[part 1 of 2: package /STLACompositions/Platform_Lin]
AUTOSAR XML (schema 00044)
package /STLACompositions/Platform_Lin
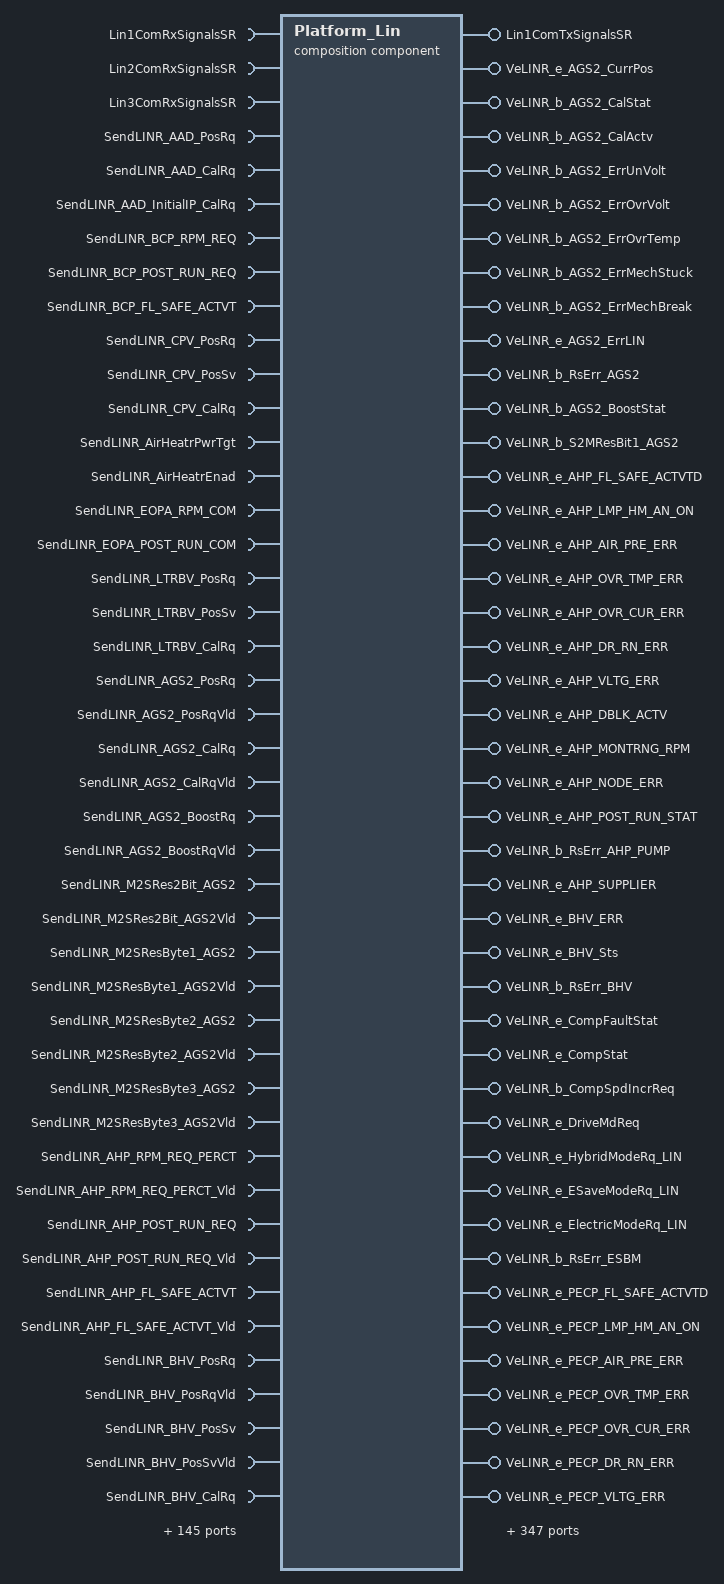
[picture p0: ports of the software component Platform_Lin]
  composition sw component type Platform_Lin: data-type-mapping=ADTtoIDTMapping  # Composition of CAN Communication Components - is a collection of Lin Communication components responsible with the management of the Lin bus and providing an abstraction layer for the Lin data to the application.
    provide port Lin1ComTxSignalsSR: provided-interface=Lin1ComTxSignalsSR
      provided-com-specs:
        data-element=COMTXL_AAD_PosRq_ECM_AAD_DEMAND_Lin1, init-value=constant-reference=COMTXL_AAD_PosRq_ECM_AAD_DEMAND_Lin1_Init
        data-element=COMTXL_AAD_CalRq_ECM_AAD_DEMAND_Lin1, init-value=constant-reference=COMTXL_AAD_CalRq_ECM_AAD_DEMAND_Lin1_Init
        data-element=COMTXL_AAD_InitialIP_CalRq_ECM_AAD_DEMAND_Lin1, init-value=constant-reference=COMTXL_AAD_InitialIP_CalRq_ECM_AAD_DEMAND_Lin1_Init
        data-element=COMTXL_BCP_RPM_REQ_BCP_REQ_Lin1, init-value=constant-reference=COMTXL_BCP_RPM_REQ_BCP_REQ_Lin1_Init
        data-element=COMTXL_BCP_POST_RUN_REQ_BCP_REQ_Lin1, init-value=constant-reference=COMTXL_BCP_POST_RUN_REQ_BCP_REQ_Lin1_Init
        data-element=COMTXL_BCP_FL_SAFE_ACTVT_BCP_REQ_Lin1, init-value=constant-reference=COMTXL_BCP_FL_SAFE_ACTVT_BCP_REQ_Lin1_Init
        data-element=COMTXL_CPV_PosRq_CPV_REQ_Lin1, init-value=constant-reference=COMTXL_CPV_PosRq_CPV_REQ_Lin1_Init
        data-element=COMTXL_CPV_PosSv_CPV_REQ_Lin1, init-value=constant-reference=COMTXL_CPV_PosSv_CPV_REQ_Lin1_Init
        data-element=COMTXL_CPV_CalRq_CPV_REQ_Lin1, init-value=constant-reference=COMTXL_CPV_CalRq_CPV_REQ_Lin1_Init
        data-element=COMTXL_AirHeatrPwrTgt_HVEAHLIN18Fr03_Lin1, init-value=constant-reference=COMTXL_AirHeatrPwrTgt_HVEAHLIN18Fr03_Lin1_Init
        data-element=COMTXL_AirHeatrEnad_HVEAHLIN18Fr03_Lin1, init-value=constant-reference=COMTXL_AirHeatrEnad_HVEAHLIN18Fr03_Lin1_Init
        data-element=COMTXL_EOPA_RPM_COM_EOPA_REQ_Lin1, init-value=constant-reference=COMTXL_EOPA_RPM_COM_EOPA_REQ_Lin1_Init
        data-element=COMTXL_EOPA_POST_RUN_COM_EOPA_REQ_Lin1, init-value=constant-reference=COMTXL_EOPA_POST_RUN_COM_EOPA_REQ_Lin1_Init
        data-element=COMTXL_LTRBV_PosRq_LTRBV_REQ_Lin1, init-value=constant-reference=COMTXL_LTRBV_PosRq_LTRBV_REQ_Lin1_Init
        data-element=COMTXL_LTRBV_PosSv_LTRBV_REQ_Lin1, init-value=constant-reference=COMTXL_LTRBV_PosSv_LTRBV_REQ_Lin1_Init
        data-element=COMTXL_LTRBV_CalRq_LTRBV_REQ_Lin1, init-value=constant-reference=COMTXL_LTRBV_CalRq_LTRBV_REQ_Lin1_Init
        data-element=COMTXL_EEXV_PosRq_EEXV_REQ_Lin1, init-value=constant-reference=COMTXL_EEXV_PosRq_EEXV_REQ_Lin1_Init
        data-element=COMTXL_EEXV_CalCmd_EEXV_REQ_Lin1, init-value=constant-reference=COMTXL_EEXV_CalCmd_EEXV_REQ_Lin1_Init
        data-element=COMTXL_EXVM_PosRq_EXVM_REQ_Lin1, init-value=constant-reference=COMTXL_EXVM_PosRq_EXVM_REQ_Lin1_Init
        data-element=COMTXL_EXVM_CalCmd_EXVM_REQ_Lin1, init-value=constant-reference=COMTXL_EXVM_CalCmd_EXVM_REQ_Lin1_Init
        data-element=COMTXL_Control_TargetPos_FCPS_CoolantValve_Control_Lin1, init-value=constant-reference=COMTXL_Control_TargetPos_FCPS_CoolantValve_Control_Lin1_Init
        data-element=COMTXL_Control_Reserved1_FCPS_CoolantValve_Control_Lin1, init-value=constant-reference=COMTXL_Control_Reserved1_FCPS_CoolantValve_Control_Lin1_Init
        data-element=COMTXL_Control_BlockDetEnbl_FCPS_CoolantValve_Control_Lin1, init-value=constant-reference=COMTXL_Control_BlockDetEnbl_FCPS_CoolantValve_Control_Lin1_Init
        data-element=COMTXL_Control_DiagFunctnValue_FCPS_CoolantValve_Control_Lin1, init-value=constant-reference=COMTXL_Control_DiagFunctnValue_FCPS_CoolantValve_Control_Lin1_Init
        data-element=COMTXL_Control_Reserved{2..6}_FCPS_CoolantValve_Control_Lin1, init-value=constant-reference=COMTXL_Control_Reserved{2..6}_FCPS_CoolantValve_Control_Lin1_Init
    require port Lin1ComRxSignalsSR: required-interface=Lin1ComRxSignalsSR
      required-com-specs:
        data-element=COMRXL_AAD_CurrPos_AAD_ECM_STATUS_Lin1, handle-never-received=true, init-value=constant-reference=COMRXL_AAD_CurrPos_AAD_ECM_STATUS_Lin1_Init
        data-element=COMRXL_AAD_CalStat_AAD_ECM_STATUS_Lin1, handle-never-received=true, init-value=constant-reference=COMRXL_AAD_CalStat_AAD_ECM_STATUS_Lin1_Init
        data-element=COMRXL_AAD_CalActv_AAD_ECM_STATUS_Lin1, handle-never-received=true, init-value=constant-reference=COMRXL_AAD_CalActv_AAD_ECM_STATUS_Lin1_Init
        data-element=COMRXL_AAD_ErrUnVolt_AAD_ECM_STATUS_Lin1, handle-never-received=true, init-value=constant-reference=COMRXL_AAD_ErrUnVolt_AAD_ECM_STATUS_Lin1_Init
        data-element=COMRXL_AAD_ErrOvrVolt_AAD_ECM_STATUS_Lin1, handle-never-received=true, init-value=constant-reference=COMRXL_AAD_ErrOvrVolt_AAD_ECM_STATUS_Lin1_Init
        data-element=COMRXL_AAD_ErrOvrTemp_AAD_ECM_STATUS_Lin1, handle-never-received=true, init-value=constant-reference=COMRXL_AAD_ErrOvrTemp_AAD_ECM_STATUS_Lin1_Init
        data-element=COMRXL_AAD_ErrMechStuck_AAD_ECM_STATUS_Lin1, handle-never-received=true, init-value=constant-reference=COMRXL_AAD_ErrMechStuck_AAD_ECM_STATUS_Lin1_Init
        data-element=COMRXL_AAD_ErrMechBreak_AAD_ECM_STATUS_Lin1, handle-never-received=true, init-value=constant-reference=COMRXL_AAD_ErrMechBreak_AAD_ECM_STATUS_Lin1_Init
        data-element=COMRXL_RsErr_AAD_AAD_ECM_STATUS_Lin1, handle-never-received=true, init-value=constant-reference=COMRXL_RsErr_AAD_AAD_ECM_STATUS_Lin1_Init
        data-element=COMRXL_BCP_RPM_TARGET_BCP_STAT_Lin1, handle-never-received=true, init-value=constant-reference=COMRXL_BCP_RPM_TARGET_BCP_STAT_Lin1_Init
        data-element=COMRXL_BCP_RPM_ACTUAL_BCP_STAT_Lin1, handle-never-received=true, init-value=constant-reference=COMRXL_BCP_RPM_ACTUAL_BCP_STAT_Lin1_Init
        data-element=COMRXL_BCP_VLTG_BCP_STAT_Lin1, handle-never-received=true, init-value=constant-reference=COMRXL_BCP_VLTG_BCP_STAT_Lin1_Init
        data-element=COMRXL_BCP_TEMP_BCP_STAT_Lin1, handle-never-received=true, init-value=constant-reference=COMRXL_BCP_TEMP_BCP_STAT_Lin1_Init
        data-element=COMRXL_BCP_CURR_BCP_STAT_Lin1, handle-never-received=true, init-value=constant-reference=COMRXL_BCP_CURR_BCP_STAT_Lin1_Init
        data-element=COMRXL_BCP_FL_SAFE_ACTVTD_BCP_STAT_Lin1, handle-never-received=true, init-value=constant-reference=COMRXL_BCP_FL_SAFE_ACTVTD_BCP_STAT_Lin1_Init
        data-element=COMRXL_BCP_LMP_HM_AN_ON_BCP_STAT_Lin1, handle-never-received=true, init-value=constant-reference=COMRXL_BCP_LMP_HM_AN_ON_BCP_STAT_Lin1_Init
        data-element=COMRXL_BCP_AIR_PRE_ERR_BCP_STAT_Lin1, handle-never-received=true, init-value=constant-reference=COMRXL_BCP_AIR_PRE_ERR_BCP_STAT_Lin1_Init
        data-element=COMRXL_BCP_OVR_TMP_ERR_BCP_STAT_Lin1, handle-never-received=true, init-value=constant-reference=COMRXL_BCP_OVR_TMP_ERR_BCP_STAT_Lin1_Init
        data-element=COMRXL_BCP_OVR_CUR_ERR_BCP_STAT_Lin1, handle-never-received=true, init-value=constant-reference=COMRXL_BCP_OVR_CUR_ERR_BCP_STAT_Lin1_Init
        data-element=COMRXL_BCP_DR_RN_ERR_BCP_STAT_Lin1, handle-never-received=true, init-value=constant-reference=COMRXL_BCP_DR_RN_ERR_BCP_STAT_Lin1_Init
        data-element=COMRXL_BCP_VLTG_ERR_BCP_STAT_Lin1, handle-never-received=true, init-value=constant-reference=COMRXL_BCP_VLTG_ERR_BCP_STAT_Lin1_Init
        data-element=COMRXL_BCP_DBLK_ACTV_BCP_STAT_Lin1, handle-never-received=true, init-value=constant-reference=COMRXL_BCP_DBLK_ACTV_BCP_STAT_Lin1_Init
        data-element=COMRXL_BCP_MONTRNG_RPM_BCP_STAT_Lin1, handle-never-received=true, init-value=constant-reference=COMRXL_BCP_MONTRNG_RPM_BCP_STAT_Lin1_Init
        data-element=COMRXL_BCP_NODE_ERR_BCP_STAT_Lin1, handle-never-received=true, init-value=constant-reference=COMRXL_BCP_NODE_ERR_BCP_STAT_Lin1_Init
        data-element=COMRXL_BCP_POST_RUN_STAT_BCP_STAT_Lin1, handle-never-received=true, init-value=constant-reference=COMRXL_BCP_POST_RUN_STAT_BCP_STAT_Lin1_Init
        data-element=COMRXL_RsErr_BCP_PUMP_BCP_STAT_Lin1, handle-never-received=true, init-value=constant-reference=COMRXL_RsErr_BCP_PUMP_BCP_STAT_Lin1_Init
        data-element=COMRXL_BCP_VERSION_BCP_VER_Lin1, handle-never-received=true, init-value=constant-reference=COMRXL_BCP_VERSION_BCP_VER_Lin1_Init
        data-element=COMRXL_BCP_SUPPLIER_BCP_VER_Lin1, handle-never-received=true, init-value=constant-reference=COMRXL_BCP_SUPPLIER_BCP_VER_Lin1_Init
        data-element=COMRXL_CPV_PosAct_CPV_STAT_V2_Lin1, handle-never-received=true, init-value=constant-reference=COMRXL_CPV_PosAct_CPV_STAT_V2_Lin1_Init
        data-element=COMRXL_CPV_ERR_CPV_STAT_V2_Lin1, handle-never-received=true, init-value=constant-reference=COMRXL_CPV_ERR_CPV_STAT_V2_Lin1_Init
        data-element=COMRXL_CPV_Sts_CPV_STAT_V2_Lin1, handle-never-received=true, init-value=constant-reference=COMRXL_CPV_Sts_CPV_STAT_V2_Lin1_Init
        data-element=COMRXL_RsErr_CPV_CPV_STAT_V2_Lin1, handle-never-received=true, init-value=constant-reference=COMRXL_RsErr_CPV_CPV_STAT_V2_Lin1_Init
        data-element=COMRXL_AirHeatrICns_HVEAHLIN18Fr01_Lin1, handle-never-received=true, init-value=constant-reference=COMRXL_AirHeatrICns_HVEAHLIN18Fr01_Lin1_Init
        data-element=COMRXL_AirHeatrHVmeas_HVEAHLIN18Fr01_Lin1, handle-never-received=true, init-value=constant-reference=COMRXL_AirHeatrHVmeas_HVEAHLIN18Fr01_Lin1_Init
        data-element=COMRXL_AirHeatrPCBTemp_HVEAHLIN18Fr01_Lin1, handle-never-received=true, init-value=constant-reference=COMRXL_AirHeatrPCBTemp_HVEAHLIN18Fr01_Lin1_Init
        data-element=COMRXL_AirHeatrCoreTemp_HVEAHLIN18Fr01_Lin1, handle-never-received=true, init-value=constant-reference=COMRXL_AirHeatrCoreTemp_HVEAHLIN18Fr01_Lin1_Init
        data-element=COMRXL_RsErr_EAH_HVEAHLIN18Fr02_Lin1, handle-never-received=true, init-value=constant-reference=COMRXL_RsErr_EAH_HVEAHLIN18Fr02_Lin1_Init
        data-element=COMRXL_AirHeatrWarnFltInCom_HVEAHLIN18Fr02_Lin1, handle-never-received=true, init-value=constant-reference=COMRXL_AirHeatrWarnFltInCom_HVEAHLIN18Fr02_Lin1_Init
        data-element=COMRXL_AirHeatrWarnHvOutOfRng_HVEAHLIN18Fr02_Lin1, handle-never-received=true, init-value=constant-reference=COMRXL_AirHeatrWarnHvOutOfRng_HVEAHLIN18Fr02_Lin1_Init
        data-element=COMRXL_AirHeatrWarnULoOutOfRng_HVEAHLIN18Fr02_Lin1, handle-never-received=true, init-value=constant-reference=COMRXL_AirHeatrWarnULoOutOfRng_HVEAHLIN18Fr02_Lin1_Init
        data-element=COMRXL_AirHeatrWarnTmpOvrheatg_HVEAHLIN18Fr02_Lin1, handle-never-received=true, init-value=constant-reference=COMRXL_AirHeatrWarnTmpOvrheatg_HVEAHLIN18Fr02_Lin1_Init
        data-element=COMRXL_AirHeatrWarnICnsOutOfRng_HVEAHLIN18Fr02_Lin1, handle-never-received=true, init-value=constant-reference=COMRXL_AirHeatrWarnICnsOutOfRng_HVEAHLIN18Fr02_Lin1_Init
        data-element=COMRXL_AirHeatrDmgIntHwProtn_HVEAHLIN18Fr02_Lin1, handle-never-received=true, init-value=constant-reference=COMRXL_AirHeatrDmgIntHwProtn_HVEAHLIN18Fr02_Lin1_Init
        data-element=COMRXL_AirHeatrDmgPCBTmpSnsrFlt_HVEAHLIN18Fr02_Lin1, handle-never-received=true, init-value=constant-reference=COMRXL_AirHeatrDmgPCBTmpSnsrFlt_HVEAHLIN18Fr02_Lin1_Init
        data-element=COMRXL_AirHeatrDmgCircForDrvrShoOrOpen_HVEAHLIN18Fr02_Lin1, handle-never-received=true, init-value=constant-reference=COMRXL_AirHeatrDmgCircForDrvrShoOrOpen_HVEAHLIN18Fr02_Lin1_Init
        data-element=COMRXL_AirHeatrDmgHVISnsrFlt_HVEAHLIN18Fr02_Lin1, handle-never-received=true, init-value=constant-reference=COMRXL_AirHeatrDmgHVISnsrFlt_HVEAHLIN18Fr02_Lin1_Init
        data-element=COMRXL_AirHeatrDmgMemErr_HVEAHLIN18Fr02_Lin1, handle-never-received=true, init-value=constant-reference=COMRXL_AirHeatrDmgMemErr_HVEAHLIN18Fr02_Lin1_Init
        data-element=COMRXL_AirHeatrDmgHtrCoreTmpSnsrFlt_HVEAHLIN18Fr02_Lin1, handle-never-received=true, init-value=constant-reference=COMRXL_AirHeatrDmgHtrCoreTmpSnsrFlt_HVEAHLIN18Fr02_Lin1_Init
        data-element=COMRXL_AirHeatrWarnPCBOvrTmp_HVEAHLIN18Fr02_Lin1, handle-never-received=true, init-value=constant-reference=COMRXL_AirHeatrWarnPCBOvrTmp_HVEAHLIN18Fr02_Lin1_Init
        data-element=COMRXL_AirHeatrWarnHtrCoreOvrTmp_HVEAHLIN18Fr02_Lin1, handle-never-received=true, init-value=constant-reference=COMRXL_AirHeatrWarnHtrCoreOvrTmp_HVEAHLIN18Fr02_Lin1_Init
        data-element=COMRXL_EOPA_RPM_TGT_EOPA_STAT_Lin1, handle-never-received=true, init-value=constant-reference=COMRXL_EOPA_RPM_TGT_EOPA_STAT_Lin1_Init
        data-element=COMRXL_EOPA_RPM_ACTL_EOPA_STAT_Lin1, handle-never-received=true, init-value=constant-reference=COMRXL_EOPA_RPM_ACTL_EOPA_STAT_Lin1_Init
        data-element=COMRXL_EOPA_VLTG_EOPA_STAT_Lin1, handle-never-received=true, init-value=constant-reference=COMRXL_EOPA_VLTG_EOPA_STAT_Lin1_Init
        data-element=COMRXL_EOPA_TEMP_EOPA_STAT_Lin1, handle-never-received=true, init-value=constant-reference=COMRXL_EOPA_TEMP_EOPA_STAT_Lin1_Init
        data-element=COMRXL_EOPA_CURR_EOPA_STAT_Lin1, handle-never-received=true, init-value=constant-reference=COMRXL_EOPA_CURR_EOPA_STAT_Lin1_Init
        data-element=COMRXL_EOPA_LOW_TMP_STAT_EOPA_STAT_Lin1, handle-never-received=true, init-value=constant-reference=COMRXL_EOPA_LOW_TMP_STAT_EOPA_STAT_Lin1_Init
        data-element=COMRXL_EOPA_MONTRNG_RPM_EOPA_STAT_Lin1, handle-never-received=true, init-value=constant-reference=COMRXL_EOPA_MONTRNG_RPM_EOPA_STAT_Lin1_Init
        data-element=COMRXL_EOPA_LMP_HM_AN_ON_EOPA_STAT_Lin1, handle-never-received=true, init-value=constant-reference=COMRXL_EOPA_LMP_HM_AN_ON_EOPA_STAT_Lin1_Init
        data-element=COMRXL_EOPA_OV_TMP_ER_EOPA_STAT_Lin1, handle-never-received=true, init-value=constant-reference=COMRXL_EOPA_OV_TMP_ER_EOPA_STAT_Lin1_Init
        data-element=COMRXL_EOPA_OV_CUR_ER_EOPA_STAT_Lin1, handle-never-received=true, init-value=constant-reference=COMRXL_EOPA_OV_CUR_ER_EOPA_STAT_Lin1_Init
        data-element=COMRXL_EOPA_DR_RN_ER_EOPA_STAT_Lin1, handle-never-received=true, init-value=constant-reference=COMRXL_EOPA_DR_RN_ER_EOPA_STAT_Lin1_Init
        data-element=COMRXL_EOPA_VLTG_ER_EOPA_STAT_Lin1, handle-never-received=true, init-value=constant-reference=COMRXL_EOPA_VLTG_ER_EOPA_STAT_Lin1_Init
        data-element=COMRXL_EOPA_Stall_Event_EOPA_STAT_Lin1, handle-never-received=true, init-value=constant-reference=COMRXL_EOPA_Stall_Event_EOPA_STAT_Lin1_Init
        data-element=COMRXL_EOPA_POST_RUN_STAT_EOPA_STAT_Lin1, handle-never-received=true, init-value=constant-reference=COMRXL_EOPA_POST_RUN_STAT_EOPA_STAT_Lin1_Init
        data-element=COMRXL_RsErr_EOPA_EOPA_STAT_Lin1, handle-never-received=true, init-value=constant-reference=COMRXL_RsErr_EOPA_EOPA_STAT_Lin1_Init
        data-element=COMRXL_EOPA_OIL_TEMP_EOPA_STAT2_Lin1, handle-never-received=true, init-value=constant-reference=COMRXL_EOPA_OIL_TEMP_EOPA_STAT2_Lin1_Init
        data-element=COMRXL_EOPA_HW_VER_EOPA_VER_Lin1, handle-never-received=true, init-value=constant-reference=COMRXL_EOPA_HW_VER_EOPA_VER_Lin1_Init
        data-element=COMRXL_EOPA_SW_VER_EOPA_VER_Lin1, handle-never-received=true, init-value=constant-reference=COMRXL_EOPA_SW_VER_EOPA_VER_Lin1_Init
        data-element=COMRXL_LTRBV_PosAct_LTRBV_STAT_Lin1, handle-never-received=true, init-value=constant-reference=COMRXL_LTRBV_PosAct_LTRBV_STAT_Lin1_Init
        data-element=COMRXL_LTRBV_ERR_LTRBV_STAT_Lin1, handle-never-received=true, init-value=constant-reference=COMRXL_LTRBV_ERR_LTRBV_STAT_Lin1_Init
        data-element=COMRXL_LTRBV_MotorVolt_LTRBV_STAT_Lin1, handle-never-received=true, init-value=constant-reference=COMRXL_LTRBV_MotorVolt_LTRBV_STAT_Lin1_Init
        data-element=COMRXL_LTRBV_Sts_LTRBV_STAT_Lin1, handle-never-received=true, init-value=constant-reference=COMRXL_LTRBV_Sts_LTRBV_STAT_Lin1_Init
        data-element=COMRXL_RsErr_LTRBV_LTRBV_STAT_Lin1, handle-never-received=true, init-value=constant-reference=COMRXL_RsErr_LTRBV_LTRBV_STAT_Lin1_Init
        data-element=COMRXL_CPV_MotorVolt_CPV_STAT_V2_Lin1, handle-never-received=true, init-value=constant-reference=COMRXL_CPV_MotorVolt_CPV_STAT_V2_Lin1_Init
        data-element=COMRXL_CPV_CalStat_CPV_STAT_V2_Lin1, handle-never-received=true, init-value=constant-reference=COMRXL_CPV_CalStat_CPV_STAT_V2_Lin1_Init
        data-element=COMRXL_AirHeatrSts_HVEAHLIN18Fr01_Lin1, handle-never-received=true, init-value=constant-reference=COMRXL_AirHeatrSts_HVEAHLIN18Fr01_Lin1_Init
        data-element=COMRXL_AirHeatrPwrCns_HVEAHLIN18Fr01_Lin1, handle-never-received=true, init-value=constant-reference=COMRXL_AirHeatrPwrCns_HVEAHLIN18Fr01_Lin1_Init
        data-element=COMRXL_EEXV_PosAct_EEXV_STAT_Lin1, handle-never-received=true, init-value=constant-reference=COMRXL_EEXV_PosAct_EEXV_STAT_Lin1_Init
        data-element=COMRXL_EEXV_CalStat_EEXV_STAT_Lin1, handle-never-received=true, init-value=constant-reference=COMRXL_EEXV_CalStat_EEXV_STAT_Lin1_Init
        data-element=COMRXL_EEXV_CalRq_EEXV_STAT_Lin1, handle-never-received=true, init-value=constant-reference=COMRXL_EEXV_CalRq_EEXV_STAT_Lin1_Init
        data-element=COMRXL_RsErr_EEXV_EEXV_STAT_Lin1, handle-never-received=true, init-value=constant-reference=COMRXL_RsErr_EEXV_EEXV_STAT_Lin1_Init
        data-element=COMRXL_EEXV_Sts_EEXV_STAT_Lin1, handle-never-received=true, init-value=constant-reference=COMRXL_EEXV_Sts_EEXV_STAT_Lin1_Init
        data-element=COMRXL_EEXV_ERR_EEXV_STAT_Lin1, handle-never-received=true, init-value=constant-reference=COMRXL_EEXV_ERR_EEXV_STAT_Lin1_Init
        data-element=COMRXL_EEXV_SupplyVolt_EEXV_STAT_Lin1, handle-never-received=true, init-value=constant-reference=COMRXL_EEXV_SupplyVolt_EEXV_STAT_Lin1_Init
        data-element=COMRXL_EEXV_Refrigerant_Pressure_EEXV_STAT_Lin1, handle-never-received=true, init-value=constant-reference=COMRXL_EEXV_Refrigerant_Pressure_EEXV_STAT_Lin1_Init
        data-element=COMRXL_EEXV_Board_Temp_EEXV_STAT_Lin1, handle-never-received=true, init-value=constant-reference=COMRXL_EEXV_Board_Temp_EEXV_STAT_Lin1_Init
        data-element=COMRXL_EEXV_Refrigerant_Temp_EEXV_STAT_Lin1, handle-never-received=true, init-value=constant-reference=COMRXL_EEXV_Refrigerant_Temp_EEXV_STAT_Lin1_Init
        data-element=COMRXL_EXVM_PosAct_EXVM_STAT_Lin1, handle-never-received=true, init-value=constant-reference=COMRXL_EXVM_PosAct_EXVM_STAT_Lin1_Init
        data-element=COMRXL_EXVM_CalStat_EXVM_STAT_Lin1, handle-never-received=true, init-value=constant-reference=COMRXL_EXVM_CalStat_EXVM_STAT_Lin1_Init
        data-element=COMRXL_EXVM_CalRq_EXVM_STAT_Lin1, handle-never-received=true, init-value=constant-reference=COMRXL_EXVM_CalRq_EXVM_STAT_Lin1_Init
        data-element=COMRXL_RsErr_EXVM_EXVM_STAT_Lin1, handle-never-received=true, init-value=constant-reference=COMRXL_RsErr_EXVM_EXVM_STAT_Lin1_Init
        data-element=COMRXL_EXVM_Sts_EXVM_STAT_Lin1, handle-never-received=true, init-value=constant-reference=COMRXL_EXVM_Sts_EXVM_STAT_Lin1_Init
        data-element=COMRXL_EXVM_ERR_EXVM_STAT_Lin1, handle-never-received=true, init-value=constant-reference=COMRXL_EXVM_ERR_EXVM_STAT_Lin1_Init
        data-element=COMRXL_EXVM_SupplyVolt_EXVM_STAT_Lin1, handle-never-received=true, init-value=constant-reference=COMRXL_EXVM_SupplyVolt_EXVM_STAT_Lin1_Init
        data-element=COMRXL_EXVM_Refrigerant_Pressure_EXVM_STAT_Lin1, handle-never-received=true, init-value=constant-reference=COMRXL_EXVM_Refrigerant_Pressure_EXVM_STAT_Lin1_Init
        data-element=COMRXL_EXVM_Board_Temp_EXVM_STAT_Lin1, handle-never-received=true, init-value=constant-reference=COMRXL_EXVM_Board_Temp_EXVM_STAT_Lin1_Init
        data-element=COMRXL_EXVM_Refrigerant_Temp_EXVM_STAT_Lin1, handle-never-received=true, init-value=constant-reference=COMRXL_EXVM_Refrigerant_Temp_EXVM_STAT_Lin1_Init
        data-element=COMRXL_LTRBV_CalStat_LTRBV_STAT_Lin1, handle-never-received=true, init-value=constant-reference=COMRXL_LTRBV_CalStat_LTRBV_STAT_Lin1_Init
        data-element=COMRXL_CoolantValve_ErrLinCom_CoolantValve_Com_Lin1, handle-never-received=true, init-value=constant-reference=COMRXL_CoolantValve_ErrLinCom_CoolantValve_Com_Lin1_Init
        data-element=COMRXL_CoolantValve_ErrPosition_CoolantValve_Com_Lin1, handle-never-received=true, init-value=constant-reference=COMRXL_CoolantValve_ErrPosition_CoolantValve_Com_Lin1_Init
        data-element=COMRXL_CoolantValve_SelfCalReq_CoolantValve_Com_Lin1, handle-never-received=true, init-value=constant-reference=COMRXL_CoolantValve_SelfCalReq_CoolantValve_Com_Lin1_Init
        data-element=COMRXL_CoolantValve_SystemState_CoolantValve_Com_Lin1, handle-never-received=true, init-value=constant-reference=COMRXL_CoolantValve_SystemState_CoolantValve_Com_Lin1_Init
        data-element=COMRXL_CoolantValve_EcuVoltage_CoolantValve_Com_Lin1, handle-never-received=true, init-value=constant-reference=COMRXL_CoolantValve_EcuVoltage_CoolantValve_Com_Lin1_Init
        data-element=COMRXL_CoolantValve_ActuatorPositionTrgt_CoolantValve_Com_Lin1, handle-never-received=true, init-value=constant-reference=COMRXL_CoolantValve_ActuatorPositionTrgt_CoolantValve_Com_Lin1_Init
        data-element=COMRXL_CoolantValve_ActuatorPositionAct_CoolantValve_Com_Lin1, handle-never-received=true, init-value=constant-reference=COMRXL_CoolantValve_ActuatorPositionAct_CoolantValve_Com_Lin1_Init
        data-element=COMRXL_CoolantValve_EcuTemperatur_CoolantValve_Com_Lin1, handle-never-received=true, init-value=constant-reference=COMRXL_CoolantValve_EcuTemperatur_CoolantValve_Com_Lin1_Init
        data-element=COMRXL_CoolantValve_Err_Motor_CoolantValve_Com_Lin1, handle-never-received=true, init-value=constant-reference=COMRXL_CoolantValve_Err_Motor_CoolantValve_Com_Lin1_Init
        data-element=COMRXL_CoolantValve_Err_Voltage_CoolantValve_Com_Lin1, handle-never-received=true, init-value=constant-reference=COMRXL_CoolantValve_Err_Voltage_CoolantValve_Com_Lin1_Init
        data-element=COMRXL_CoolantValve_Err_Ecu_CoolantValve_Com_Lin1, handle-never-received=true, init-value=constant-reference=COMRXL_CoolantValve_Err_Ecu_CoolantValve_Com_Lin1_Init
        data-element=COMRXL_CoolantValve_ResponseError_CoolantValve_Com_Lin1, handle-never-received=true, init-value=constant-reference=COMRXL_CoolantValve_ResponseError_CoolantValve_Com_Lin1_Init
    50 x provide port:
      VeLINR_e_AGS2_CurrPos: nonqueued-sender-com-spec{data-element=VeLINR_e_AGS2_CurrPos, init-value=VeLINR_e_AGS2_CurrPosValue:0}, provided-interface=VeLINR_e_AGS2_CurrPos
      VeLINR_b_AGS2_CalStat: nonqueued-sender-com-spec{data-element=VeLINR_b_AGS2_CalStat, init-value=VeLINR_b_AGS2_CalStatValue:0}, provided-interface=VeLINR_b_AGS2_CalStat
      VeLINR_b_AGS2_CalActv: nonqueued-sender-com-spec{data-element=VeLINR_b_AGS2_CalActv, init-value=VeLINR_b_AGS2_CalActvValue:0}, provided-interface=VeLINR_b_AGS2_CalActv
      VeLINR_b_AGS2_ErrUnVolt: nonqueued-sender-com-spec{data-element=VeLINR_b_AGS2_ErrUnVolt, init-value=VeLINR_b_AGS2_ErrUnVoltValue:0}, provided-interface=VeLINR_b_AGS2_ErrUnVolt
      VeLINR_b_AGS2_ErrOvrVolt: nonqueued-sender-com-spec{data-element=VeLINR_b_AGS2_ErrOvrVolt, init-value=VeLINR_b_AGS2_ErrOvrVoltValue:0}, provided-interface=VeLINR_b_AGS2_ErrOvrVolt
      VeLINR_b_AGS2_ErrOvrTemp: nonqueued-sender-com-spec{data-element=VeLINR_b_AGS2_ErrOvrTemp, init-value=VeLINR_b_AGS2_ErrOvrTempValue:0}, provided-interface=VeLINR_b_AGS2_ErrOvrTemp
      VeLINR_b_AGS2_ErrMechStuck: nonqueued-sender-com-spec{data-element=VeLINR_b_AGS2_ErrMechStuck, init-value=VeLINR_b_AGS2_ErrMechStuckValue:0}, provided-interface=VeLINR_b_AGS2_ErrMechStuck
      VeLINR_b_AGS2_ErrMechBreak: nonqueued-sender-com-spec{data-element=VeLINR_b_AGS2_ErrMechBreak, init-value=VeLINR_b_AGS2_ErrMechBreakValue:0}, provided-interface=VeLINR_b_AGS2_ErrMechBreak
      VeLINR_e_AGS2_ErrLIN: nonqueued-sender-com-spec{data-element=VeLINR_e_AGS2_ErrLIN, init-value=VeLINR_e_AGS2_ErrLINValue:0}, provided-interface=VeLINR_e_AGS2_ErrLIN
      VeLINR_b_RsErr_AGS2: nonqueued-sender-com-spec{data-element=VeLINR_b_RsErr_AGS2, init-value=VeLINR_b_RsErr_AGS2Value:0}, provided-interface=VeLINR_b_RsErr_AGS2
      VeLINR_b_AGS2_BoostStat: nonqueued-sender-com-spec{data-element=VeLINR_b_AGS2_BoostStat, init-value=VeLINR_b_AGS2_BoostStatValue:0}, provided-interface=VeLINR_b_AGS2_BoostStat
      VeLINR_b_S2MResBit1_AGS2: nonqueued-sender-com-spec{data-element=VeLINR_b_S2MResBit1_AGS2, init-value=VeLINR_b_S2MResBit1_AGS2Value:0}, provided-interface=VeLINR_b_S2MResBit1_AGS2
      VeLINR_e_AHP_FL_SAFE_ACTVTD: nonqueued-sender-com-spec{data-element=VeLINR_e_AHP_FL_SAFE_ACTVTD, init-value=VeLINR_e_AHP_FL_SAFE_ACTVTDValue:3}, provided-interface=VeLINR_e_AHP_FL_SAFE_ACTVTD
      VeLINR_e_AHP_LMP_HM_AN_ON: nonqueued-sender-com-spec{data-element=VeLINR_e_AHP_LMP_HM_AN_ON, init-value=VeLINR_e_AHP_LMP_HM_AN_ONValue:3}, provided-interface=VeLINR_e_AHP_LMP_HM_AN_ON
      VeLINR_e_AHP_AIR_PRE_ERR: nonqueued-sender-com-spec{data-element=VeLINR_e_AHP_AIR_PRE_ERR, init-value=VeLINR_e_AHP_AIR_PRE_ERRValue:3}, provided-interface=VeLINR_e_AHP_AIR_PRE_ERR
      VeLINR_e_AHP_OVR_TMP_ERR: nonqueued-sender-com-spec{data-element=VeLINR_e_AHP_OVR_TMP_ERR, init-value=VeLINR_e_AHP_OVR_TMP_ERRValue:3}, provided-interface=VeLINR_e_AHP_OVR_TMP_ERR
      VeLINR_e_AHP_OVR_CUR_ERR: nonqueued-sender-com-spec{data-element=VeLINR_e_AHP_OVR_CUR_ERR, init-value=VeLINR_e_AHP_OVR_CUR_ERRValue:3}, provided-interface=VeLINR_e_AHP_OVR_CUR_ERR
      VeLINR_e_AHP_DR_RN_ERR: nonqueued-sender-com-spec{data-element=VeLINR_e_AHP_DR_RN_ERR, init-value=VeLINR_e_AHP_DR_RN_ERRValue:3}, provided-interface=VeLINR_e_AHP_DR_RN_ERR
      VeLINR_e_AHP_VLTG_ERR: nonqueued-sender-com-spec{data-element=VeLINR_e_AHP_VLTG_ERR, init-value=VeLINR_e_AHP_VLTG_ERRValue:3}, provided-interface=VeLINR_e_AHP_VLTG_ERR
      VeLINR_e_AHP_DBLK_ACTV: nonqueued-sender-com-spec{data-element=VeLINR_e_AHP_DBLK_ACTV, init-value=VeLINR_e_AHP_DBLK_ACTVValue:3}, provided-interface=VeLINR_e_AHP_DBLK_ACTV
      VeLINR_e_AHP_MONTRNG_RPM: nonqueued-sender-com-spec{data-element=VeLINR_e_AHP_MONTRNG_RPM, init-value=VeLINR_e_AHP_MONTRNG_RPMValue:3}, provided-interface=VeLINR_e_AHP_MONTRNG_RPM
      VeLINR_e_AHP_NODE_ERR: nonqueued-sender-com-spec{data-element=VeLINR_e_AHP_NODE_ERR, init-value=VeLINR_e_AHP_NODE_ERRValue:3}, provided-interface=VeLINR_e_AHP_NODE_ERR
      VeLINR_e_AHP_POST_RUN_STAT: nonqueued-sender-com-spec{data-element=VeLINR_e_AHP_POST_RUN_STAT, init-value=VeLINR_e_AHP_POST_RUN_STATValue:7}, provided-interface=VeLINR_e_AHP_POST_RUN_STAT
      VeLINR_b_RsErr_AHP_PUMP: nonqueued-sender-com-spec{data-element=VeLINR_b_RsErr_AHP_PUMP, init-value=VeLINR_b_RsErr_AHP_PUMPValue:0}, provided-interface=VeLINR_b_RsErr_AHP_PUMP
      VeLINR_e_AHP_SUPPLIER: nonqueued-sender-com-spec{data-element=VeLINR_e_AHP_SUPPLIER, init-value=VeLINR_e_AHP_SUPPLIERValue:0}, provided-interface=VeLINR_e_AHP_SUPPLIER
      VeLINR_e_BHV_ERR: nonqueued-sender-com-spec{data-element=VeLINR_e_BHV_ERR, init-value=VeLINR_e_BHV_ERRValue:0}, provided-interface=VeLINR_e_BHV_ERR
      VeLINR_e_BHV_Sts: nonqueued-sender-com-spec{data-element=VeLINR_e_BHV_Sts, init-value=VeLINR_e_BHV_StsValue:0}, provided-interface=VeLINR_e_BHV_Sts
      VeLINR_b_RsErr_BHV: nonqueued-sender-com-spec{data-element=VeLINR_b_RsErr_BHV, init-value=VeLINR_b_RsErr_BHVValue:0}, provided-interface=VeLINR_b_RsErr_BHV
      VeLINR_e_CompFaultStat: nonqueued-sender-com-spec{data-element=VeLINR_e_CompFaultStat, init-value=VeLINR_e_CompFaultStatValue:0}, provided-interface=VeLINR_e_CompFaultStat
      VeLINR_e_CompStat: nonqueued-sender-com-spec{data-element=VeLINR_e_CompStat, init-value=VeLINR_e_CompStatValue:0}, provided-interface=VeLINR_e_CompStat
      VeLINR_b_CompSpdIncrReq: nonqueued-sender-com-spec{data-element=VeLINR_b_CompSpdIncrReq, init-value=VeLINR_b_CompSpdIncrReqValue:0}, provided-interface=VeLINR_b_CompSpdIncrReq
      VeLINR_e_DriveMdReq: nonqueued-sender-com-spec{data-element=VeLINR_e_DriveMdReq, init-value=VeLINR_e_DriveMdReqValue:0}, provided-interface=VeLINR_e_DriveMdReq
      VeLINR_e_HybridModeRq_LIN: nonqueued-sender-com-spec{data-element=VeLINR_e_HybridModeRq_LIN, init-value=VeLINR_e_HybridModeRq_LINValue:0}, provided-interface=VeLINR_e_HybridModeRq_LIN
      VeLINR_e_ESaveModeRq_LIN: nonqueued-sender-com-spec{data-element=VeLINR_e_ESaveModeRq_LIN, init-value=VeLINR_e_ESaveModeRq_LINValue:0}, provided-interface=VeLINR_e_ESaveModeRq_LIN
      VeLINR_e_ElectricModeRq_LIN: nonqueued-sender-com-spec{data-element=VeLINR_e_ElectricModeRq_LIN, init-value=VeLINR_e_ElectricModeRq_LINValue:0}, provided-interface=VeLINR_e_ElectricModeRq_LIN
      VeLINR_b_RsErr_ESBM: nonqueued-sender-com-spec{data-element=VeLINR_b_RsErr_ESBM, init-value=VeLINR_b_RsErr_ESBMValue:0}, provided-interface=VeLINR_b_RsErr_ESBM
      VeLINR_e_PECP_FL_SAFE_ACTVTD: nonqueued-sender-com-spec{data-element=VeLINR_e_PECP_FL_SAFE_ACTVTD, init-value=VeLINR_e_PECP_FL_SAFE_ACTVTDValue:3}, provided-interface=VeLINR_e_PECP_FL_SAFE_ACTVTD
      VeLINR_e_PECP_LMP_HM_AN_ON: nonqueued-sender-com-spec{data-element=VeLINR_e_PECP_LMP_HM_AN_ON, init-value=VeLINR_e_PECP_LMP_HM_AN_ONValue:3}, provided-interface=VeLINR_e_PECP_LMP_HM_AN_ON
      VeLINR_e_PECP_AIR_PRE_ERR: nonqueued-sender-com-spec{data-element=VeLINR_e_PECP_AIR_PRE_ERR, init-value=VeLINR_e_PECP_AIR_PRE_ERRValue:3}, provided-interface=VeLINR_e_PECP_AIR_PRE_ERR
      VeLINR_e_PECP_OVR_TMP_ERR: nonqueued-sender-com-spec{data-element=VeLINR_e_PECP_OVR_TMP_ERR, init-value=VeLINR_e_PECP_OVR_TMP_ERRValue:3}, provided-interface=VeLINR_e_PECP_OVR_TMP_ERR
      VeLINR_e_PECP_OVR_CUR_ERR: nonqueued-sender-com-spec{data-element=VeLINR_e_PECP_OVR_CUR_ERR, init-value=VeLINR_e_PECP_OVR_CUR_ERRValue:3}, provided-interface=VeLINR_e_PECP_OVR_CUR_ERR
      VeLINR_e_PECP_DR_RN_ERR: nonqueued-sender-com-spec{data-element=VeLINR_e_PECP_DR_RN_ERR, init-value=VeLINR_e_PECP_DR_RN_ERRValue:3}, provided-interface=VeLINR_e_PECP_DR_RN_ERR
      VeLINR_e_PECP_VLTG_ERR: nonqueued-sender-com-spec{data-element=VeLINR_e_PECP_VLTG_ERR, init-value=VeLINR_e_PECP_VLTG_ERRValue:3}, provided-interface=VeLINR_e_PECP_VLTG_ERR
      VeLINR_e_PECP_DBLK_ACTV: nonqueued-sender-com-spec{data-element=VeLINR_e_PECP_DBLK_ACTV, init-value=VeLINR_e_PECP_DBLK_ACTVValue:3}, provided-interface=VeLINR_e_PECP_DBLK_ACTV
      VeLINR_e_PECP_MONTRNG_RPM: nonqueued-sender-com-spec{data-element=VeLINR_e_PECP_MONTRNG_RPM, init-value=VeLINR_e_PECP_MONTRNG_RPMValue:3}, provided-interface=VeLINR_e_PECP_MONTRNG_RPM
      VeLINR_e_PECP_NODE_ERR: nonqueued-sender-com-spec{data-element=VeLINR_e_PECP_NODE_ERR, init-value=VeLINR_e_PECP_NODE_ERRValue:3}, provided-interface=VeLINR_e_PECP_NODE_ERR
      VeLINR_e_PECP_POST_RUN_STAT: nonqueued-sender-com-spec{data-element=VeLINR_e_PECP_POST_RUN_STAT, init-value=VeLINR_e_PECP_POST_RUN_STATValue:7}, provided-interface=VeLINR_e_PECP_POST_RUN_STAT
      VeLINR_b_RsErr_PECP_PUMP: nonqueued-sender-com-spec{data-element=VeLINR_b_RsErr_PECP_PUMP, init-value=VeLINR_b_RsErr_PECP_PUMPValue:0}, provided-interface=VeLINR_b_RsErr_PECP_PUMP
      VeLINR_e_PECP_SUPPLIER: nonqueued-sender-com-spec{data-element=VeLINR_e_PECP_SUPPLIER, init-value=VeLINR_e_PECP_SUPPLIERValue:0}, provided-interface=VeLINR_e_PECP_SUPPLIER
      Lin2ComTxSignalsSR: provided-interface=Lin2ComTxSignalsSR
        provided-com-specs:
          data-element=COMTXL_AGS2_PosRq_ECM_AGS2_DEMAND_Lin2, init-value=constant-reference=COMTXL_AGS2_PosRq_ECM_AGS2_DEMAND_Lin2_Init
          data-element=COMTXL_AGS2_CalRq_ECM_AGS2_DEMAND_Lin2, init-value=constant-reference=COMTXL_AGS2_CalRq_ECM_AGS2_DEMAND_Lin2_Init
          data-element=COMTXL_AGS2_BoostRq_ECM_AGS2_DEMAND_Lin2, init-value=constant-reference=COMTXL_AGS2_BoostRq_ECM_AGS2_DEMAND_Lin2_Init
          data-element=COMTXL_M2SRes2Bit_AGS2_ECM_AGS2_DEMAND_Lin2, init-value=constant-reference=COMTXL_M2SRes2Bit_AGS2_ECM_AGS2_DEMAND_Lin2_Init
          data-element=COMTXL_M2SResByte{1..3}_AGS2_ECM_AGS2_DEMAND_Lin2, init-value=constant-reference=COMTXL_M2SResByte{1..3}_AGS2_ECM_AGS2_DEMAND_Lin2_Init
          data-element=COMTXL_AHP_RPM_REQ_PERCT_AHP_REQ_GLOBAL_Lin2, init-value=constant-reference=COMTXL_AHP_RPM_REQ_PERCT_AHP_REQ_GLOBAL_Lin2_Init
          data-element=COMTXL_AHP_POST_RUN_REQ_AHP_REQ_GLOBAL_Lin2, init-value=constant-reference=COMTXL_AHP_POST_RUN_REQ_AHP_REQ_GLOBAL_Lin2_Init
          data-element=COMTXL_AHP_FL_SAFE_ACTVT_AHP_REQ_GLOBAL_Lin2, init-value=constant-reference=COMTXL_AHP_FL_SAFE_ACTVT_AHP_REQ_GLOBAL_Lin2_Init
          data-element=COMTXL_BHV_PosRq_BHV_REQ_Lin2, init-value=constant-reference=COMTXL_BHV_PosRq_BHV_REQ_Lin2_Init
          data-element=COMTXL_BHV_PosSv_BHV_REQ_Lin2, init-value=constant-reference=COMTXL_BHV_PosSv_BHV_REQ_Lin2_Init
          data-element=COMTXL_BHV_CalRq_BHV_REQ_Lin2, init-value=constant-reference=COMTXL_BHV_CalRq_BHV_REQ_Lin2_Init
          data-element=COMTXL_CompressorSpdReq_COMP_REQ_Lin2, init-value=constant-reference=COMTXL_CompressorSpdReq_COMP_REQ_Lin2_Init
          data-element=COMTXL_CompEnable_COMP_REQ_Lin2, init-value=constant-reference=COMTXL_CompEnable_COMP_REQ_Lin2_Init
          data-element=COMTXL_DriveEcohybridLmp_MASTER_ESBM_1_Lin2, init-value=constant-reference=COMTXL_DriveEcohybridLmp_MASTER_ESBM_1_Lin2_Init
          data-element=COMTXL_DriveElectricLmp_MASTER_ESBM_1_Lin2, init-value=constant-reference=COMTXL_DriveElectricLmp_MASTER_ESBM_1_Lin2_Init
          data-element=COMTXL_DriveESaveLmp_MASTER_ESBM_1_Lin2, init-value=constant-reference=COMTXL_DriveESaveLmp_MASTER_ESBM_1_Lin2_Init
          data-element=COMTXL_DriveSportHybridLmp_MASTER_ESBM_1_Lin2, init-value=constant-reference=COMTXL_DriveSportHybridLmp_MASTER_ESBM_1_Lin2_Init
          data-element=COMTXL_PanelIntensitySts_MASTER_ESBM_1_Lin2, init-value=constant-reference=COMTXL_PanelIntensitySts_MASTER_ESBM_1_Lin2_Init
          data-element=COMTXL_DAY_LGT_MD_MASTER_ESBM_1_Lin2, init-value=constant-reference=COMTXL_DAY_LGT_MD_MASTER_ESBM_1_Lin2_Init
          data-element=COMTXL_PECP_RPM_REQ_PERCT_PECP_REQ_GLOBAL_Lin2, init-value=constant-reference=COMTXL_PECP_RPM_REQ_PERCT_PECP_REQ_GLOBAL_Lin2_Init
          data-element=COMTXL_PECP_POST_RUN_REQ_PECP_REQ_GLOBAL_Lin2, init-value=constant-reference=COMTXL_PECP_POST_RUN_REQ_PECP_REQ_GLOBAL_Lin2_Init
          data-element=COMTXL_PECP_FL_SAFE_ACTVT_PECP_REQ_GLOBAL_Lin2, init-value=constant-reference=COMTXL_PECP_FL_SAFE_ACTVT_PECP_REQ_GLOBAL_Lin2_Init
          data-element=COMTXL_PowerPanel_LED_A_Command_PowerPanel_REQ_Lin2, init-value=constant-reference=COMTXL_PowerPanel_LED_A_Command_PowerPanel_REQ_Lin2_Init
          data-element=COMTXL_PowerPanel_LED_B_Command_PowerPanel_REQ_Lin2, init-value=constant-reference=COMTXL_PowerPanel_LED_B_Command_PowerPanel_REQ_Lin2_Init
          data-element=COMTXL_DAY_LGT_MD_PowerPanel_PowerPanel_REQ_Lin2, init-value=constant-reference=COMTXL_DAY_LGT_MD_PowerPanel_PowerPanel_REQ_Lin2_Init
          data-element=COMTXL_OEXV_PosRq_OEXV_REQ_Lin2, init-value=constant-reference=COMTXL_OEXV_PosRq_OEXV_REQ_Lin2_Init
          data-element=COMTXL_OEXV_CalCmd_OEXV_REQ_Lin2, init-value=constant-reference=COMTXL_OEXV_CalCmd_OEXV_REQ_Lin2_Init
          data-element=COMTXL_PowerPanel_LED_C_Command_PowerPanel_REQ_Lin2, init-value=constant-reference=COMTXL_PowerPanel_LED_C_Command_PowerPanel_REQ_Lin2_Init
          data-element=COMTXL_PowerPanel_LED_A_Color_Command_PowerPanel_REQ_Lin2, init-value=constant-reference=COMTXL_PowerPanel_LED_A_Color_Command_PowerPanel_REQ_Lin2_Init
          data-element=COMTXL_PowerPanel_LED_B_Color_Command_PowerPanel_REQ_Lin2, init-value=constant-reference=COMTXL_PowerPanel_LED_B_Color_Command_PowerPanel_REQ_Lin2_Init
          data-element=COMTXL_PowerPanel_LED_C_Color_Command_PowerPanel_REQ_Lin2, init-value=constant-reference=COMTXL_PowerPanel_LED_C_Color_Command_PowerPanel_REQ_Lin2_Init
    require port Lin2ComRxSignalsSR: required-interface=Lin2ComRxSignalsSR
      required-com-specs:
        data-element=COMRXL_AGS2_CurrPos_AGS2_ECM_STATUS_Lin2, handle-never-received=true, init-value=constant-reference=COMRXL_AGS2_CurrPos_AGS2_ECM_STATUS_Lin2_Init
        data-element=COMRXL_AGS2_CalStat_AGS2_ECM_STATUS_Lin2, handle-never-received=true, init-value=constant-reference=COMRXL_AGS2_CalStat_AGS2_ECM_STATUS_Lin2_Init
        data-element=COMRXL_AGS2_CalActv_AGS2_ECM_STATUS_Lin2, handle-never-received=true, init-value=constant-reference=COMRXL_AGS2_CalActv_AGS2_ECM_STATUS_Lin2_Init
        data-element=COMRXL_AGS2_ErrUnVolt_AGS2_ECM_STATUS_Lin2, handle-never-received=true, init-value=constant-reference=COMRXL_AGS2_ErrUnVolt_AGS2_ECM_STATUS_Lin2_Init
        data-element=COMRXL_AGS2_ErrOvrVolt_AGS2_ECM_STATUS_Lin2, handle-never-received=true, init-value=constant-reference=COMRXL_AGS2_ErrOvrVolt_AGS2_ECM_STATUS_Lin2_Init
        data-element=COMRXL_AGS2_ErrOvrTemp_AGS2_ECM_STATUS_Lin2, handle-never-received=true, init-value=constant-reference=COMRXL_AGS2_ErrOvrTemp_AGS2_ECM_STATUS_Lin2_Init
        data-element=COMRXL_AGS2_ErrMechStuck_AGS2_ECM_STATUS_Lin2, handle-never-received=true, init-value=constant-reference=COMRXL_AGS2_ErrMechStuck_AGS2_ECM_STATUS_Lin2_Init
        data-element=COMRXL_AGS2_ErrMechBreak_AGS2_ECM_STATUS_Lin2, handle-never-received=true, init-value=constant-reference=COMRXL_AGS2_ErrMechBreak_AGS2_ECM_STATUS_Lin2_Init
        data-element=COMRXL_AGS2_ErrLIN_AGS2_ECM_STATUS_Lin2, handle-never-received=true, init-value=constant-reference=COMRXL_AGS2_ErrLIN_AGS2_ECM_STATUS_Lin2_Init
        data-element=COMRXL_RsErr_AGS2_AGS2_ECM_STATUS_Lin2, handle-never-received=true, init-value=constant-reference=COMRXL_RsErr_AGS2_AGS2_ECM_STATUS_Lin2_Init
        data-element=COMRXL_AGS2_BoostStat_AGS2_ECM_STATUS_Lin2, handle-never-received=true, init-value=constant-reference=COMRXL_AGS2_BoostStat_AGS2_ECM_STATUS_Lin2_Init
        data-element=COMRXL_S2MResBit1_AGS2_AGS2_ECM_STATUS_Lin2, handle-never-received=true, init-value=constant-reference=COMRXL_S2MResBit1_AGS2_AGS2_ECM_STATUS_Lin2_Init
        data-element=COMRXL_AHP_RPM_TGT_PERCT_AHP_STAT_GLOBAL_Lin2, handle-never-received=true, init-value=constant-reference=COMRXL_AHP_RPM_TGT_PERCT_AHP_STAT_GLOBAL_Lin2_Init
        data-element=COMRXL_AHP_RPM_ACTL_PERCT_AHP_STAT_GLOBAL_Lin2, handle-never-received=true, init-value=constant-reference=COMRXL_AHP_RPM_ACTL_PERCT_AHP_STAT_GLOBAL_Lin2_Init
        data-element=COMRXL_AHP_VLTG_AHP_STAT_GLOBAL_Lin2, handle-never-received=true, init-value=constant-reference=COMRXL_AHP_VLTG_AHP_STAT_GLOBAL_Lin2_Init
        data-element=COMRXL_AHP_TEMP_AHP_STAT_GLOBAL_Lin2, handle-never-received=true, init-value=constant-reference=COMRXL_AHP_TEMP_AHP_STAT_GLOBAL_Lin2_Init
        data-element=COMRXL_AHP_CURR_AHP_STAT_GLOBAL_Lin2, handle-never-received=true, init-value=constant-reference=COMRXL_AHP_CURR_AHP_STAT_GLOBAL_Lin2_Init
        data-element=COMRXL_AHP_FL_SAFE_ACTVTD_AHP_STAT_GLOBAL_Lin2, handle-never-received=true, init-value=constant-reference=COMRXL_AHP_FL_SAFE_ACTVTD_AHP_STAT_GLOBAL_Lin2_Init
        data-element=COMRXL_AHP_LMP_HM_AN_ON_AHP_STAT_GLOBAL_Lin2, handle-never-received=true, init-value=constant-reference=COMRXL_AHP_LMP_HM_AN_ON_AHP_STAT_GLOBAL_Lin2_Init
        data-element=COMRXL_AHP_AIR_PRE_ERR_AHP_STAT_GLOBAL_Lin2, handle-never-received=true, init-value=constant-reference=COMRXL_AHP_AIR_PRE_ERR_AHP_STAT_GLOBAL_Lin2_Init
        data-element=COMRXL_AHP_OVR_TMP_ERR_AHP_STAT_GLOBAL_Lin2, handle-never-received=true, init-value=constant-reference=COMRXL_AHP_OVR_TMP_ERR_AHP_STAT_GLOBAL_Lin2_Init
        data-element=COMRXL_AHP_OVR_CUR_ERR_AHP_STAT_GLOBAL_Lin2, handle-never-received=true, init-value=constant-reference=COMRXL_AHP_OVR_CUR_ERR_AHP_STAT_GLOBAL_Lin2_Init
        data-element=COMRXL_AHP_DR_RN_ERR_AHP_STAT_GLOBAL_Lin2, handle-never-received=true, init-value=constant-reference=COMRXL_AHP_DR_RN_ERR_AHP_STAT_GLOBAL_Lin2_Init
        data-element=COMRXL_AHP_VLTG_ERR_AHP_STAT_GLOBAL_Lin2, handle-never-received=true, init-value=constant-reference=COMRXL_AHP_VLTG_ERR_AHP_STAT_GLOBAL_Lin2_Init
        data-element=COMRXL_AHP_DBLK_ACTV_AHP_STAT_GLOBAL_Lin2, handle-never-received=true, init-value=constant-reference=COMRXL_AHP_DBLK_ACTV_AHP_STAT_GLOBAL_Lin2_Init
        data-element=COMRXL_AHP_MONTRNG_RPM_AHP_STAT_GLOBAL_Lin2, handle-never-received=true, init-value=constant-reference=COMRXL_AHP_MONTRNG_RPM_AHP_STAT_GLOBAL_Lin2_Init
        data-element=COMRXL_AHP_NODE_ERR_AHP_STAT_GLOBAL_Lin2, handle-never-received=true, init-value=constant-reference=COMRXL_AHP_NODE_ERR_AHP_STAT_GLOBAL_Lin2_Init
        data-element=COMRXL_AHP_POST_RUN_STAT_AHP_STAT_GLOBAL_Lin2, handle-never-received=true, init-value=constant-reference=COMRXL_AHP_POST_RUN_STAT_AHP_STAT_GLOBAL_Lin2_Init
        data-element=COMRXL_RsErr_AHP_PUMP_AHP_STAT_GLOBAL_Lin2, handle-never-received=true, init-value=constant-reference=COMRXL_RsErr_AHP_PUMP_AHP_STAT_GLOBAL_Lin2_Init
        data-element=COMRXL_AHP_SUPPLIER_AHP_VER_Lin2, handle-never-received=true, init-value=constant-reference=COMRXL_AHP_SUPPLIER_AHP_VER_Lin2_Init
        data-element=COMRXL_BHV_PosAct_BHV_STAT_V2_Lin2, handle-never-received=true, init-value=constant-reference=COMRXL_BHV_PosAct_BHV_STAT_V2_Lin2_Init
        data-element=COMRXL_BHV_ERR_BHV_STAT_V2_Lin2, handle-never-received=true, init-value=constant-reference=COMRXL_BHV_ERR_BHV_STAT_V2_Lin2_Init
        data-element=COMRXL_BHV_Sts_BHV_STAT_V2_Lin2, handle-never-received=true, init-value=constant-reference=COMRXL_BHV_Sts_BHV_STAT_V2_Lin2_Init
        data-element=COMRXL_RsErr_BHV_BHV_STAT_V2_Lin2, handle-never-received=true, init-value=constant-reference=COMRXL_RsErr_BHV_BHV_STAT_V2_Lin2_Init
        data-element=COMRXL_CompFaultStat_EAC_STAT_Lin2, handle-never-received=true, init-value=constant-reference=COMRXL_CompFaultStat_EAC_STAT_Lin2_Init
        data-element=COMRXL_CompStat_EAC_STAT_Lin2, handle-never-received=true, init-value=constant-reference=COMRXL_CompStat_EAC_STAT_Lin2_Init
        data-element=COMRXL_CompressorSpd_EAC_STAT_Lin2, handle-never-received=true, init-value=constant-reference=COMRXL_CompressorSpd_EAC_STAT_Lin2_Init
        data-element=COMRXL_CompSpdIncrReq_EAC_STAT_Lin2, handle-never-received=true, init-value=constant-reference=COMRXL_CompSpdIncrReq_EAC_STAT_Lin2_Init
        data-element=COMRXL_CompElecPwr_EAC_STAT_Lin2, handle-never-received=true, init-value=constant-reference=COMRXL_CompElecPwr_EAC_STAT_Lin2_Init
        data-element=COMRXL_CompBoardTemp_EAC_STAT_Lin2, handle-never-received=true, init-value=constant-reference=COMRXL_CompBoardTemp_EAC_STAT_Lin2_Init
        data-element=COMRXL_CompIGBTTemp_EAC_STAT_Lin2, handle-never-received=true, init-value=constant-reference=COMRXL_CompIGBTTemp_EAC_STAT_Lin2_Init
        data-element=COMRXL_CompElecCurr_EAC_STAT_Lin2, handle-never-received=true, init-value=constant-reference=COMRXL_CompElecCurr_EAC_STAT_Lin2_Init
        data-element=COMRXL_CompHVInput_EAC_STAT_Lin2, handle-never-received=true, init-value=constant-reference=COMRXL_CompHVInput_EAC_STAT_Lin2_Init
        data-element=COMRXL_DriveMdReq_ESBM_1_Lin2, handle-never-received=true, init-value=constant-reference=COMRXL_DriveMdReq_ESBM_1_Lin2_Init
        data-element=COMRXL_HybridModeRq_LIN_ESBM_1_Lin2, handle-never-received=true, init-value=constant-reference=COMRXL_HybridModeRq_LIN_ESBM_1_Lin2_Init
        data-element=COMRXL_ESaveModeRq_LIN_ESBM_1_Lin2, handle-never-received=true, init-value=constant-reference=COMRXL_ESaveModeRq_LIN_ESBM_1_Lin2_Init
        data-element=COMRXL_ElectricModeRq_LIN_ESBM_1_Lin2, handle-never-received=true, init-value=constant-reference=COMRXL_ElectricModeRq_LIN_ESBM_1_Lin2_Init
        data-element=COMRXL_RsErr_ESBM_ESBM_1_Lin2, handle-never-received=true, init-value=constant-reference=COMRXL_RsErr_ESBM_ESBM_1_Lin2_Init
        data-element=COMRXL_PECP_RPM_TGT_PERCT_PECP_STAT_GLOBAL_Lin2, handle-never-received=true, init-value=constant-reference=COMRXL_PECP_RPM_TGT_PERCT_PECP_STAT_GLOBAL_Lin2_Init
        data-element=COMRXL_PECP_RPM_ACTL_PERCT_PECP_STAT_GLOBAL_Lin2, handle-never-received=true, init-value=constant-reference=COMRXL_PECP_RPM_ACTL_PERCT_PECP_STAT_GLOBAL_Lin2_Init
        data-element=COMRXL_PECP_VLTG_PECP_STAT_GLOBAL_Lin2, handle-never-received=true, init-value=constant-reference=COMRXL_PECP_VLTG_PECP_STAT_GLOBAL_Lin2_Init
        data-element=COMRXL_PECP_TEMP_PECP_STAT_GLOBAL_Lin2, handle-never-received=true, init-value=constant-reference=COMRXL_PECP_TEMP_PECP_STAT_GLOBAL_Lin2_Init
        data-element=COMRXL_PECP_CURR_PECP_STAT_GLOBAL_Lin2, handle-never-received=true, init-value=constant-reference=COMRXL_PECP_CURR_PECP_STAT_GLOBAL_Lin2_Init
        data-element=COMRXL_PECP_FL_SAFE_ACTVTD_PECP_STAT_GLOBAL_Lin2, handle-never-received=true, init-value=constant-reference=COMRXL_PECP_FL_SAFE_ACTVTD_PECP_STAT_GLOBAL_Lin2_Init
        data-element=COMRXL_PECP_LMP_HM_AN_ON_PECP_STAT_GLOBAL_Lin2, handle-never-received=true, init-value=constant-reference=COMRXL_PECP_LMP_HM_AN_ON_PECP_STAT_GLOBAL_Lin2_Init
        data-element=COMRXL_PECP_AIR_PRE_ERR_PECP_STAT_GLOBAL_Lin2, handle-never-received=true, init-value=constant-reference=COMRXL_PECP_AIR_PRE_ERR_PECP_STAT_GLOBAL_Lin2_Init
        data-element=COMRXL_PECP_OVR_TMP_ERR_PECP_STAT_GLOBAL_Lin2, handle-never-received=true, init-value=constant-reference=COMRXL_PECP_OVR_TMP_ERR_PECP_STAT_GLOBAL_Lin2_Init
        data-element=COMRXL_PECP_OVR_CUR_ERR_PECP_STAT_GLOBAL_Lin2, handle-never-received=true, init-value=constant-reference=COMRXL_PECP_OVR_CUR_ERR_PECP_STAT_GLOBAL_Lin2_Init
        data-element=COMRXL_PECP_DR_RN_ERR_PECP_STAT_GLOBAL_Lin2, handle-never-received=true, init-value=constant-reference=COMRXL_PECP_DR_RN_ERR_PECP_STAT_GLOBAL_Lin2_Init
        data-element=COMRXL_PECP_VLTG_ERR_PECP_STAT_GLOBAL_Lin2, handle-never-received=true, init-value=constant-reference=COMRXL_PECP_VLTG_ERR_PECP_STAT_GLOBAL_Lin2_Init
        data-element=COMRXL_PECP_DBLK_ACTV_PECP_STAT_GLOBAL_Lin2, handle-never-received=true, init-value=constant-reference=COMRXL_PECP_DBLK_ACTV_PECP_STAT_GLOBAL_Lin2_Init
        data-element=COMRXL_PECP_MONTRNG_RPM_PECP_STAT_GLOBAL_Lin2, handle-never-received=true, init-value=constant-reference=COMRXL_PECP_MONTRNG_RPM_PECP_STAT_GLOBAL_Lin2_Init
        data-element=COMRXL_PECP_NODE_ERR_PECP_STAT_GLOBAL_Lin2, handle-never-received=true, init-value=constant-reference=COMRXL_PECP_NODE_ERR_PECP_STAT_GLOBAL_Lin2_Init
        data-element=COMRXL_PECP_POST_RUN_STAT_PECP_STAT_GLOBAL_Lin2, handle-never-received=true, init-value=constant-reference=COMRXL_PECP_POST_RUN_STAT_PECP_STAT_GLOBAL_Lin2_Init
        data-element=COMRXL_RsErr_PECP_PUMP_PECP_STAT_GLOBAL_Lin2, handle-never-received=true, init-value=constant-reference=COMRXL_RsErr_PECP_PUMP_PECP_STAT_GLOBAL_Lin2_Init
        data-element=COMRXL_PECP_SUPPLIER_PECP_VER_Lin2, handle-never-received=true, init-value=constant-reference=COMRXL_PECP_SUPPLIER_PECP_VER_Lin2_Init
        data-element=COMRXL_PowerPanel_Button_State_PowerPanel_STAT_Lin2, handle-never-received=true, init-value=constant-reference=COMRXL_PowerPanel_Button_State_PowerPanel_STAT_Lin2_Init
        data-element=COMRXL_PowerPanel_Lid_Switch_Sts_120A_PowerPanel_STAT_Lin2, handle-never-received=true, init-value=constant-reference=COMRXL_PowerPanel_Lid_Switch_Sts_120A_PowerPanel_STAT_Lin2_Init
        data-element=COMRXL_PowerPanel_Lid_Switch_Sts_120B_PowerPanel_STAT_Lin2, handle-never-received=true, init-value=constant-reference=COMRXL_PowerPanel_Lid_Switch_Sts_120B_PowerPanel_STAT_Lin2_Init
        data-element=COMRXL_PowerPanel_Lid_Switch_Sts_240_PowerPanel_STAT_Lin2, handle-never-received=true, init-value=constant-reference=COMRXL_PowerPanel_Lid_Switch_Sts_240_PowerPanel_STAT_Lin2_Init
        data-element=COMRXL_PowerPanel_Fault_Reason_PowerPanel_STAT_Lin2, handle-never-received=true, init-value=constant-reference=COMRXL_PowerPanel_Fault_Reason_PowerPanel_STAT_Lin2_Init
        data-element=COMRXL_RsErr_SPP_PowerPanel_STAT_Lin2, handle-never-received=true, init-value=constant-reference=COMRXL_RsErr_SPP_PowerPanel_STAT_Lin2_Init
        data-element=COMRXL_AHP_VERSION_AHP_VER_Lin2, handle-never-received=true, init-value=constant-reference=COMRXL_AHP_VERSION_AHP_VER_Lin2_Init
        data-element=COMRXL_PECP_VERSION_PECP_VER_Lin2, handle-never-received=true, init-value=constant-reference=COMRXL_PECP_VERSION_PECP_VER_Lin2_Init
        data-element=COMRXL_S2MResByte1_AGS2_AGS2_ECM_STATUS_Lin2, handle-never-received=true, init-value=constant-reference=COMRXL_S2MResByte1_AGS2_AGS2_ECM_STATUS_Lin2_Init
        data-element=COMRXL_S2MResByte2_AGS2_AGS2_ECM_STATUS_Lin2, handle-never-received=true, init-value=constant-reference=COMRXL_S2MResByte2_AGS2_AGS2_ECM_STATUS_Lin2_Init
        data-element=COMRXL_BHV_MotorVolt_BHV_STAT_V2_Lin2, handle-never-received=true, init-value=constant-reference=COMRXL_BHV_MotorVolt_BHV_STAT_V2_Lin2_Init
        data-element=COMRXL_BHV_CalStat_BHV_STAT_V2_Lin2, handle-never-received=true, init-value=constant-reference=COMRXL_BHV_CalStat_BHV_STAT_V2_Lin2_Init
        data-element=COMRXL_OEXV_PosAct_OEXV_STAT_Lin2, handle-never-received=true, init-value=constant-reference=COMRXL_OEXV_PosAct_OEXV_STAT_Lin2_Init
        data-element=COMRXL_OEXV_CalStat_OEXV_STAT_Lin2, handle-never-received=true, init-value=constant-reference=COMRXL_OEXV_CalStat_OEXV_STAT_Lin2_Init
        data-element=COMRXL_OEXV_CalRq_OEXV_STAT_Lin2, handle-never-received=true, init-value=constant-reference=COMRXL_OEXV_CalRq_OEXV_STAT_Lin2_Init
        data-element=COMRXL_RsErr_OEXV_OEXV_STAT_Lin2, handle-never-received=true, init-value=constant-reference=COMRXL_RsErr_OEXV_OEXV_STAT_Lin2_Init
        data-element=COMRXL_OEXV_Sts_OEXV_STAT_Lin2, handle-never-received=true, init-value=constant-reference=COMRXL_OEXV_Sts_OEXV_STAT_Lin2_Init
        data-element=COMRXL_OEXV_ERR_OEXV_STAT_Lin2, handle-never-received=true, init-value=constant-reference=COMRXL_OEXV_ERR_OEXV_STAT_Lin2_Init
        data-element=COMRXL_OEXV_SupplyVolt_OEXV_STAT_Lin2, handle-never-received=true, init-value=constant-reference=COMRXL_OEXV_SupplyVolt_OEXV_STAT_Lin2_Init
        data-element=COMRXL_OEXV_Refrigerant_Pressure_OEXV_STAT_Lin2, handle-never-received=true, init-value=constant-reference=COMRXL_OEXV_Refrigerant_Pressure_OEXV_STAT_Lin2_Init
        data-element=COMRXL_OEXV_Board_Temp_OEXV_STAT_Lin2, handle-never-received=true, init-value=constant-reference=COMRXL_OEXV_Board_Temp_OEXV_STAT_Lin2_Init
        data-element=COMRXL_OEXV_Refrigerant_Temp_OEXV_STAT_Lin2, handle-never-received=true, init-value=constant-reference=COMRXL_OEXV_Refrigerant_Temp_OEXV_STAT_Lin2_Init
        data-element=COMRXL_CompFaultStat_800_EAC_STAT_800_Lin2, handle-never-received=true, init-value=constant-reference=COMRXL_CompFaultStat_800_EAC_STAT_800_Lin2_Init
        data-element=COMRXL_CompStat_800_EAC_STAT_800_Lin2, handle-never-received=true, init-value=constant-reference=COMRXL_CompStat_800_EAC_STAT_800_Lin2_Init
        data-element=COMRXL_CompressorSpd_800_EAC_STAT_800_Lin2, handle-never-received=true, init-value=constant-reference=COMRXL_CompressorSpd_800_EAC_STAT_800_Lin2_Init
        data-element=COMRXL_CompSpdIncrReq_800_EAC_STAT_800_Lin2, handle-never-received=true, init-value=constant-reference=COMRXL_CompSpdIncrReq_800_EAC_STAT_800_Lin2_Init
        data-element=COMRXL_RsErr_EAC2_800_EAC_STAT_800_Lin2, handle-never-received=true, init-value=constant-reference=COMRXL_RsErr_EAC2_800_EAC_STAT_800_Lin2_Init
        data-element=COMRXL_CompElecPwr_800_EAC_STAT_800_Lin2, handle-never-received=true, init-value=constant-reference=COMRXL_CompElecPwr_800_EAC_STAT_800_Lin2_Init
        data-element=COMRXL_CompBoardTemp_800_EAC_STAT_800_Lin2, handle-never-received=true, init-value=constant-reference=COMRXL_CompBoardTemp_800_EAC_STAT_800_Lin2_Init
        data-element=COMRXL_CompIGBTTemp_800_EAC_STAT_800_Lin2, handle-never-received=true, init-value=constant-reference=COMRXL_CompIGBTTemp_800_EAC_STAT_800_Lin2_Init
        data-element=COMRXL_CompElecCurr_800_EAC_STAT_800_Lin2, handle-never-received=true, init-value=constant-reference=COMRXL_CompElecCurr_800_EAC_STAT_800_Lin2_Init
        data-element=COMRXL_CompHVInput_800_EAC_STAT_800_Lin2, handle-never-received=true, init-value=constant-reference=COMRXL_CompHVInput_800_EAC_STAT_800_Lin2_Init
        data-element=COMRXL_PowerPanel_LED_A_Feedback_PowerPanel_STAT_Lin2, handle-never-received=true, init-value=constant-reference=COMRXL_PowerPanel_LED_A_Feedback_PowerPanel_STAT_Lin2_Init
        data-element=COMRXL_PowerPanel_LED_B_Feedback_PowerPanel_STAT_Lin2, handle-never-received=true, init-value=constant-reference=COMRXL_PowerPanel_LED_B_Feedback_PowerPanel_STAT_Lin2_Init
        data-element=COMRXL_PowerPanel_LED_C_Feedback_PowerPanel_STAT_Lin2, handle-never-received=true, init-value=constant-reference=COMRXL_PowerPanel_LED_C_Feedback_PowerPanel_STAT_Lin2_Init
        data-element=COMRXL_PowerPanel_LED_A_FailStatus_PowerPanel_STAT_Lin2, handle-never-received=true, init-value=constant-reference=COMRXL_PowerPanel_LED_A_FailStatus_PowerPanel_STAT_Lin2_Init
        data-element=COMRXL_PowerPanel_LED_B_FailStatus_PowerPanel_STAT_Lin2, handle-never-received=true, init-value=constant-reference=COMRXL_PowerPanel_LED_B_FailStatus_PowerPanel_STAT_Lin2_Init
        data-element=COMRXL_PowerPanel_LED_C_FailStatus_PowerPanel_STAT_Lin2, handle-never-received=true, init-value=constant-reference=COMRXL_PowerPanel_LED_C_FailStatus_PowerPanel_STAT_Lin2_Init
        data-element=COMRXL_PowerPanel_LED_A_Color_Feedback_PowerPanel_STAT_Lin2, handle-never-received=true, init-value=constant-reference=COMRXL_PowerPanel_LED_A_Color_Feedback_PowerPanel_STAT_Lin2_Init
        data-element=COMRXL_PowerPanel_LED_B_Color_Feedback_PowerPanel_STAT_Lin2, handle-never-received=true, init-value=constant-reference=COMRXL_PowerPanel_LED_B_Color_Feedback_PowerPanel_STAT_Lin2_Init
        data-element=COMRXL_PowerPanel_LED_C_Color_Feedback_PowerPanel_STAT_Lin2, handle-never-received=true, init-value=constant-reference=COMRXL_PowerPanel_LED_C_Color_Feedback_PowerPanel_STAT_Lin2_Init
        data-element=COMRXL_PowerPanel_LIN_Checksum_Error_PowerPanel_STAT_Lin2, handle-never-received=true, init-value=constant-reference=COMRXL_PowerPanel_LIN_Checksum_Error_PowerPanel_STAT_Lin2_Init
        data-element=COMRXL_PowerPanel_LIN_Data_Error_PowerPanel_STAT_Lin2, handle-never-received=true, init-value=constant-reference=COMRXL_PowerPanel_LIN_Data_Error_PowerPanel_STAT_Lin2_Init
        data-element=COMRXL_PowerPanel_LIN_Parity_Error_PowerPanel_STAT_Lin2, handle-never-received=true, init-value=constant-reference=COMRXL_PowerPanel_LIN_Parity_Error_PowerPanel_STAT_Lin2_Init
        data-element=COMRXL_PowerPanel_Gnd_Fault_Detected_PowerPanel_STAT_Lin2, handle-never-received=true, init-value=constant-reference=COMRXL_PowerPanel_Gnd_Fault_Detected_PowerPanel_STAT_Lin2_Init
        data-element=COMRXL_RsErr_EAC2_EAC_STAT_Lin2, handle-never-received=true, init-value=constant-reference=COMRXL_RsErr_EAC2_EAC_STAT_Lin2_Init
        data-element=COMRXL_PowerPanel_Fault_PowerPanel_STAT_Lin2, handle-never-received=true, init-value=constant-reference=COMRXL_PowerPanel_Fault_PowerPanel_STAT_Lin2_Init
        data-element=COMRXL_PowerPanel_RatedPower_PowerPanel_STAT_Lin2, handle-never-received=true, init-value=constant-reference=COMRXL_PowerPanel_RatedPower_PowerPanel_STAT_Lin2_Init
        data-element=COMRXL_PowerPanel_Current_Draw_Sens2_PowerPanel_STAT_Lin2, handle-never-received=true, init-value=constant-reference=COMRXL_PowerPanel_Current_Draw_Sens2_PowerPanel_STAT_Lin2_Init
        data-element=COMRXL_PowerPanel_AC_Present_Sens1_PowerPanel_STAT_Lin2, handle-never-received=true, init-value=constant-reference=COMRXL_PowerPanel_AC_Present_Sens1_PowerPanel_STAT_Lin2_Init
        data-element=COMRXL_PowerPanel_AC_Present_Sens2_PowerPanel_STAT_Lin2, handle-never-received=true, init-value=constant-reference=COMRXL_PowerPanel_AC_Present_Sens2_PowerPanel_STAT_Lin2_Init
        data-element=COMRXL_PowerPanel_Current_Draw_Sens1_PowerPanel_STAT_Lin2, handle-never-received=true, init-value=constant-reference=COMRXL_PowerPanel_Current_Draw_Sens1_PowerPanel_STAT_Lin2_Init
    provide port Lin3ComTxSignalsSR: provided-interface=Lin3ComTxSignalsSR
      provided-com-specs:
        data-element=COMTXL_AGS_PosRq_ECM_AGS_DEMAND_Lin3, init-value=constant-reference=COMTXL_AGS_PosRq_ECM_AGS_DEMAND_Lin3_Init
        data-element=COMTXL_AGS_CalRq_ECM_AGS_DEMAND_Lin3, init-value=constant-reference=COMTXL_AGS_CalRq_ECM_AGS_DEMAND_Lin3_Init
        data-element=COMTXL_AGS_BoostRq_ECM_AGS_DEMAND_Lin3, init-value=constant-reference=COMTXL_AGS_BoostRq_ECM_AGS_DEMAND_Lin3_Init
        data-element=COMTXL_M2SRes2Bit_ECM_AGS_DEMAND_Lin3, init-value=constant-reference=COMTXL_M2SRes2Bit_ECM_AGS_DEMAND_Lin3_Init
        data-element=COMTXL_M2SResByte{1..3}_ECM_AGS_DEMAND_Lin3, init-value=constant-reference=COMTXL_M2SResByte{1..3}_ECM_AGS_DEMAND_Lin3_Init
        data-element=COMTXL_CEXV_PosRq_CEXV_REQ_Lin3, init-value=constant-reference=COMTXL_CEXV_PosRq_CEXV_REQ_Lin3_Init
        data-element=COMTXL_CEXV_CalCmd_CEXV_REQ_Lin3, init-value=constant-reference=COMTXL_CEXV_CalCmd_CEXV_REQ_Lin3_Init
        data-element=COMTXL_CPIM_SET_IND{1..5}_HCP_CPIM_COMMAND_Lin3, init-value=constant-reference=COMTXL_CPIM_SET_IND{1..5}_HCP_CPIM_COMMAND_Lin3_Init
        data-element=COMTXL_CPIM_Blink_Rate_HCP_CPIM_COMMAND_Lin3, init-value=constant-reference=COMTXL_CPIM_Blink_Rate_HCP_CPIM_COMMAND_Lin3_Init
        data-element=COMTXL_CPIM_IND_Color_HCP_CPIM_COMMAND_Lin3, init-value=constant-reference=COMTXL_CPIM_IND_Color_HCP_CPIM_COMMAND_Lin3_Init
        data-element=COMTXL_ChrgPortLock_Cmd_HCP_CPIM_COMMAND_Lin3, init-value=constant-reference=COMTXL_ChrgPortLock_Cmd_HCP_CPIM_COMMAND_Lin3_Init
        data-element=COMTXL_Set_Icon1_cmd_HCP_CPIM_COMMAND_Lin3, init-value=constant-reference=COMTXL_Set_Icon1_cmd_HCP_CPIM_COMMAND_Lin3_Init
        data-element=COMTXL_Set_Icon2_cmd_HCP_CPIM_COMMAND_Lin3, init-value=constant-reference=COMTXL_Set_Icon2_cmd_HCP_CPIM_COMMAND_Lin3_Init
        data-element=COMTXL_DAY_LGT_MD_CPIM_HCP_CPIM_COMMAND_Lin3, init-value=constant-reference=COMTXL_DAY_LGT_MD_CPIM_HCP_CPIM_COMMAND_Lin3_Init
        data-element=COMTXL_Backlight_Cmd_HCP_CPIM_COMMAND_Lin3, init-value=constant-reference=COMTXL_Backlight_Cmd_HCP_CPIM_COMMAND_Lin3_Init
        data-element=COMTXL_HvWtrHeatrPwrCnsAllwd_CCMLIN18Fr02_Lin3, init-value=constant-reference=COMTXL_HvWtrHeatrPwrCnsAllwd_CCMLIN18Fr02_Lin3_Init
        data-element=COMTXL_HvWtrHeatrWtrTDes_CCMLIN18Fr02_Lin3, init-value=constant-reference=COMTXL_HvWtrHeatrWtrTDes_CCMLIN18Fr02_Lin3_Init
        data-element=COMTXL_HvCooltHeatrEnad_CCMLIN18Fr02_Lin3, init-value=constant-reference=COMTXL_HvCooltHeatrEnad_CCMLIN18Fr02_Lin3_Init
        data-element=COMTXL_HVH_OverheatUnlock_CCMLIN18Fr02_Lin3, init-value=constant-reference=COMTXL_HVH_OverheatUnlock_CCMLIN18Fr02_Lin3_Init
        data-element=COMTXL_EOPB_RPM_COM_EOPB_REQ_Lin3, init-value=constant-reference=COMTXL_EOPB_RPM_COM_EOPB_REQ_Lin3_Init
        data-element=COMTXL_EOPB_POST_RUN_COM_EOPB_REQ_Lin3, init-value=constant-reference=COMTXL_EOPB_POST_RUN_COM_EOPB_REQ_Lin3_Init
        data-element=COMTXL_HTLBV_PosRq_HTLBV_REQ_Lin3, init-value=constant-reference=COMTXL_HTLBV_PosRq_HTLBV_REQ_Lin3_Init
        data-element=COMTXL_HTLBV_PosSv_HTLBV_REQ_Lin3, init-value=constant-reference=COMTXL_HTLBV_PosSv_HTLBV_REQ_Lin3_Init
        data-element=COMTXL_HTLBV_CalRq_HTLBV_REQ_Lin3, init-value=constant-reference=COMTXL_HTLBV_CalRq_HTLBV_REQ_Lin3_Init
        data-element=COMTXL_PECP2_RPM_REQ_PERCT_PECP2_REQ_GLOBAL_Lin3, init-value=constant-reference=COMTXL_PECP2_RPM_REQ_PERCT_PECP2_REQ_GLOBAL_Lin3_Init
        data-element=COMTXL_PECP2_POST_RUN_REQ_PECP2_REQ_GLOBAL_Lin3, init-value=constant-reference=COMTXL_PECP2_POST_RUN_REQ_PECP2_REQ_GLOBAL_Lin3_Init
        data-element=COMTXL_PECP2_FL_SAFE_ACTVT_PECP2_REQ_GLOBAL_Lin3, init-value=constant-reference=COMTXL_PECP2_FL_SAFE_ACTVT_PECP2_REQ_GLOBAL_Lin3_Init
        data-element=COMTXL_PowerPanel2_LED_A_Command_PowerPanel2_REQ_Lin3, init-value=constant-reference=COMTXL_PowerPanel2_LED_A_Command_PowerPanel2_REQ_Lin3_Init
        data-element=COMTXL_PowerPanel2_LED_B_Command_PowerPanel2_REQ_Lin3, init-value=constant-reference=COMTXL_PowerPanel2_LED_B_Command_PowerPanel2_REQ_Lin3_Init
        data-element=COMTXL_DAY_LGT_MD_PowerPanel2_PowerPanel2_REQ_Lin3, init-value=constant-reference=COMTXL_DAY_LGT_MD_PowerPanel2_PowerPanel2_REQ_Lin3_Init
        data-element=COMTXL_PowerPanel2_LED_A_Color_Command_PowerPanel2_REQ_Lin3, init-value=constant-reference=COMTXL_PowerPanel2_LED_A_Color_Command_PowerPanel2_REQ_Lin3_Init
        data-element=COMTXL_PowerPanel2_LED_B_Color_Command_PowerPanel2_REQ_Lin3, init-value=constant-reference=COMTXL_PowerPanel2_LED_B_Color_Command_PowerPanel2_REQ_Lin3_Init
    require port Lin3ComRxSignalsSR: required-interface=Lin3ComRxSignalsSR
      required-com-specs:
        data-element=COMRXL_AGS_CurrPos_AGS_ECM_STATUS_Lin3, handle-never-received=true, init-value=constant-reference=COMRXL_AGS_CurrPos_AGS_ECM_STATUS_Lin3_Init
        data-element=COMRXL_AGS_CalStat_AGS_ECM_STATUS_Lin3, handle-never-received=true, init-value=constant-reference=COMRXL_AGS_CalStat_AGS_ECM_STATUS_Lin3_Init
        data-element=COMRXL_AGS_CalActv_AGS_ECM_STATUS_Lin3, handle-never-received=true, init-value=constant-reference=COMRXL_AGS_CalActv_AGS_ECM_STATUS_Lin3_Init
        data-element=COMRXL_AGS_ErrUnVolt_AGS_ECM_STATUS_Lin3, handle-never-received=true, init-value=constant-reference=COMRXL_AGS_ErrUnVolt_AGS_ECM_STATUS_Lin3_Init
        data-element=COMRXL_AGS_ErrOvrVolt_AGS_ECM_STATUS_Lin3, handle-never-received=true, init-value=constant-reference=COMRXL_AGS_ErrOvrVolt_AGS_ECM_STATUS_Lin3_Init
        data-element=COMRXL_AGS_ErrOvrTemp_AGS_ECM_STATUS_Lin3, handle-never-received=true, init-value=constant-reference=COMRXL_AGS_ErrOvrTemp_AGS_ECM_STATUS_Lin3_Init
        data-element=COMRXL_AGS_ErrMechStuck_AGS_ECM_STATUS_Lin3, handle-never-received=true, init-value=constant-reference=COMRXL_AGS_ErrMechStuck_AGS_ECM_STATUS_Lin3_Init
        data-element=COMRXL_AGS_ErrMechBreak_AGS_ECM_STATUS_Lin3, handle-never-received=true, init-value=constant-reference=COMRXL_AGS_ErrMechBreak_AGS_ECM_STATUS_Lin3_Init
        data-element=COMRXL_AGS_ErrLIN_AGS_ECM_STATUS_Lin3, handle-never-received=true, init-value=constant-reference=COMRXL_AGS_ErrLIN_AGS_ECM_STATUS_Lin3_Init
        data-element=COMRXL_RsErr_AGS_AGS_ECM_STATUS_Lin3, handle-never-received=true, init-value=constant-reference=COMRXL_RsErr_AGS_AGS_ECM_STATUS_Lin3_Init
        data-element=COMRXL_AGS_BoostStat_AGS_ECM_STATUS_Lin3, handle-never-received=true, init-value=constant-reference=COMRXL_AGS_BoostStat_AGS_ECM_STATUS_Lin3_Init
        data-element=COMRXL_S2MRes1Bit_AGS_ECM_STATUS_Lin3, handle-never-received=true, init-value=constant-reference=COMRXL_S2MRes1Bit_AGS_ECM_STATUS_Lin3_Init
        data-element=COMRXL_S2MResByte1_AGS_ECM_STATUS_Lin3, handle-never-received=true, init-value=constant-reference=COMRXL_S2MResByte1_AGS_ECM_STATUS_Lin3_Init
        data-element=COMRXL_S2MResByte2_AGS_ECM_STATUS_Lin3, handle-never-received=true, init-value=constant-reference=COMRXL_S2MResByte2_AGS_ECM_STATUS_Lin3_Init
        data-element=COMRXL_CEXV_PosAct_CEXV_STAT_Lin3, handle-never-received=true, init-value=constant-reference=COMRXL_CEXV_PosAct_CEXV_STAT_Lin3_Init
        data-element=COMRXL_CEXV_CalStat_CEXV_STAT_Lin3, handle-never-received=true, init-value=constant-reference=COMRXL_CEXV_CalStat_CEXV_STAT_Lin3_Init
        data-element=COMRXL_CEXV_CalRq_CEXV_STAT_Lin3, handle-never-received=true, init-value=constant-reference=COMRXL_CEXV_CalRq_CEXV_STAT_Lin3_Init
        data-element=COMRXL_RsErr_CEXV_CEXV_STAT_Lin3, handle-never-received=true, init-value=constant-reference=COMRXL_RsErr_CEXV_CEXV_STAT_Lin3_Init
        data-element=COMRXL_CEXV_Sts_CEXV_STAT_Lin3, handle-never-received=true, init-value=constant-reference=COMRXL_CEXV_Sts_CEXV_STAT_Lin3_Init
        data-element=COMRXL_CEXV_ERR_CEXV_STAT_Lin3, handle-never-received=true, init-value=constant-reference=COMRXL_CEXV_ERR_CEXV_STAT_Lin3_Init
        data-element=COMRXL_CEXV_SupplyVolt_CEXV_STAT_Lin3, handle-never-received=true, init-value=constant-reference=COMRXL_CEXV_SupplyVolt_CEXV_STAT_Lin3_Init
        data-element=COMRXL_CEXV_Refrigerant_Pressure_CEXV_STAT_Lin3, handle-never-received=true, init-value=constant-reference=COMRXL_CEXV_Refrigerant_Pressure_CEXV_STAT_Lin3_Init
        data-element=COMRXL_CEXV_Board_Temp_CEXV_STAT_Lin3, handle-never-received=true, init-value=constant-reference=COMRXL_CEXV_Board_Temp_CEXV_STAT_Lin3_Init
        data-element=COMRXL_CEXV_Refrigerant_Temp_CEXV_STAT_Lin3, handle-never-received=true, init-value=constant-reference=COMRXL_CEXV_Refrigerant_Temp_CEXV_STAT_Lin3_Init
        data-element=COMRXL_Inlet_Temp1_DC_CPIM_HCP_FEEDBACK2_Lin3, handle-never-received=true, init-value=constant-reference=COMRXL_Inlet_Temp1_DC_CPIM_HCP_FEEDBACK2_Lin3_Init
        data-element=COMRXL_Inlet_Temp2_DC_CPIM_HCP_FEEDBACK2_Lin3, handle-never-received=true, init-value=constant-reference=COMRXL_Inlet_Temp2_DC_CPIM_HCP_FEEDBACK2_Lin3_Init
        data-element=COMRXL_CPIM_IND{1..5}_Fdbk_CPIM_HCP_FEEDBACK_Lin3, handle-never-received=true, init-value=constant-reference=COMRXL_CPIM_IND{1..5}_Fdbk_CPIM_HCP_FEEDBACK_Lin3_Init
        data-element=COMRXL_CPIM_IND_Color_Fdbk_CPIM_HCP_FEEDBACK_Lin3, handle-never-received=true, init-value=constant-reference=COMRXL_CPIM_IND_Color_Fdbk_CPIM_HCP_FEEDBACK_Lin3_Init
        data-element=COMRXL_CPIM_IND{1..5}_FailSts_CPIM_HCP_FEEDBACK_Lin3, handle-never-received=true, init-value=constant-reference=COMRXL_CPIM_IND{1..5}_FailSts_CPIM_HCP_FEEDBACK_Lin3_Init
        data-element=COMRXL_CPIM_Undervoltage_CPIM_HCP_FEEDBACK_Lin3, handle-never-received=true, init-value=constant-reference=COMRXL_CPIM_Undervoltage_CPIM_HCP_FEEDBACK_Lin3_Init
        data-element=COMRXL_CPIM_Over_Temperature_CPIM_HCP_FEEDBACK_Lin3, handle-never-received=true, init-value=constant-reference=COMRXL_CPIM_Over_Temperature_CPIM_HCP_FEEDBACK_Lin3_Init
        data-element=COMRXL_CPIM_LIN_Parity_Error_CPIM_HCP_FEEDBACK_Lin3, handle-never-received=true, init-value=constant-reference=COMRXL_CPIM_LIN_Parity_Error_CPIM_HCP_FEEDBACK_Lin3_Init
        data-element=COMRXL_CPIM_LIN_Checksum_Error_CPIM_HCP_FEEDBACK_Lin3, handle-never-received=true, init-value=constant-reference=COMRXL_CPIM_LIN_Checksum_Error_CPIM_HCP_FEEDBACK_Lin3_Init
        data-element=COMRXL_CPIM_LIN_Data_Error_CPIM_HCP_FEEDBACK_Lin3, handle-never-received=true, init-value=constant-reference=COMRXL_CPIM_LIN_Data_Error_CPIM_HCP_FEEDBACK_Lin3_Init
        data-element=COMRXL_ChrgPortLock_Sts_CPIM_HCP_FEEDBACK_Lin3, handle-never-received=true, init-value=constant-reference=COMRXL_ChrgPortLock_Sts_CPIM_HCP_FEEDBACK_Lin3_Init
        data-element=COMRXL_ChrgPortButton_Sts_CPIM_HCP_FEEDBACK_Lin3, handle-never-received=true, init-value=constant-reference=COMRXL_ChrgPortButton_Sts_CPIM_HCP_FEEDBACK_Lin3_Init
        data-element=COMRXL_Ambient_Temp_CPIM_HCP_FEEDBACK_Lin3, handle-never-received=true, init-value=constant-reference=COMRXL_Ambient_Temp_CPIM_HCP_FEEDBACK_Lin3_Init
        data-element=COMRXL_Chrg_Inlet_Temp_CPIM_HCP_FEEDBACK_Lin3, handle-never-received=true, init-value=constant-reference=COMRXL_Chrg_Inlet_Temp_CPIM_HCP_FEEDBACK_Lin3_Init
        data-element=COMRXL_ResponseErrorStsCPIM_CPIM_HCP_FEEDBACK_Lin3, handle-never-received=true, init-value=constant-reference=COMRXL_ResponseErrorStsCPIM_CPIM_HCP_FEEDBACK_Lin3_Init
        data-element=COMRXL_ChrgPortLock_FailSts_CPIM_HCP_FEEDBACK_Lin3, handle-never-received=true, init-value=constant-reference=COMRXL_ChrgPortLock_FailSts_CPIM_HCP_FEEDBACK_Lin3_Init
        data-element=COMRXL_Icon1_Sts_CPIM_HCP_FEEDBACK_Lin3, handle-never-received=true, init-value=constant-reference=COMRXL_Icon1_Sts_CPIM_HCP_FEEDBACK_Lin3_Init
        data-element=COMRXL_Icon1_FailSts_CPIM_HCP_FEEDBACK_Lin3, handle-never-received=true, init-value=constant-reference=COMRXL_Icon1_FailSts_CPIM_HCP_FEEDBACK_Lin3_Init
        data-element=COMRXL_Icon2_Sts_CPIM_HCP_FEEDBACK_Lin3, handle-never-received=true, init-value=constant-reference=COMRXL_Icon2_Sts_CPIM_HCP_FEEDBACK_Lin3_Init
        data-element=COMRXL_Icon2_FailSts_CPIM_HCP_FEEDBACK_Lin3, handle-never-received=true, init-value=constant-reference=COMRXL_Icon2_FailSts_CPIM_HCP_FEEDBACK_Lin3_Init
        data-element=COMRXL_ChrgPortDoor_Sts_CPIM_HCP_FEEDBACK_Lin3, handle-never-received=true, init-value=constant-reference=COMRXL_ChrgPortDoor_Sts_CPIM_HCP_FEEDBACK_Lin3_Init
        data-element=COMRXL_HvCooltHeatrSts_HVCHLIN18Fr01_Lin3, handle-never-received=true, init-value=constant-reference=COMRXL_HvCooltHeatrSts_HVCHLIN18Fr01_Lin3_Init
        data-element=COMRXL_ECH_InterlockStat_HVCHLIN18Fr01_Lin3, handle-never-received=true, init-value=constant-reference=COMRXL_ECH_InterlockStat_HVCHLIN18Fr01_Lin3_Init
        data-element=COMRXL_Below_60V_HVCHLIN18Fr01_Lin3, handle-never-received=true, init-value=constant-reference=COMRXL_Below_60V_HVCHLIN18Fr01_Lin3_Init
        data-element=COMRXL_HvCooltWtrHeatrWtrTInIntk_HVCHLIN18Fr01_Lin3, handle-never-received=true, init-value=constant-reference=COMRXL_HvCooltWtrHeatrWtrTInIntk_HVCHLIN18Fr01_Lin3_Init
        data-element=COMRXL_HvWtrHeatrWtrT_HVCHLIN18Fr01_Lin3, handle-never-received=true, init-value=constant-reference=COMRXL_HvWtrHeatrWtrT_HVCHLIN18Fr01_Lin3_Init
        data-element=COMRXL_HvCooltHeatrICns_HVCHLIN18Fr01_Lin3, handle-never-received=true, init-value=constant-reference=COMRXL_HvCooltHeatrICns_HVCHLIN18Fr01_Lin3_Init
        data-element=COMRXL_HvCooltHVmeas_HVCHLIN18Fr01_Lin3, handle-never-received=true, init-value=constant-reference=COMRXL_HvCooltHVmeas_HVCHLIN18Fr01_Lin3_Init
        data-element=COMRXL_HvHeatrPwrCns_HVCHLIN18Fr01_Lin3, handle-never-received=true, init-value=constant-reference=COMRXL_HvHeatrPwrCns_HVCHLIN18Fr01_Lin3_Init
        data-element=COMRXL_HvHeatrPwrCnsDes_HVCHLIN18Fr01_Lin3, handle-never-received=true, init-value=constant-reference=COMRXL_HvHeatrPwrCnsDes_HVCHLIN18Fr01_Lin3_Init
        data-element=COMRXL_HVH_UnlockCounter_HVCHLIN18Fr01_Lin3, handle-never-received=true, init-value=constant-reference=COMRXL_HVH_UnlockCounter_HVCHLIN18Fr01_Lin3_Init
        data-element=COMRXL_RsErr_ECH_HVCHLIN18Fr02_Lin3, handle-never-received=true, init-value=constant-reference=COMRXL_RsErr_ECH_HVCHLIN18Fr02_Lin3_Init
        data-element=COMRXL_HvCooltHeatrWarnFltInCom_HVCHLIN18Fr02_Lin3, handle-never-received=true, init-value=constant-reference=COMRXL_HvCooltHeatrWarnFltInCom_HVCHLIN18Fr02_Lin3_Init
        data-element=COMRXL_HvCooltHeatrWarnHvOutOfRng_HVCHLIN18Fr02_Lin3, handle-never-received=true, init-value=constant-reference=COMRXL_HvCooltHeatrWarnHvOutOfRng_HVCHLIN18Fr02_Lin3_Init
        data-element=COMRXL_HvCooltHeatrWarnULoOutOfRng_HVCHLIN18Fr02_Lin3, handle-never-received=true, init-value=constant-reference=COMRXL_HvCooltHeatrWarnULoOutOfRng_HVCHLIN18Fr02_Lin3_Init
        data-element=COMRXL_HvCooltHeatrWarnCooltTOutOfRng_HVCHLIN18Fr02_Lin3, handle-never-received=true, init-value=constant-reference=COMRXL_HvCooltHeatrWarnCooltTOutOfRng_HVCHLIN18Fr02_Lin3_Init
        data-element=COMRXL_HvCooltHeatrProtnOfSelfTmpHwProtn_HVCHLIN18Fr02_Lin3, handle-never-received=true, init-value=constant-reference=COMRXL_HvCooltHeatrProtnOfSelfTmpHwProtn_HVCHLIN18Fr02_Lin3_Init
        data-element=COMRXL_HvCooltHeatrProtnOfSelfTmpOvrheatg_HVCHLIN18Fr02_Lin3, handle-never-received=true, init-value=constant-reference=COMRXL_HvCooltHeatrProtnOfSelfTmpOvrheatg_HVCHLIN18Fr02_Lin3_Init
        data-element=COMRXL_HvCooltHeatrSnsrFltCooltTInSnsrFlt_HVCHLIN18Fr02_Lin3, handle-never-received=true, init-value=constant-reference=COMRXL_HvCooltHeatrSnsrFltCooltTInSnsrFlt_HVCHLIN18Fr02_Lin3_Init
        data-element=COMRXL_HvCooltHeatrSnsrFltCooltTOutSnsrFlt_HVCHLIN18Fr02_Lin3, handle-never-received=true, init-value=constant-reference=COMRXL_HvCooltHeatrSnsrFltCooltTOutSnsrFlt_HVCHLIN18Fr02_Lin3_Init
        data-element=COMRXL_HvCooltHeatrSnsrFltTInMtrlSnsrFlt_HVCHLIN18Fr02_Lin3, handle-never-received=true, init-value=constant-reference=COMRXL_HvCooltHeatrSnsrFltTInMtrlSnsrFlt_HVCHLIN18Fr02_Lin3_Init
        data-element=COMRXL_HvCooltHeatrSrvRqrdCircForDrvrShoOrOpen_HVCHLIN18Fr02_Lin3, handle-never-received=true, init-value=constant-reference=COMRXL_HvCooltHeatrSrvRqrdCircForDrvrShoOrOpen_HVCHLIN18Fr02_Lin3_Init
        data-element=COMRXL_HvCooltHeatrSrvRqrdICnsOutOfRng_HVCHLIN18Fr02_Lin3, handle-never-received=true, init-value=constant-reference=COMRXL_HvCooltHeatrSrvRqrdICnsOutOfRng_HVCHLIN18Fr02_Lin3_Init
        data-element=COMRXL_HvCooltHeatrSrvRqrdMemErr_HVCHLIN18Fr02_Lin3, handle-never-received=true, init-value=constant-reference=COMRXL_HvCooltHeatrSrvRqrdMemErr_HVCHLIN18Fr02_Lin3_Init
        data-element=COMRXL_HvCooltHeatrSrvRqrdSrvRqrd_HVCHLIN18Fr02_Lin3, handle-never-received=true, init-value=constant-reference=COMRXL_HvCooltHeatrSrvRqrdSrvRqrd_HVCHLIN18Fr02_Lin3_Init
        data-element=COMRXL_EOPB_RPM_TGT_EOPB_STAT_Lin3, handle-never-received=true, init-value=constant-reference=COMRXL_EOPB_RPM_TGT_EOPB_STAT_Lin3_Init
        data-element=COMRXL_EOPB_RPM_ACTL_EOPB_STAT_Lin3, handle-never-received=true, init-value=constant-reference=COMRXL_EOPB_RPM_ACTL_EOPB_STAT_Lin3_Init
        data-element=COMRXL_EOPB_VLTG_EOPB_STAT_Lin3, handle-never-received=true, init-value=constant-reference=COMRXL_EOPB_VLTG_EOPB_STAT_Lin3_Init
        data-element=COMRXL_EOPB_TEMP_EOPB_STAT_Lin3, handle-never-received=true, init-value=constant-reference=COMRXL_EOPB_TEMP_EOPB_STAT_Lin3_Init
        data-element=COMRXL_EOPB_CURR_EOPB_STAT_Lin3, handle-never-received=true, init-value=constant-reference=COMRXL_EOPB_CURR_EOPB_STAT_Lin3_Init
        data-element=COMRXL_EOPB_LOW_TMP_STAT_EOPB_STAT_Lin3, handle-never-received=true, init-value=constant-reference=COMRXL_EOPB_LOW_TMP_STAT_EOPB_STAT_Lin3_Init
        data-element=COMRXL_EOPB_MONTRNG_RPM_EOPB_STAT_Lin3, handle-never-received=true, init-value=constant-reference=COMRXL_EOPB_MONTRNG_RPM_EOPB_STAT_Lin3_Init
        data-element=COMRXL_EOPB_LMP_HM_AN_ON_EOPB_STAT_Lin3, handle-never-received=true, init-value=constant-reference=COMRXL_EOPB_LMP_HM_AN_ON_EOPB_STAT_Lin3_Init
        data-element=COMRXL_EOPB_OV_TMP_ER_EOPB_STAT_Lin3, handle-never-received=true, init-value=constant-reference=COMRXL_EOPB_OV_TMP_ER_EOPB_STAT_Lin3_Init
        data-element=COMRXL_EOPB_OV_CUR_ER_EOPB_STAT_Lin3, handle-never-received=true, init-value=constant-reference=COMRXL_EOPB_OV_CUR_ER_EOPB_STAT_Lin3_Init
        data-element=COMRXL_EOPB_DR_RN_ER_EOPB_STAT_Lin3, handle-never-received=true, init-value=constant-reference=COMRXL_EOPB_DR_RN_ER_EOPB_STAT_Lin3_Init
        data-element=COMRXL_EOPB_VLTG_ER_EOPB_STAT_Lin3, handle-never-received=true, init-value=constant-reference=COMRXL_EOPB_VLTG_ER_EOPB_STAT_Lin3_Init
        data-element=COMRXL_EOPB_Stall_Event_EOPB_STAT_Lin3, handle-never-received=true, init-value=constant-reference=COMRXL_EOPB_Stall_Event_EOPB_STAT_Lin3_Init
        data-element=COMRXL_EOPB_POST_RUN_STAT_EOPB_STAT_Lin3, handle-never-received=true, init-value=constant-reference=COMRXL_EOPB_POST_RUN_STAT_EOPB_STAT_Lin3_Init
        data-element=COMRXL_RsErr_EOPB_EOPB_STAT_Lin3, handle-never-received=true, init-value=constant-reference=COMRXL_RsErr_EOPB_EOPB_STAT_Lin3_Init
        data-element=COMRXL_EOPB_OIL_TEMP_EOPB_STAT2_Lin3, handle-never-received=true, init-value=constant-reference=COMRXL_EOPB_OIL_TEMP_EOPB_STAT2_Lin3_Init
        data-element=COMRXL_EOPB_HW_VER_EOPB_VER_Lin3, handle-never-received=true, init-value=constant-reference=COMRXL_EOPB_HW_VER_EOPB_VER_Lin3_Init
        data-element=COMRXL_EOPB_SW_VER_EOPB_VER_Lin3, handle-never-received=true, init-value=constant-reference=COMRXL_EOPB_SW_VER_EOPB_VER_Lin3_Init
        data-element=COMRXL_HTLBV_PosAct_HTLBV_STAT_Lin3, handle-never-received=true, init-value=constant-reference=COMRXL_HTLBV_PosAct_HTLBV_STAT_Lin3_Init
        data-element=COMRXL_HTLBV_ERR_HTLBV_STAT_Lin3, handle-never-received=true, init-value=constant-reference=COMRXL_HTLBV_ERR_HTLBV_STAT_Lin3_Init
        data-element=COMRXL_HTLBV_MotorVolt_HTLBV_STAT_Lin3, handle-never-received=true, init-value=constant-reference=COMRXL_HTLBV_MotorVolt_HTLBV_STAT_Lin3_Init
        data-element=COMRXL_HTLBV_Sts_HTLBV_STAT_Lin3, handle-never-received=true, init-value=constant-reference=COMRXL_HTLBV_Sts_HTLBV_STAT_Lin3_Init
        data-element=COMRXL_RsErr_HTLBV_HTLBV_STAT_Lin3, handle-never-received=true, init-value=constant-reference=COMRXL_RsErr_HTLBV_HTLBV_STAT_Lin3_Init
        data-element=COMRXL_HTLBV_CalStat_HTLBV_STAT_Lin3, handle-never-received=true, init-value=constant-reference=COMRXL_HTLBV_CalStat_HTLBV_STAT_Lin3_Init
        data-element=COMRXL_PECP2_RPM_TGT_PERCT_PECP2_STAT_GLOBAL_Lin3, handle-never-received=true, init-value=constant-reference=COMRXL_PECP2_RPM_TGT_PERCT_PECP2_STAT_GLOBAL_Lin3_Init
        data-element=COMRXL_PECP2_RPM_ACTL_PERCT_PECP2_STAT_GLOBAL_Lin3, handle-never-received=true, init-value=constant-reference=COMRXL_PECP2_RPM_ACTL_PERCT_PECP2_STAT_GLOBAL_Lin3_Init
        data-element=COMRXL_PECP2_VLTG_PECP2_STAT_GLOBAL_Lin3, handle-never-received=true, init-value=constant-reference=COMRXL_PECP2_VLTG_PECP2_STAT_GLOBAL_Lin3_Init
        data-element=COMRXL_PECP2_TEMP_PECP2_STAT_GLOBAL_Lin3, handle-never-received=true, init-value=constant-reference=COMRXL_PECP2_TEMP_PECP2_STAT_GLOBAL_Lin3_Init
        data-element=COMRXL_PECP2_CURR_PECP2_STAT_GLOBAL_Lin3, handle-never-received=true, init-value=constant-reference=COMRXL_PECP2_CURR_PECP2_STAT_GLOBAL_Lin3_Init
        data-element=COMRXL_PECP2_FL_SAFE_ACTVTD_PECP2_STAT_GLOBAL_Lin3, handle-never-received=true, init-value=constant-reference=COMRXL_PECP2_FL_SAFE_ACTVTD_PECP2_STAT_GLOBAL_Lin3_Init
        data-element=COMRXL_PECP2_LMP_HM_AN_ON_PECP2_STAT_GLOBAL_Lin3, handle-never-received=true, init-value=constant-reference=COMRXL_PECP2_LMP_HM_AN_ON_PECP2_STAT_GLOBAL_Lin3_Init
        data-element=COMRXL_PECP2_AIR_PRE_ERR_PECP2_STAT_GLOBAL_Lin3, handle-never-received=true, init-value=constant-reference=COMRXL_PECP2_AIR_PRE_ERR_PECP2_STAT_GLOBAL_Lin3_Init
        data-element=COMRXL_PECP2_OVR_TMP_ERR_PECP2_STAT_GLOBAL_Lin3, handle-never-received=true, init-value=constant-reference=COMRXL_PECP2_OVR_TMP_ERR_PECP2_STAT_GLOBAL_Lin3_Init
        data-element=COMRXL_PECP2_OVR_CUR_ERR_PECP2_STAT_GLOBAL_Lin3, handle-never-received=true, init-value=constant-reference=COMRXL_PECP2_OVR_CUR_ERR_PECP2_STAT_GLOBAL_Lin3_Init
        data-element=COMRXL_PECP2_DR_RN_ERR_PECP2_STAT_GLOBAL_Lin3, handle-never-received=true, init-value=constant-reference=COMRXL_PECP2_DR_RN_ERR_PECP2_STAT_GLOBAL_Lin3_Init
        data-element=COMRXL_PECP2_VLTG_ERR_PECP2_STAT_GLOBAL_Lin3, handle-never-received=true, init-value=constant-reference=COMRXL_PECP2_VLTG_ERR_PECP2_STAT_GLOBAL_Lin3_Init
        data-element=COMRXL_PECP2_DBLK_ACTV_PECP2_STAT_GLOBAL_Lin3, handle-never-received=true, init-value=constant-reference=COMRXL_PECP2_DBLK_ACTV_PECP2_STAT_GLOBAL_Lin3_Init
        data-element=COMRXL_PECP2_MONTRNG_RPM_PECP2_STAT_GLOBAL_Lin3, handle-never-received=true, init-value=constant-reference=COMRXL_PECP2_MONTRNG_RPM_PECP2_STAT_GLOBAL_Lin3_Init
        data-element=COMRXL_PECP2_NODE_ERR_PECP2_STAT_GLOBAL_Lin3, handle-never-received=true, init-value=constant-reference=COMRXL_PECP2_NODE_ERR_PECP2_STAT_GLOBAL_Lin3_Init
        data-element=COMRXL_PECP2_POST_RUN_STAT_PECP2_STAT_GLOBAL_Lin3, handle-never-received=true, init-value=constant-reference=COMRXL_PECP2_POST_RUN_STAT_PECP2_STAT_GLOBAL_Lin3_Init
        data-element=COMRXL_RsErr_PECP2_PUMP_PECP2_STAT_GLOBAL_Lin3, handle-never-received=true, init-value=constant-reference=COMRXL_RsErr_PECP2_PUMP_PECP2_STAT_GLOBAL_Lin3_Init
        data-element=COMRXL_PECP2_VERSION_PECP2_VER_Lin3, handle-never-received=true, init-value=constant-reference=COMRXL_PECP2_VERSION_PECP2_VER_Lin3_Init
        data-element=COMRXL_PECP2_SUPPLIER_PECP2_VER_Lin3, handle-never-received=true, init-value=constant-reference=COMRXL_PECP2_SUPPLIER_PECP2_VER_Lin3_Init
        data-element=COMRXL_PowerPanel2_Button_State_PowerPanel2_STAT_Lin3, handle-never-received=true, init-value=constant-reference=COMRXL_PowerPanel2_Button_State_PowerPanel2_STAT_Lin3_Init
        data-element=COMRXL_PowerPanel2_Lid_Switch_Sts_120A_PowerPanel2_STAT_Lin3, handle-never-received=true, init-value=constant-reference=COMRXL_PowerPanel2_Lid_Switch_Sts_120A_PowerPanel2_STAT_Lin3_Init
        data-element=COMRXL_PowerPanel2_Lid_Switch_Sts_120B_PowerPanel2_STAT_Lin3, handle-never-received=true, init-value=constant-reference=COMRXL_PowerPanel2_Lid_Switch_Sts_120B_PowerPanel2_STAT_Lin3_Init
        data-element=COMRXL_PowerPanel2_Lid_Switch_Sts_240_PowerPanel2_STAT_Lin3, handle-never-received=true, init-value=constant-reference=COMRXL_PowerPanel2_Lid_Switch_Sts_240_PowerPanel2_STAT_Lin3_Init
        data-element=COMRXL_PowerPanel2_AC_Present_Sens1_PowerPanel2_STAT_Lin3, handle-never-received=true, init-value=constant-reference=COMRXL_PowerPanel2_AC_Present_Sens1_PowerPanel2_STAT_Lin3_Init
        data-element=COMRXL_PowerPanel2_AC_Present_Sens2_PowerPanel2_STAT_Lin3, handle-never-received=true, init-value=constant-reference=COMRXL_PowerPanel2_AC_Present_Sens2_PowerPanel2_STAT_Lin3_Init
        data-element=COMRXL_PowerPanel2_Fault_Reason_PowerPanel2_STAT_Lin3, handle-never-received=true, init-value=constant-reference=COMRXL_PowerPanel2_Fault_Reason_PowerPanel2_STAT_Lin3_Init
        data-element=COMRXL_RsErr_SPP2_PowerPanel2_STAT_Lin3, handle-never-received=true, init-value=constant-reference=COMRXL_RsErr_SPP2_PowerPanel2_STAT_Lin3_Init
        data-element=COMRXL_PowerPanel2_LED_A_Feedback_PowerPanel2_STAT_Lin3, handle-never-received=true, init-value=constant-reference=COMRXL_PowerPanel2_LED_A_Feedback_PowerPanel2_STAT_Lin3_Init
        data-element=COMRXL_PowerPanel2_LED_B_Feedback_PowerPanel2_STAT_Lin3, handle-never-received=true, init-value=constant-reference=COMRXL_PowerPanel2_LED_B_Feedback_PowerPanel2_STAT_Lin3_Init
        data-element=COMRXL_PowerPanel2_LED_A_FailStatus_PowerPanel2_STAT_Lin3, handle-never-received=true, init-value=constant-reference=COMRXL_PowerPanel2_LED_A_FailStatus_PowerPanel2_STAT_Lin3_Init
        data-element=COMRXL_PowerPanel2_LED_B_FailStatus_PowerPanel2_STAT_Lin3, handle-never-received=true, init-value=constant-reference=COMRXL_PowerPanel2_LED_B_FailStatus_PowerPanel2_STAT_Lin3_Init
        data-element=COMRXL_PowerPanel2_LED_A_Color_Feedback_PowerPanel2_STAT_Lin3, handle-never-received=true, init-value=constant-reference=COMRXL_PowerPanel2_LED_A_Color_Feedback_PowerPanel2_STAT_Lin3_Init
        data-element=COMRXL_PowerPanel2_LED_B_Color_Feedback_PowerPanel2_STAT_Lin3, handle-never-received=true, init-value=constant-reference=COMRXL_PowerPanel2_LED_B_Color_Feedback_PowerPanel2_STAT_Lin3_Init
        data-element=COMRXL_PowerPanel2_LIN_Checksum_Error_PowerPanel2_STAT_Lin3, handle-never-received=true, init-value=constant-reference=COMRXL_PowerPanel2_LIN_Checksum_Error_PowerPanel2_STAT_Lin3_Init
        data-element=COMRXL_PowerPanel2_LIN_Data_Error_PowerPanel2_STAT_Lin3, handle-never-received=true, init-value=constant-reference=COMRXL_PowerPanel2_LIN_Data_Error_PowerPanel2_STAT_Lin3_Init
        data-element=COMRXL_PowerPanel2_LIN_Parity_Error_PowerPanel2_STAT_Lin3, handle-never-received=true, init-value=constant-reference=COMRXL_PowerPanel2_LIN_Parity_Error_PowerPanel2_STAT_Lin3_Init
        data-element=COMRXL_PowerPanel2_Gnd_Fault_Detected_PowerPanel2_STAT_Lin3, handle-never-received=true, init-value=constant-reference=COMRXL_PowerPanel2_Gnd_Fault_Detected_PowerPanel2_STAT_Lin3_Init
        data-element=COMRXL_PowerPanel2_Current_Draw_Sens1_PowerPanel2_STAT_Lin3, handle-never-received=true, init-value=constant-reference=COMRXL_PowerPanel2_Current_Draw_Sens1_PowerPanel2_STAT_Lin3_Init
        data-element=COMRXL_PowerPanel2_Current_Draw_Sens2_PowerPanel2_STAT_Lin3, handle-never-received=true, init-value=constant-reference=COMRXL_PowerPanel2_Current_Draw_Sens2_PowerPanel2_STAT_Lin3_Init
        data-element=COMRXL_PowerPanel2_Fault_PowerPanel2_STAT_Lin3, handle-never-received=true, init-value=constant-reference=COMRXL_PowerPanel2_Fault_PowerPanel2_STAT_Lin3_Init
        data-element=COMRXL_PowerPanel2_RatedPower_PowerPanel2_STAT_Lin3, handle-never-received=true, init-value=constant-reference=COMRXL_PowerPanel2_RatedPower_PowerPanel2_STAT_Lin3_Init
    27 x provide port:
      VeLINR_Pct_AHP_RPM_TGT_PERCT: nonqueued-sender-com-spec{data-element=VeLINR_Pct_AHP_RPM_TGT_PERCT, init-value=VeLINR_Pct_AHP_RPM_TGT_PERCTValue:100.3935}, provided-interface=VeLINR_Pct_AHP_RPM_TGT_PERCT
      VeLINR_Pct_AHP_RPM_ACTL_PERCT: nonqueued-sender-com-spec{data-element=VeLINR_Pct_AHP_RPM_ACTL_PERCT, init-value=VeLINR_Pct_AHP_RPM_ACTL_PERCTValue:100.3935}, provided-interface=VeLINR_Pct_AHP_RPM_ACTL_PERCT
      VeLINR_U_AHP_VLTG: nonqueued-sender-com-spec{data-element=VeLINR_U_AHP_VLTG, init-value=VeLINR_U_AHP_VLTGValue:25.5}, provided-interface=VeLINR_U_AHP_VLTG
      VeLINR_T_AHP_TEMP: nonqueued-sender-com-spec{data-element=VeLINR_T_AHP_TEMP, init-value=VeLINR_T_AHP_TEMPValue:205}, provided-interface=VeLINR_T_AHP_TEMP
      VeLINR_I_AHP_CURR: nonqueued-sender-com-spec{data-element=VeLINR_I_AHP_CURR, init-value=VeLINR_I_AHP_CURRValue:51}, provided-interface=VeLINR_I_AHP_CURR
      VeLINR_Pct_BHV_PosAct: nonqueued-sender-com-spec{data-element=VeLINR_Pct_BHV_PosAct, init-value=VeLINR_Pct_BHV_PosActValue:0}, provided-interface=VeLINR_Pct_BHV_PosAct
      VeLINR_n_CompressorSpd: nonqueued-sender-com-spec{data-element=VeLINR_n_CompressorSpd, init-value=VeLINR_n_CompressorSpdValue:0}, provided-interface=VeLINR_n_CompressorSpd
      VeLINR_P_CompElecPwr: nonqueued-sender-com-spec{data-element=VeLINR_P_CompElecPwr, init-value=VeLINR_P_CompElecPwrValue:0}, provided-interface=VeLINR_P_CompElecPwr
      VeLINR_T_CompBoardTemp: nonqueued-sender-com-spec{data-element=VeLINR_T_CompBoardTemp, init-value=VeLINR_T_CompBoardTempValue:-40}, provided-interface=VeLINR_T_CompBoardTemp
      VeLINR_T_CompIGBTTemp: nonqueued-sender-com-spec{data-element=VeLINR_T_CompIGBTTemp, init-value=VeLINR_T_CompIGBTTempValue:-40}, provided-interface=VeLINR_T_CompIGBTTemp
      VeLINR_I_CompElecCurr: nonqueued-sender-com-spec{data-element=VeLINR_I_CompElecCurr, init-value=VeLINR_I_CompElecCurrValue:0}, provided-interface=VeLINR_I_CompElecCurr
      VeLINR_U_CompHVInput: nonqueued-sender-com-spec{data-element=VeLINR_U_CompHVInput, init-value=VeLINR_U_CompHVInputValue:0}, provided-interface=VeLINR_U_CompHVInput
      VeLINR_Pct_PECP_RPM_TGT_PERCT: nonqueued-sender-com-spec{data-element=VeLINR_Pct_PECP_RPM_TGT_PERCT, init-value=VeLINR_Pct_PECP_RPM_TGT_PERCTValue:100.3935}, provided-interface=VeLINR_Pct_PECP_RPM_TGT_PERCT
      VeLINR_Pct_PECP_RPM_ACTL_PERCT: nonqueued-sender-com-spec{data-element=VeLINR_Pct_PECP_RPM_ACTL_PERCT, init-value=VeLINR_Pct_PECP_RPM_ACTL_PERCTValue:100.3935}, provided-interface=VeLINR_Pct_PECP_RPM_ACTL_PERCT
      VeLINR_U_PECP_VLTG: nonqueued-sender-com-spec{data-element=VeLINR_U_PECP_VLTG, init-value=VeLINR_U_PECP_VLTGValue:25.5}, provided-interface=VeLINR_U_PECP_VLTG
      VeLINR_T_PECP_TEMP: nonqueued-sender-com-spec{data-element=VeLINR_T_PECP_TEMP, init-value=VeLINR_T_PECP_TEMPValue:205}, provided-interface=VeLINR_T_PECP_TEMP
      VeLINR_I_PECP_CURR: nonqueued-sender-com-spec{data-element=VeLINR_I_PECP_CURR, init-value=VeLINR_I_PECP_CURRValue:51}, provided-interface=VeLINR_I_PECP_CURR
      VeLINR_I_PwrPanelCurrDrawSens1: nonqueued-sender-com-spec{data-element=VeLINR_I_PwrPanelCurrDrawSens1, init-value=VeLINR_I_PwrPanelCurrDrawSens1Value:0}, provided-interface=VeLINR_I_PwrPanelCurrDrawSens1
      VeLINR_b_PowerPanelButton_State: nonqueued-sender-com-spec{data-element=VeLINR_b_PowerPanelButton_State, init-value=VeLINR_b_PowerPanelButton_StateValue:0}, provided-interface=VeLINR_b_PowerPanelButton_State
      VeLINR_b_PwrPanelLidSwtSts120A: nonqueued-sender-com-spec{data-element=VeLINR_b_PwrPanelLidSwtSts120A, init-value=VeLINR_b_PwrPanelLidSwtSts120AValue:0}, provided-interface=VeLINR_b_PwrPanelLidSwtSts120A
      VeLINR_b_PwrPanelLidSwtSts120B: nonqueued-sender-com-spec{data-element=VeLINR_b_PwrPanelLidSwtSts120B, init-value=VeLINR_b_PwrPanelLidSwtSts120BValue:0}, provided-interface=VeLINR_b_PwrPanelLidSwtSts120B
      VeLINR_b_PwrPanelLidSwtSts240: nonqueued-sender-com-spec{data-element=VeLINR_b_PwrPanelLidSwtSts240, init-value=VeLINR_b_PwrPanelLidSwtSts240Value:0}, provided-interface=VeLINR_b_PwrPanelLidSwtSts240
      VeLINR_b_PwrPanelAC_PresntSens1: nonqueued-sender-com-spec{data-element=VeLINR_b_PwrPanelAC_PresntSens1, init-value=VeLINR_b_PwrPanelAC_PresntSens1Value:0}, provided-interface=VeLINR_b_PwrPanelAC_PresntSens1
      VeLINR_b_PwrPanelAC_PresntSens2: nonqueued-sender-com-spec{data-element=VeLINR_b_PwrPanelAC_PresntSens2, init-value=VeLINR_b_PwrPanelAC_PresntSens2Value:0}, provided-interface=VeLINR_b_PwrPanelAC_PresntSens2
      VeLINR_I_PwrPanelCurrDrawSens2: nonqueued-sender-com-spec{data-element=VeLINR_I_PwrPanelCurrDrawSens2, init-value=VeLINR_I_PwrPanelCurrDrawSens2Value:0}, provided-interface=VeLINR_I_PwrPanelCurrDrawSens2
      VeLINR_e_PowerPanel_FaultReason: nonqueued-sender-com-spec{data-element=VeLINR_e_PowerPanel_FaultReason, init-value=VeLINR_e_PowerPanel_FaultReasonValue:0}, provided-interface=VeLINR_e_PowerPanel_FaultReason
      VeLINR_b_RsErr_SPP: nonqueued-sender-com-spec{data-element=VeLINR_b_RsErr_SPP, init-value=VeLINR_b_RsErr_SPPValue:0}, provided-interface=VeLINR_b_RsErr_SPP
    16 x require port:
      SendLINR_AAD_PosRq: nonqueued-receiver-com-spec{data-element=SendLINR_AAD_PosRq, init-value=SendLINR_AAD_PosRqValue:15}, required-interface=SendLINR_AAD_PosRq
      SendLINR_AAD_CalRq: nonqueued-receiver-com-spec{data-element=SendLINR_AAD_CalRq, init-value=SendLINR_AAD_CalRqValue:0}, required-interface=SendLINR_AAD_CalRq
      SendLINR_AAD_InitialIP_CalRq: nonqueued-receiver-com-spec{data-element=SendLINR_AAD_InitialIP_CalRq, init-value=0}, required-interface=SendLINR_AAD_InitialIP_CalRq
      SendLINR_BCP_RPM_REQ: nonqueued-receiver-com-spec{data-element=SendLINR_BCP_RPM_REQ, init-value=SendLINR_BCP_RPM_REQValue:100.3935}, required-interface=SendLINR_BCP_RPM_REQ
      SendLINR_BCP_POST_RUN_REQ: nonqueued-receiver-com-spec{data-element=SendLINR_BCP_POST_RUN_REQ, init-value=SendLINR_BCP_POST_RUN_REQValue:7}, required-interface=SendLINR_BCP_POST_RUN_REQ
      SendLINR_BCP_FL_SAFE_ACTVT: nonqueued-receiver-com-spec{data-element=SendLINR_BCP_FL_SAFE_ACTVT, init-value=SendLINR_BCP_FL_SAFE_ACTVTValue:3}, required-interface=SendLINR_BCP_FL_SAFE_ACTVT
      SendLINR_CPV_PosRq: nonqueued-receiver-com-spec{data-element=SendLINR_CPV_PosRq, init-value=SendLINR_CPV_PosRqValue:0}, required-interface=SendLINR_CPV_PosRq
      SendLINR_CPV_PosSv: nonqueued-receiver-com-spec{data-element=SendLINR_CPV_PosSv, init-value=SendLINR_CPV_PosSvValue:0}, required-interface=SendLINR_CPV_PosSv
      SendLINR_CPV_CalRq: nonqueued-receiver-com-spec{data-element=SendLINR_CPV_CalRq, init-value=SendLINR_CPV_CalRqValue:0}, required-interface=SendLINR_CPV_CalRq
      SendLINR_AirHeatrPwrTgt: nonqueued-receiver-com-spec{data-element=SendLINR_AirHeatrPwrTgt, init-value=SendLINR_AirHeatrPwrTgtValue:255}, required-interface=SendLINR_AirHeatrPwrTgt
      SendLINR_AirHeatrEnad: nonqueued-receiver-com-spec{data-element=SendLINR_AirHeatrEnad, init-value=SendLINR_AirHeatrEnadValue:0}, required-interface=SendLINR_AirHeatrEnad
      SendLINR_EOPA_RPM_COM: nonqueued-receiver-com-spec{data-element=SendLINR_EOPA_RPM_COM, init-value=SendLINR_EOPA_RPM_COMValue:6120}, required-interface=SendLINR_EOPA_RPM_COM
      SendLINR_EOPA_POST_RUN_COM: nonqueued-receiver-com-spec{data-element=SendLINR_EOPA_POST_RUN_COM, init-value=SendLINR_EOPA_POST_RUN_COMValue:7}, required-interface=SendLINR_EOPA_POST_RUN_COM
      SendLINR_LTRBV_PosRq: nonqueued-receiver-com-spec{data-element=SendLINR_LTRBV_PosRq, init-value=SendLINR_LTRBV_PosRqValue:0}, required-interface=SendLINR_LTRBV_PosRq
      SendLINR_LTRBV_PosSv: nonqueued-receiver-com-spec{data-element=SendLINR_LTRBV_PosSv, init-value=SendLINR_LTRBV_PosSvValue:0}, required-interface=SendLINR_LTRBV_PosSv
      SendLINR_LTRBV_CalRq: nonqueued-receiver-com-spec{data-element=SendLINR_LTRBV_CalRq, init-value=SendLINR_LTRBV_CalRqValue:0}, required-interface=SendLINR_LTRBV_CalRq
    75 x provide port:
      VeLINR_b_AGS2_CurrPosTO: nonqueued-sender-com-spec{data-element=VeLINR_b_AGS2_CurrPosTO, init-value=VeLINR_b_AGS2_CurrPosTOValue:0}, provided-interface=VeLINR_b_AGS2_CurrPosTO
      VeLINR_b_AGS2_CalStatTO: nonqueued-sender-com-spec{data-element=VeLINR_b_AGS2_CalStatTO, init-value=VeLINR_b_AGS2_CalStatTOValue:0}, provided-interface=VeLINR_b_AGS2_CalStatTO
      VeLINR_b_AGS2_CalActvTO: nonqueued-sender-com-spec{data-element=VeLINR_b_AGS2_CalActvTO, init-value=VeLINR_b_AGS2_CalActvTOValue:0}, provided-interface=VeLINR_b_AGS2_CalActvTO
      VeLINR_b_AGS2_ErrUnVoltTO: nonqueued-sender-com-spec{data-element=VeLINR_b_AGS2_ErrUnVoltTO, init-value=VeLINR_b_AGS2_ErrUnVoltTOValue:0}, provided-interface=VeLINR_b_AGS2_ErrUnVoltTO
      VeLINR_b_AGS2_ErrOvrVoltTO: nonqueued-sender-com-spec{data-element=VeLINR_b_AGS2_ErrOvrVoltTO, init-value=VeLINR_b_AGS2_ErrOvrVoltTOValue:0}, provided-interface=VeLINR_b_AGS2_ErrOvrVoltTO
      VeLINR_b_AGS2_ErrOvrTempTO: nonqueued-sender-com-spec{data-element=VeLINR_b_AGS2_ErrOvrTempTO, init-value=VeLINR_b_AGS2_ErrOvrTempTOValue:0}, provided-interface=VeLINR_b_AGS2_ErrOvrTempTO
      VeLINR_b_AGS2_ErrMechStuckTO: nonqueued-sender-com-spec{data-element=VeLINR_b_AGS2_ErrMechStuckTO, init-value=VeLINR_b_AGS2_ErrMechStuckTOValue:0}, provided-interface=VeLINR_b_AGS2_ErrMechStuckTO
      VeLINR_b_AGS2_ErrMechBreakTO: nonqueued-sender-com-spec{data-element=VeLINR_b_AGS2_ErrMechBreakTO, init-value=VeLINR_b_AGS2_ErrMechBreakTOValue:0}, provided-interface=VeLINR_b_AGS2_ErrMechBreakTO
      VeLINR_b_AGS2_ErrLIN_TO: nonqueued-sender-com-spec{data-element=VeLINR_b_AGS2_ErrLIN_TO, init-value=VeLINR_b_AGS2_ErrLIN_TOValue:0}, provided-interface=VeLINR_b_AGS2_ErrLIN_TO
      VeLINR_b_RsErr_AGS2TO: nonqueued-sender-com-spec{data-element=VeLINR_b_RsErr_AGS2TO, init-value=VeLINR_b_RsErr_AGS2TOValue:0}, provided-interface=VeLINR_b_RsErr_AGS2TO
      VeLINR_b_AGS2_BoostStatTO: nonqueued-sender-com-spec{data-element=VeLINR_b_AGS2_BoostStatTO, init-value=VeLINR_b_AGS2_BoostStatTOValue:0}, provided-interface=VeLINR_b_AGS2_BoostStatTO
      VeLINR_b_S2MResBit1_AGS2TO: nonqueued-sender-com-spec{data-element=VeLINR_b_S2MResBit1_AGS2TO, init-value=VeLINR_b_S2MResBit1_AGS2TOValue:0}, provided-interface=VeLINR_b_S2MResBit1_AGS2TO
      VeLINR_b_AHP_RPM_TGT_PERCT_TO: nonqueued-sender-com-spec{data-element=VeLINR_b_AHP_RPM_TGT_PERCT_TO, init-value=VeLINR_b_AHP_RPM_TGT_PERCT_TOValue:0}, provided-interface=VeLINR_b_AHP_RPM_TGT_PERCT_TO
      VeLINR_b_AHP_RPM_ACTL_PERCT_TO: nonqueued-sender-com-spec{data-element=VeLINR_b_AHP_RPM_ACTL_PERCT_TO, init-value=VeLINR_b_AHP_RPM_ACTL_PERCT_TOValue:0}, provided-interface=VeLINR_b_AHP_RPM_ACTL_PERCT_TO
      VeLINR_b_AHP_VLTG_TO: nonqueued-sender-com-spec{data-element=VeLINR_b_AHP_VLTG_TO, init-value=VeLINR_b_AHP_VLTG_TOValue:0}, provided-interface=VeLINR_b_AHP_VLTG_TO
      VeLINR_b_AHP_TEMP_TO: nonqueued-sender-com-spec{data-element=VeLINR_b_AHP_TEMP_TO, init-value=VeLINR_b_AHP_TEMP_TOValue:0}, provided-interface=VeLINR_b_AHP_TEMP_TO
      VeLINR_b_AHP_CURR_TO: nonqueued-sender-com-spec{data-element=VeLINR_b_AHP_CURR_TO, init-value=VeLINR_b_AHP_CURR_TOValue:0}, provided-interface=VeLINR_b_AHP_CURR_TO
      VeLINR_b_AHP_FL_SAFE_ACTVTD_TO: nonqueued-sender-com-spec{data-element=VeLINR_b_AHP_FL_SAFE_ACTVTD_TO, init-value=VeLINR_b_AHP_FL_SAFE_ACTVTD_TOValue:0}, provided-interface=VeLINR_b_AHP_FL_SAFE_ACTVTD_TO
      VeLINR_b_AHP_LMP_HM_AN_ON_TO: nonqueued-sender-com-spec{data-element=VeLINR_b_AHP_LMP_HM_AN_ON_TO, init-value=VeLINR_b_AHP_LMP_HM_AN_ON_TOValue:0}, provided-interface=VeLINR_b_AHP_LMP_HM_AN_ON_TO
      VeLINR_b_AHP_AIR_PRE_ERR_TO: nonqueued-sender-com-spec{data-element=VeLINR_b_AHP_AIR_PRE_ERR_TO, init-value=VeLINR_b_AHP_AIR_PRE_ERR_TOValue:0}, provided-interface=VeLINR_b_AHP_AIR_PRE_ERR_TO
      VeLINR_b_AHP_OVR_TMP_ERR_TO: nonqueued-sender-com-spec{data-element=VeLINR_b_AHP_OVR_TMP_ERR_TO, init-value=VeLINR_b_AHP_OVR_TMP_ERR_TOValue:0}, provided-interface=VeLINR_b_AHP_OVR_TMP_ERR_TO
      VeLINR_b_AHP_OVR_CUR_ERR_TO: nonqueued-sender-com-spec{data-element=VeLINR_b_AHP_OVR_CUR_ERR_TO, init-value=VeLINR_b_AHP_OVR_CUR_ERR_TOValue:0}, provided-interface=VeLINR_b_AHP_OVR_CUR_ERR_TO
      VeLINR_b_AHP_DR_RN_ERR_TO: nonqueued-sender-com-spec{data-element=VeLINR_b_AHP_DR_RN_ERR_TO, init-value=VeLINR_b_AHP_DR_RN_ERR_TOValue:0}, provided-interface=VeLINR_b_AHP_DR_RN_ERR_TO
      VeLINR_b_AHP_VLTG_ERR_TO: nonqueued-sender-com-spec{data-element=VeLINR_b_AHP_VLTG_ERR_TO, init-value=VeLINR_b_AHP_VLTG_ERR_TOValue:0}, provided-interface=VeLINR_b_AHP_VLTG_ERR_TO
      VeLINR_b_AHP_DBLK_ACTV_TO: nonqueued-sender-com-spec{data-element=VeLINR_b_AHP_DBLK_ACTV_TO, init-value=VeLINR_b_AHP_DBLK_ACTV_TOValue:0}, provided-interface=VeLINR_b_AHP_DBLK_ACTV_TO
      VeLINR_b_AHP_MONTRNG_RPM_TO: nonqueued-sender-com-spec{data-element=VeLINR_b_AHP_MONTRNG_RPM_TO, init-value=VeLINR_b_AHP_MONTRNG_RPM_TOValue:0}, provided-interface=VeLINR_b_AHP_MONTRNG_RPM_TO
      VeLINR_b_AHP_NODE_ERR_TO: nonqueued-sender-com-spec{data-element=VeLINR_b_AHP_NODE_ERR_TO, init-value=VeLINR_b_AHP_NODE_ERR_TOValue:0}, provided-interface=VeLINR_b_AHP_NODE_ERR_TO
      VeLINR_b_AHP_POST_RUN_STAT_TO: nonqueued-sender-com-spec{data-element=VeLINR_b_AHP_POST_RUN_STAT_TO, init-value=VeLINR_b_AHP_POST_RUN_STAT_TOValue:0}, provided-interface=VeLINR_b_AHP_POST_RUN_STAT_TO
      VeLINR_b_RsErr_AHP_PUMP_TO: nonqueued-sender-com-spec{data-element=VeLINR_b_RsErr_AHP_PUMP_TO, init-value=VeLINR_b_RsErr_AHP_PUMP_TOValue:0}, provided-interface=VeLINR_b_RsErr_AHP_PUMP_TO
      VeLINR_b_AHP_SUPPLIER_TO: nonqueued-sender-com-spec{data-element=VeLINR_b_AHP_SUPPLIER_TO, init-value=VeLINR_b_AHP_SUPPLIER_TOValue:0}, provided-interface=VeLINR_b_AHP_SUPPLIER_TO
      VeLINR_b_BHV_PosActTO: nonqueued-sender-com-spec{data-element=VeLINR_b_BHV_PosActTO, init-value=VeLINR_b_BHV_PosActTOValue:0}, provided-interface=VeLINR_b_BHV_PosActTO
      VeLINR_b_BHV_ERR_TO: nonqueued-sender-com-spec{data-element=VeLINR_b_BHV_ERR_TO, init-value=VeLINR_b_BHV_ERR_TOValue:0}, provided-interface=VeLINR_b_BHV_ERR_TO
      VeLINR_b_BHV_StsTO: nonqueued-sender-com-spec{data-element=VeLINR_b_BHV_StsTO, init-value=VeLINR_b_BHV_StsTOValue:0}, provided-interface=VeLINR_b_BHV_StsTO
      VeLINR_b_RsErr_BHV_TO: nonqueued-sender-com-spec{data-element=VeLINR_b_RsErr_BHV_TO, init-value=VeLINR_b_RsErr_BHV_TOValue:0}, provided-interface=VeLINR_b_RsErr_BHV_TO
      VeLINR_b_CompFaultStatTO: nonqueued-sender-com-spec{data-element=VeLINR_b_CompFaultStatTO, init-value=VeLINR_b_CompFaultStatTOValue:0}, provided-interface=VeLINR_b_CompFaultStatTO
      VeLINR_b_CompStatTO: nonqueued-sender-com-spec{data-element=VeLINR_b_CompStatTO, init-value=VeLINR_b_CompStatTOValue:0}, provided-interface=VeLINR_b_CompStatTO
      VeLINR_b_CompressorSpdTO: nonqueued-sender-com-spec{data-element=VeLINR_b_CompressorSpdTO, init-value=VeLINR_b_CompressorSpdTOValue:0}, provided-interface=VeLINR_b_CompressorSpdTO
      VeLINR_b_CompSpdIncrReqTO: nonqueued-sender-com-spec{data-element=VeLINR_b_CompSpdIncrReqTO, init-value=VeLINR_b_CompSpdIncrReqTOValue:0}, provided-interface=VeLINR_b_CompSpdIncrReqTO
      VeLINR_b_CompElecPwrTO: nonqueued-sender-com-spec{data-element=VeLINR_b_CompElecPwrTO, init-value=VeLINR_b_CompElecPwrTOValue:0}, provided-interface=VeLINR_b_CompElecPwrTO
      VeLINR_b_CompBoardTempTO: nonqueued-sender-com-spec{data-element=VeLINR_b_CompBoardTempTO, init-value=VeLINR_b_CompBoardTempTOValue:0}, provided-interface=VeLINR_b_CompBoardTempTO
      VeLINR_b_CompIGBTTempTO: nonqueued-sender-com-spec{data-element=VeLINR_b_CompIGBTTempTO, init-value=VeLINR_b_CompIGBTTempTOValue:0}, provided-interface=VeLINR_b_CompIGBTTempTO
      VeLINR_b_CompElecCurrTO: nonqueued-sender-com-spec{data-element=VeLINR_b_CompElecCurrTO, init-value=VeLINR_b_CompElecCurrTOValue:0}, provided-interface=VeLINR_b_CompElecCurrTO
      VeLINR_b_CompHVInputTO: nonqueued-sender-com-spec{data-element=VeLINR_b_CompHVInputTO, init-value=VeLINR_b_CompHVInputTOValue:0}, provided-interface=VeLINR_b_CompHVInputTO
      VeLINR_b_DriveMdReqTO: nonqueued-sender-com-spec{data-element=VeLINR_b_DriveMdReqTO, init-value=VeLINR_b_DriveMdReqTOValue:0}, provided-interface=VeLINR_b_DriveMdReqTO
      VeLINR_b_HybridModeRq_LIN_TO: nonqueued-sender-com-spec{data-element=VeLINR_b_HybridModeRq_LIN_TO, init-value=VeLINR_b_HybridModeRq_LIN_TOValue:0}, provided-interface=VeLINR_b_HybridModeRq_LIN_TO
      VeLINR_b_ESaveModeRq_LIN_TO: nonqueued-sender-com-spec{data-element=VeLINR_b_ESaveModeRq_LIN_TO, init-value=VeLINR_b_ESaveModeRq_LIN_TOValue:0}, provided-interface=VeLINR_b_ESaveModeRq_LIN_TO
      VeLINR_b_ElectricModeRq_LIN_TO: nonqueued-sender-com-spec{data-element=VeLINR_b_ElectricModeRq_LIN_TO, init-value=VeLINR_b_ElectricModeRq_LIN_TOValue:0}, provided-interface=VeLINR_b_ElectricModeRq_LIN_TO
      VeLINR_b_RsErr_ESBM_TO: nonqueued-sender-com-spec{data-element=VeLINR_b_RsErr_ESBM_TO, init-value=VeLINR_b_RsErr_ESBM_TOValue:0}, provided-interface=VeLINR_b_RsErr_ESBM_TO
      VeLINR_b_Refrig_Temp_LIN2TO: nonqueued-sender-com-spec{data-element=VeLINR_b_Refrig_Temp_LIN2TO, init-value=VeLINR_b_Refrig_Temp_LIN2TOValue:0}, provided-interface=VeLINR_b_Refrig_Temp_LIN2TO
      VeLINR_b_PECP_RPM_TGT_PERCT_TO: nonqueued-sender-com-spec{data-element=VeLINR_b_PECP_RPM_TGT_PERCT_TO, init-value=VeLINR_b_PECP_RPM_TGT_PERCT_TOValue:0}, provided-interface=VeLINR_b_PECP_RPM_TGT_PERCT_TO
      VeLINR_b_PECP_RPM_ACTL_PERCT_TO: nonqueued-sender-com-spec{data-element=VeLINR_b_PECP_RPM_ACTL_PERCT_TO, init-value=VeLINR_b_PECP_RPM_ACTL_PERCT_TOValue:0}, provided-interface=VeLINR_b_PECP_RPM_ACTL_PERCT_TO
      VeLINR_b_PECP_VLTG_TO: nonqueued-sender-com-spec{data-element=VeLINR_b_PECP_VLTG_TO, init-value=VeLINR_b_PECP_VLTG_TOValue:0}, provided-interface=VeLINR_b_PECP_VLTG_TO
      VeLINR_b_PECP_TEMP_TO: nonqueued-sender-com-spec{data-element=VeLINR_b_PECP_TEMP_TO, init-value=VeLINR_b_PECP_TEMP_TOValue:0}, provided-interface=VeLINR_b_PECP_TEMP_TO
      VeLINR_b_PECP_CURR_TO: nonqueued-sender-com-spec{data-element=VeLINR_b_PECP_CURR_TO, init-value=VeLINR_b_PECP_CURR_TOValue:0}, provided-interface=VeLINR_b_PECP_CURR_TO
      VeLINR_b_PECP_FL_SAFE_ACTVTD_TO: nonqueued-sender-com-spec{data-element=VeLINR_b_PECP_FL_SAFE_ACTVTD_TO, init-value=VeLINR_b_PECP_FL_SAFE_ACTVTD_TOValue:0}, provided-interface=VeLINR_b_PECP_FL_SAFE_ACTVTD_TO
      VeLINR_b_PECP_LMP_HM_AN_ON_TO: nonqueued-sender-com-spec{data-element=VeLINR_b_PECP_LMP_HM_AN_ON_TO, init-value=VeLINR_b_PECP_LMP_HM_AN_ON_TOValue:0}, provided-interface=VeLINR_b_PECP_LMP_HM_AN_ON_TO
      VeLINR_b_PECP_AIR_PRE_ERR_TO: nonqueued-sender-com-spec{data-element=VeLINR_b_PECP_AIR_PRE_ERR_TO, init-value=VeLINR_b_PECP_AIR_PRE_ERR_TOValue:0}, provided-interface=VeLINR_b_PECP_AIR_PRE_ERR_TO
      VeLINR_b_PECP_OVR_TMP_ERR_TO: nonqueued-sender-com-spec{data-element=VeLINR_b_PECP_OVR_TMP_ERR_TO, init-value=VeLINR_b_PECP_OVR_TMP_ERR_TOValue:0}, provided-interface=VeLINR_b_PECP_OVR_TMP_ERR_TO
      VeLINR_b_PECP_OVR_CUR_ERR_TO: nonqueued-sender-com-spec{data-element=VeLINR_b_PECP_OVR_CUR_ERR_TO, init-value=VeLINR_b_PECP_OVR_CUR_ERR_TOValue:0}, provided-interface=VeLINR_b_PECP_OVR_CUR_ERR_TO
      VeLINR_b_PECP_DR_RN_ERR_TO: nonqueued-sender-com-spec{data-element=VeLINR_b_PECP_DR_RN_ERR_TO, init-value=VeLINR_b_PECP_DR_RN_ERR_TOValue:0}, provided-interface=VeLINR_b_PECP_DR_RN_ERR_TO
      VeLINR_b_PECP_VLTG_ERR_TO: nonqueued-sender-com-spec{data-element=VeLINR_b_PECP_VLTG_ERR_TO, init-value=VeLINR_b_PECP_VLTG_ERR_TOValue:0}, provided-interface=VeLINR_b_PECP_VLTG_ERR_TO
      VeLINR_b_PECP_DBLK_ACTV_TO: nonqueued-sender-com-spec{data-element=VeLINR_b_PECP_DBLK_ACTV_TO, init-value=VeLINR_b_PECP_DBLK_ACTV_TOValue:0}, provided-interface=VeLINR_b_PECP_DBLK_ACTV_TO
      VeLINR_b_PECP_MONTRNG_RPM_TO: nonqueued-sender-com-spec{data-element=VeLINR_b_PECP_MONTRNG_RPM_TO, init-value=VeLINR_b_PECP_MONTRNG_RPM_TOValue:0}, provided-interface=VeLINR_b_PECP_MONTRNG_RPM_TO
      VeLINR_b_PECP_NODE_ERR_TO: nonqueued-sender-com-spec{data-element=VeLINR_b_PECP_NODE_ERR_TO, init-value=VeLINR_b_PECP_NODE_ERR_TOValue:0}, provided-interface=VeLINR_b_PECP_NODE_ERR_TO
      VeLINR_b_PECP_POST_RUN_STAT_TO: nonqueued-sender-com-spec{data-element=VeLINR_b_PECP_POST_RUN_STAT_TO, init-value=VeLINR_b_PECP_POST_RUN_STAT_TOValue:0}, provided-interface=VeLINR_b_PECP_POST_RUN_STAT_TO
      VeLINR_b_RsErr_PECP_PUMP_TO: nonqueued-sender-com-spec{data-element=VeLINR_b_RsErr_PECP_PUMP_TO, init-value=VeLINR_b_RsErr_PECP_PUMP_TOValue:0}, provided-interface=VeLINR_b_RsErr_PECP_PUMP_TO
      VeLINR_b_PECP_SUPPLIER_TO: nonqueued-sender-com-spec{data-element=VeLINR_b_PECP_SUPPLIER_TO, init-value=VeLINR_b_PECP_SUPPLIER_TOValue:0}, provided-interface=VeLINR_b_PECP_SUPPLIER_TO
      VeLINR_b_PowerPanelButton_StateTO: nonqueued-sender-com-spec{data-element=VeLINR_b_PowerPanelButton_StateTO, init-value=VeLINR_b_PowerPanelButton_StateTOValue:0}, provided-interface=VeLINR_b_PowerPanelButton_StateTO
      VeLINR_b_PwrPanelLidSwtSts120A_TO: nonqueued-sender-com-spec{data-element=VeLINR_b_PwrPanelLidSwtSts120A_TO, init-value=VeLINR_b_PwrPanelLidSwtSts120A_TOValue:0}, provided-interface=VeLINR_b_PwrPanelLidSwtSts120A_TO
      VeLINR_b_PwrPanelLidSwtSts120B_TO: nonqueued-sender-com-spec{data-element=VeLINR_b_PwrPanelLidSwtSts120B_TO, init-value=VeLINR_b_PwrPanelLidSwtSts120B_TOValue:0}, provided-interface=VeLINR_b_PwrPanelLidSwtSts120B_TO
      VeLINR_b_PwrPanelLidSwtSts240TO: nonqueued-sender-com-spec{data-element=VeLINR_b_PwrPanelLidSwtSts240TO, init-value=VeLINR_b_PwrPanelLidSwtSts240TOValue:0}, provided-interface=VeLINR_b_PwrPanelLidSwtSts240TO
      VeLINR_b_PwrPanelAC_PresntSens1TO: nonqueued-sender-com-spec{data-element=VeLINR_b_PwrPanelAC_PresntSens1TO, init-value=VeLINR_b_PwrPanelAC_PresntSens1TOValue:0}, provided-interface=VeLINR_b_PwrPanelAC_PresntSens1TO
      VeLINR_b_PwrPanelAC_PresntSens2TO: nonqueued-sender-com-spec{data-element=VeLINR_b_PwrPanelAC_PresntSens2TO, init-value=VeLINR_b_PwrPanelAC_PresntSens2TOValue:0}, provided-interface=VeLINR_b_PwrPanelAC_PresntSens2TO
      VeLINR_b_PowerPanel_FaultReasonTO: nonqueued-sender-com-spec{data-element=VeLINR_b_PowerPanel_FaultReasonTO, init-value=VeLINR_b_PowerPanel_FaultReasonTOValue:0}, provided-interface=VeLINR_b_PowerPanel_FaultReasonTO
      VeLINR_b_RsErr_SPP_TO: nonqueued-sender-com-spec{data-element=VeLINR_b_RsErr_SPP_TO, init-value=VeLINR_b_RsErr_SPP_TOValue:0}, provided-interface=VeLINR_b_RsErr_SPP_TO
    143 x require port:
      SendLINR_AGS2_PosRq: nonqueued-receiver-com-spec{data-element=SendLINR_AGS2_PosRq, init-value=SendLINR_AGS2_PosRqValue:0}, required-interface=SendLINR_AGS2_PosRq
      SendLINR_AGS2_PosRqVld: nonqueued-receiver-com-spec{data-element=SendLINR_AGS2_PosRqVld, init-value=SendLINR_AGS2_PosRqVldValue:1}, required-interface=SendLINR_AGS2_PosRqVld
      SendLINR_AGS2_CalRq: nonqueued-receiver-com-spec{data-element=SendLINR_AGS2_CalRq, init-value=SendLINR_AGS2_CalRqValue:0}, required-interface=SendLINR_AGS2_CalRq
      SendLINR_AGS2_CalRqVld: nonqueued-receiver-com-spec{data-element=SendLINR_AGS2_CalRqVld, init-value=SendLINR_AGS2_CalRqVldValue:1}, required-interface=SendLINR_AGS2_CalRqVld
      SendLINR_AGS2_BoostRq: nonqueued-receiver-com-spec{data-element=SendLINR_AGS2_BoostRq, init-value=SendLINR_AGS2_BoostRqValue:0}, required-interface=SendLINR_AGS2_BoostRq
      SendLINR_AGS2_BoostRqVld: nonqueued-receiver-com-spec{data-element=SendLINR_AGS2_BoostRqVld, init-value=SendLINR_AGS2_BoostRqVldValue:1}, required-interface=SendLINR_AGS2_BoostRqVld
      SendLINR_M2SRes2Bit_AGS2: nonqueued-receiver-com-spec{data-element=SendLINR_M2SRes2Bit_AGS2, init-value=SendLINR_M2SRes2Bit_AGS2Value:0}, required-interface=SendLINR_M2SRes2Bit_AGS2
      SendLINR_M2SRes2Bit_AGS2Vld: nonqueued-receiver-com-spec{data-element=SendLINR_M2SRes2Bit_AGS2Vld, init-value=SendLINR_M2SRes2Bit_AGS2VldValue:1}, required-interface=SendLINR_M2SRes2Bit_AGS2Vld
      SendLINR_M2SResByte1_AGS2: nonqueued-receiver-com-spec{data-element=SendLINR_M2SResByte1_AGS2, init-value=SendLINR_M2SResByte1_AGS2Value:0}, required-interface=SendLINR_M2SResByte1_AGS2
      SendLINR_M2SResByte1_AGS2Vld: nonqueued-receiver-com-spec{data-element=SendLINR_M2SResByte1_AGS2Vld, init-value=SendLINR_M2SResByte1_AGS2VldValue:1}, required-interface=SendLINR_M2SResByte1_AGS2Vld
      SendLINR_M2SResByte2_AGS2: nonqueued-receiver-com-spec{data-element=SendLINR_M2SResByte2_AGS2, init-value=SendLINR_M2SResByte2_AGS2Value:0}, required-interface=SendLINR_M2SResByte2_AGS2
      SendLINR_M2SResByte2_AGS2Vld: nonqueued-receiver-com-spec{data-element=SendLINR_M2SResByte2_AGS2Vld, init-value=SendLINR_M2SResByte2_AGS2VldValue:1}, required-interface=SendLINR_M2SResByte2_AGS2Vld
      SendLINR_M2SResByte3_AGS2: nonqueued-receiver-com-spec{data-element=SendLINR_M2SResByte3_AGS2, init-value=SendLINR_M2SResByte3_AGS2Value:0}, required-interface=SendLINR_M2SResByte3_AGS2
      SendLINR_M2SResByte3_AGS2Vld: nonqueued-receiver-com-spec{data-element=SendLINR_M2SResByte3_AGS2Vld, init-value=SendLINR_M2SResByte3_AGS2VldValue:1}, required-interface=SendLINR_M2SResByte3_AGS2Vld
      SendLINR_AHP_RPM_REQ_PERCT: nonqueued-receiver-com-spec{data-element=SendLINR_AHP_RPM_REQ_PERCT, init-value=SendLINR_AHP_RPM_REQ_PERCTValue:100.3935}, required-interface=SendLINR_AHP_RPM_REQ_PERCT
      SendLINR_AHP_RPM_REQ_PERCT_Vld: nonqueued-receiver-com-spec{data-element=SendLINR_AHP_RPM_REQ_PERCT_Vld, init-value=SendLINR_AHP_RPM_REQ_PERCT_VldValue:1}, required-interface=SendLINR_AHP_RPM_REQ_PERCT_Vld
      SendLINR_AHP_POST_RUN_REQ: nonqueued-receiver-com-spec{data-element=SendLINR_AHP_POST_RUN_REQ, init-value=SendLINR_AHP_POST_RUN_REQValue:7}, required-interface=SendLINR_AHP_POST_RUN_REQ
      SendLINR_AHP_POST_RUN_REQ_Vld: nonqueued-receiver-com-spec{data-element=SendLINR_AHP_POST_RUN_REQ_Vld, init-value=SendLINR_AHP_POST_RUN_REQ_VldValue:1}, required-interface=SendLINR_AHP_POST_RUN_REQ_Vld
      SendLINR_AHP_FL_SAFE_ACTVT: nonqueued-receiver-com-spec{data-element=SendLINR_AHP_FL_SAFE_ACTVT, init-value=SendLINR_AHP_FL_SAFE_ACTVTValue:3}, required-interface=SendLINR_AHP_FL_SAFE_ACTVT
      SendLINR_AHP_FL_SAFE_ACTVT_Vld: nonqueued-receiver-com-spec{data-element=SendLINR_AHP_FL_SAFE_ACTVT_Vld, init-value=SendLINR_AHP_FL_SAFE_ACTVT_VldValue:1}, required-interface=SendLINR_AHP_FL_SAFE_ACTVT_Vld
      SendLINR_BHV_PosRq: nonqueued-receiver-com-spec{data-element=SendLINR_BHV_PosRq, init-value=SendLINR_BHV_PosRqValue:0}, required-interface=SendLINR_BHV_PosRq
      SendLINR_BHV_PosRqVld: nonqueued-receiver-com-spec{data-element=SendLINR_BHV_PosRqVld, init-value=SendLINR_BHV_PosRqVldValue:1}, required-interface=SendLINR_BHV_PosRqVld
      SendLINR_BHV_PosSv: nonqueued-receiver-com-spec{data-element=SendLINR_BHV_PosSv, init-value=SendLINR_BHV_PosSvValue:0}, required-interface=SendLINR_BHV_PosSv
      SendLINR_BHV_PosSvVld: nonqueued-receiver-com-spec{data-element=SendLINR_BHV_PosSvVld, init-value=SendLINR_BHV_PosSvVldValue:1}, required-interface=SendLINR_BHV_PosSvVld
      SendLINR_BHV_CalRq: nonqueued-receiver-com-spec{data-element=SendLINR_BHV_CalRq, init-value=SendLINR_BHV_CalRqValue:0}, required-interface=SendLINR_BHV_CalRq
      SendLINR_BHV_CalRqVld: nonqueued-receiver-com-spec{data-element=SendLINR_BHV_CalRqVld, init-value=SendLINR_BHV_CalRqVldValue:1}, required-interface=SendLINR_BHV_CalRqVld
      SendLINR_CompressorSpdReq: nonqueued-receiver-com-spec{data-element=SendLINR_CompressorSpdReq, init-value=SendLINR_CompressorSpdReqValue:0}, required-interface=SendLINR_CompressorSpdReq
      SendLINR_CompressorSpdReqVld: nonqueued-receiver-com-spec{data-element=SendLINR_CompressorSpdReqVld, init-value=SendLINR_CompressorSpdReqVldValue:1}, required-interface=SendLINR_CompressorSpdReqVld
      SendLINR_CompEnable: nonqueued-receiver-com-spec{data-element=SendLINR_CompEnable, init-value=SendLINR_CompEnableValue:3}, required-interface=SendLINR_CompEnable
      SendLINR_CompEnableVld: nonqueued-receiver-com-spec{data-element=SendLINR_CompEnableVld, init-value=SendLINR_CompEnableVldValue:1}, required-interface=SendLINR_CompEnableVld
      SendLINR_DriveEcohybridLmp: nonqueued-receiver-com-spec{data-element=SendLINR_DriveEcohybridLmp, init-value=SendLINR_DriveEcohybridLmpValue:0}, required-interface=SendLINR_DriveEcohybridLmp
      SendLINR_DriveEcohybridLmpVld: nonqueued-receiver-com-spec{data-element=SendLINR_DriveEcohybridLmpVld, init-value=SendLINR_DriveEcohybridLmpVldValue:1}, required-interface=SendLINR_DriveEcohybridLmpVld
      SendLINR_DriveElectricLmp: nonqueued-receiver-com-spec{data-element=SendLINR_DriveElectricLmp, init-value=SendLINR_DriveElectricLmpValue:0}, required-interface=SendLINR_DriveElectricLmp
      SendLINR_DriveElectricLmpVld: nonqueued-receiver-com-spec{data-element=SendLINR_DriveElectricLmpVld, init-value=SendLINR_DriveElectricLmpVldValue:1}, required-interface=SendLINR_DriveElectricLmpVld
      SendLINR_DriveESaveLmp: nonqueued-receiver-com-spec{data-element=SendLINR_DriveESaveLmp, init-value=SendLINR_DriveESaveLmpValue:0}, required-interface=SendLINR_DriveESaveLmp
      SendLINR_DriveESaveLmpVld: nonqueued-receiver-com-spec{data-element=SendLINR_DriveESaveLmpVld, init-value=SendLINR_DriveESaveLmpVldValue:1}, required-interface=SendLINR_DriveESaveLmpVld
      SendLINR_DriveSportHybridLmp: nonqueued-receiver-com-spec{data-element=SendLINR_DriveSportHybridLmp, init-value=SendLINR_DriveSportHybridLmpValue:0}, required-interface=SendLINR_DriveSportHybridLmp
      SendLINR_DriveSportHybridLmpVld: nonqueued-receiver-com-spec{data-element=SendLINR_DriveSportHybridLmpVld, init-value=SendLINR_DriveSportHybridLmpVldValue:1}, required-interface=SendLINR_DriveSportHybridLmpVld
      SendLINR_PanelIntensitySts: nonqueued-receiver-com-spec{data-element=SendLINR_PanelIntensitySts, init-value=SendLINR_PanelIntensityStsValue:0}, required-interface=SendLINR_PanelIntensitySts
      SendLINR_PanelIntensityStsVld: nonqueued-receiver-com-spec{data-element=SendLINR_PanelIntensityStsVld, init-value=SendLINR_PanelIntensityStsVldValue:1}, required-interface=SendLINR_PanelIntensityStsVld
      SendLINR_DAY_LGT_MD: nonqueued-receiver-com-spec{data-element=SendLINR_DAY_LGT_MD, init-value=SendLINR_DAY_LGT_MDValue:0}, required-interface=SendLINR_DAY_LGT_MD
      SendLINR_DAY_LGT_MD_Vld: nonqueued-receiver-com-spec{data-element=SendLINR_DAY_LGT_MD_Vld, init-value=SendLINR_DAY_LGT_MD_VldValue:1}, required-interface=SendLINR_DAY_LGT_MD_Vld
      SendLINR_PECP_RPM_REQ_PERCT: nonqueued-receiver-com-spec{data-element=SendLINR_PECP_RPM_REQ_PERCT, init-value=SendLINR_PECP_RPM_REQ_PERCTValue:100.3935}, required-interface=SendLINR_PECP_RPM_REQ_PERCT
      SendLINR_PECP_RPM_REQ_PERCT_Vld: nonqueued-receiver-com-spec{data-element=SendLINR_PECP_RPM_REQ_PERCT_Vld, init-value=SendLINR_PECP_RPM_REQ_PERCT_VldValue:1}, required-interface=SendLINR_PECP_RPM_REQ_PERCT_Vld
      SendLINR_PECP_POST_RUN_REQ: nonqueued-receiver-com-spec{data-element=SendLINR_PECP_POST_RUN_REQ, init-value=SendLINR_PECP_POST_RUN_REQValue:7}, required-interface=SendLINR_PECP_POST_RUN_REQ
      SendLINR_PECP_POST_RUN_REQ_Vld: nonqueued-receiver-com-spec{data-element=SendLINR_PECP_POST_RUN_REQ_Vld, init-value=SendLINR_PECP_POST_RUN_REQ_VldValue:1}, required-interface=SendLINR_PECP_POST_RUN_REQ_Vld
      SendLINR_PECP_FL_SAFE_ACTVT: nonqueued-receiver-com-spec{data-element=SendLINR_PECP_FL_SAFE_ACTVT, init-value=SendLINR_PECP_FL_SAFE_ACTVTValue:3}, required-interface=SendLINR_PECP_FL_SAFE_ACTVT
      SendLINR_PECP_FL_SAFE_ACTVT_Vld: nonqueued-receiver-com-spec{data-element=SendLINR_PECP_FL_SAFE_ACTVT_Vld, init-value=SendLINR_PECP_FL_SAFE_ACTVT_VldValue:1}, required-interface=SendLINR_PECP_FL_SAFE_ACTVT_Vld
      SendLINR_PwrPanel_LED_A_Command: nonqueued-receiver-com-spec{data-element=SendLINR_PwrPanel_LED_A_Command, init-value=SendLINR_PwrPanel_LED_A_CommandValue:0}, required-interface=SendLINR_PwrPanel_LED_A_Command
      SendLINR_PwrPanel_LED_A_CommandVld: nonqueued-receiver-com-spec{data-element=SendLINR_PwrPanel_LED_A_CommandVld, init-value=SendLINR_PwrPanel_LED_A_CommandVldValue:1}, required-interface=SendLINR_PwrPanel_LED_A_CommandVld
      SendLINR_PwrPanel_LED_B_Command: nonqueued-receiver-com-spec{data-element=SendLINR_PwrPanel_LED_B_Command, init-value=SendLINR_PwrPanel_LED_B_CommandValue:0}, required-interface=SendLINR_PwrPanel_LED_B_Command
      SendLINR_PwrPanel_LED_B_CommandVld: nonqueued-receiver-com-spec{data-element=SendLINR_PwrPanel_LED_B_CommandVld, init-value=SendLINR_PwrPanel_LED_B_CommandVldValue:1}, required-interface=SendLINR_PwrPanel_LED_B_CommandVld
      SendLINR_DAY_LGT_MD_PowerPanel: nonqueued-receiver-com-spec{data-element=SendLINR_DAY_LGT_MD_PowerPanel, init-value=SendLINR_DAY_LGT_MD_PowerPanelValue:0}, required-interface=SendLINR_DAY_LGT_MD_PowerPanel
      SendLINR_DAY_LGT_MD_PowerPanelVld: nonqueued-receiver-com-spec{data-element=SendLINR_DAY_LGT_MD_PowerPanelVld, init-value=SendLINR_DAY_LGT_MD_PowerPanelVldValue:1}, required-interface=SendLINR_DAY_LGT_MD_PowerPanelVld
      SendLINR_AGS_PosRq: required-interface=SendLINR_AGS_PosRq
      SendLINR_AGS_CalRq: required-interface=SendLINR_AGS_CalRq
      SendLINR_AGS_BoostRq: required-interface=SendLINR_AGS_BoostRq
      SendLINR_M2SRes2Bit: required-interface=SendLINR_M2SRes2Bit
      SendLINR_M2SResByte{1..3}: required-interface=SendLINR_M2SResByte{1..3}
      SendLINR_CEXV_PosRq: required-interface=SendLINR_CEXV_PosRq
      SendLINR_CEXV_CalCmd: required-interface=SendLINR_CEXV_CalCmd
      SendLINR_CPIM_SET_IND{1..5}: required-interface=SendLINR_CPIM_SET_IND{1..5}
      SendLINR_CPIM_Blink_Rate: required-interface=SendLINR_CPIM_Blink_Rate
      SendLINR_CPIM_IND_Color: required-interface=SendLINR_CPIM_IND_Color
      SendLINR_ChrgPortLock_Cmd: required-interface=SendLINR_ChrgPortLock_Cmd
      SendLINR_Set_Icon1_cmd: required-interface=SendLINR_Set_Icon1_cmd
      SendLINR_Set_Icon2_cmd: required-interface=SendLINR_Set_Icon2_cmd
      SendLINR_DAY_LGT_MD_CPIM: required-interface=SendLINR_DAY_LGT_MD_CPIM
      SendLINR_Backlight_Cmd: required-interface=SendLINR_Backlight_Cmd
      SendLINR_HvWtrHeatrPwrCnsAllwd: required-interface=SendLINR_HvWtrHeatrPwrCnsAllwd
      SendLINR_HvWtrHeatrWtrTDes: required-interface=SendLINR_HvWtrHeatrWtrTDes
      SendLINR_HvCooltHeatrEnad: required-interface=SendLINR_HvCooltHeatrEnad
      SendLINR_HVH_OverheatUnlock: required-interface=SendLINR_HVH_OverheatUnlock
      SendLINR_EOPB_RPM_COM: required-interface=SendLINR_EOPB_RPM_COM
      SendLINR_EOPB_POST_RUN_COM: required-interface=SendLINR_EOPB_POST_RUN_COM
      SendLINR_HTLBV_PosRq: required-interface=SendLINR_HTLBV_PosRq
      SendLINR_HTLBV_PosSv: required-interface=SendLINR_HTLBV_PosSv
      SendLINR_HTLBV_CalRq: required-interface=SendLINR_HTLBV_CalRq
      SendLINR_PECP2_RPM_REQ_PERCT: required-interface=SendLINR_PECP2_RPM_REQ_PERCT
      SendLINR_PECP2_POST_RUN_REQ: required-interface=SendLINR_PECP2_POST_RUN_REQ
      SendLINR_PECP2_FL_SAFE_ACTVT: required-interface=SendLINR_PECP2_FL_SAFE_ACTVT
      SendLINR_PowerPanel2_LED_A_Cmnd: required-interface=SendLINR_PowerPanel2_LED_A_Cmnd
      SendLINR_PowerPanel2_LED_B_Cmnd: required-interface=SendLINR_PowerPanel2_LED_B_Cmnd
      SendLINR_DAY_LGT_MD_PowerPanel2: required-interface=SendLINR_DAY_LGT_MD_PowerPanel2
      SignalLINR_AAD_RdyForSleep: nonqueued-receiver-com-spec{data-element=SignalLINR_AAD_RdyForSleep, init-value=SignalLINR_AAD_RdyForSleepValue:0}, required-interface=SignalLINR_AAD_RdyForSleep
      SignalLINR_BCP_RdyForSleep: nonqueued-receiver-com-spec{data-element=SignalLINR_BCP_RdyForSleep, init-value=SignalLINR_BCP_RdyForSleepValue:0}, required-interface=SignalLINR_BCP_RdyForSleep
      SignalLINR_CPV_RdyForSleep: nonqueued-receiver-com-spec{data-element=SignalLINR_CPV_RdyForSleep, init-value=SignalLINR_CPV_RdyForSleepValue:0}, required-interface=SignalLINR_CPV_RdyForSleep
      SignalLINR_EAH_RdyForSleep: nonqueued-receiver-com-spec{data-element=SignalLINR_EAH_RdyForSleep, init-value=SignalLINR_EAH_RdyForSleepValue:0}, required-interface=SignalLINR_EAH_RdyForSleep
      SignalLINR_EEXV_RdyForSleep: nonqueued-receiver-com-spec{data-element=SignalLINR_EEXV_RdyForSleep, init-value=SignalLINR_EEXV_RdyForSleepValue:0}, required-interface=SignalLINR_EEXV_RdyForSleep
      SignalLINR_EOPA_RdyForSleep: nonqueued-receiver-com-spec{data-element=SignalLINR_EOPA_RdyForSleep, init-value=SignalLINR_EOPA_RdyForSleepValue:0}, required-interface=SignalLINR_EOPA_RdyForSleep
      SignalLINR_LTRBV_RdyForSleep: nonqueued-receiver-com-spec{data-element=SignalLINR_LTRBV_RdyForSleep, init-value=SignalLINR_LTRBV_RdyForSleepValue:0}, required-interface=SignalLINR_LTRBV_RdyForSleep
      SignalLINR_AGS2_RdyForSleep: nonqueued-receiver-com-spec{data-element=SignalLINR_AGS2_RdyForSleep, init-value=SignalLINR_AGS2_RdyForSleepValue:0}, required-interface=SignalLINR_AGS2_RdyForSleep
      SignalLINR_AHP_RdyForSleep: nonqueued-receiver-com-spec{data-element=SignalLINR_AHP_RdyForSleep, init-value=SignalLINR_AHP_RdyForSleepValue:0}, required-interface=SignalLINR_AHP_RdyForSleep
      SignalLINR_BHV_RdyForSleep: nonqueued-receiver-com-spec{data-element=SignalLINR_BHV_RdyForSleep, init-value=SignalLINR_BHV_RdyForSleepValue:0}, required-interface=SignalLINR_BHV_RdyForSleep
      SignalLINR_EAC2_RdyForSleep: nonqueued-receiver-com-spec{data-element=SignalLINR_EAC2_RdyForSleep, init-value=SignalLINR_EAC2_RdyForSleepValue:0}, required-interface=SignalLINR_EAC2_RdyForSleep
      SignalLINR_ESBM_RdyForSleep: nonqueued-receiver-com-spec{data-element=SignalLINR_ESBM_RdyForSleep, init-value=SignalLINR_ESBM_RdyForSleepValue:0}, required-interface=SignalLINR_ESBM_RdyForSleep
      SignalLINR_OEXV_RdyForSleep: nonqueued-receiver-com-spec{data-element=SignalLINR_OEXV_RdyForSleep, init-value=SignalLINR_OEXV_RdyForSleepValue:0}, required-interface=SignalLINR_OEXV_RdyForSleep
      SignalLINR_PECP_RdyForSleep: nonqueued-receiver-com-spec{data-element=SignalLINR_PECP_RdyForSleep, init-value=SignalLINR_PECP_RdyForSleepValue:0}, required-interface=SignalLINR_PECP_RdyForSleep
      SignalLINR_SPP_RdyForSleep: nonqueued-receiver-com-spec{data-element=SignalLINR_SPP_RdyForSleep, init-value=SignalLINR_SPP_RdyForSleepValue:0}, required-interface=SignalLINR_SPP_RdyForSleep
      SignalLINR_AGS_RdyForSleep: nonqueued-receiver-com-spec{data-element=SignalLINR_AGS_RdyForSleep, init-value=SignalLINR_AGS_RdyForSleepValue:0}, required-interface=SignalLINR_AGS_RdyForSleep
      SignalLINR_CEXV_RdyForSleep: nonqueued-receiver-com-spec{data-element=SignalLINR_CEXV_RdyForSleep, init-value=SignalLINR_CEXV_RdyForSleepValue:0}, required-interface=SignalLINR_CEXV_RdyForSleep
      SignalLINR_CPIM_RdyForSleep: nonqueued-receiver-com-spec{data-element=SignalLINR_CPIM_RdyForSleep, init-value=SignalLINR_CPIM_RdyForSleepValue:0}, required-interface=SignalLINR_CPIM_RdyForSleep
      SignalLINR_ECH_RdyForSleep: nonqueued-receiver-com-spec{data-element=SignalLINR_ECH_RdyForSleep, init-value=SignalLINR_ECH_RdyForSleepValue:0}, required-interface=SignalLINR_ECH_RdyForSleep
      SignalLINR_EOPB_RdyForSleep: nonqueued-receiver-com-spec{data-element=SignalLINR_EOPB_RdyForSleep, init-value=SignalLINR_EOPB_RdyForSleepValue:0}, required-interface=SignalLINR_EOPB_RdyForSleep
      SignalLINR_HTLBV_RdyForSleep: nonqueued-receiver-com-spec{data-element=SignalLINR_HTLBV_RdyForSleep, init-value=SignalLINR_HTLBV_RdyForSleepValue:0}, required-interface=SignalLINR_HTLBV_RdyForSleep
      SignalLINR_PECP2_RdyForSleep: nonqueued-receiver-com-spec{data-element=SignalLINR_PECP2_RdyForSleep, init-value=SignalLINR_PECP2_RdyForSleepValue:0}, required-interface=SignalLINR_PECP2_RdyForSleep
      SignalLINR_SPP2_RdyForSleep: nonqueued-receiver-com-spec{data-element=SignalLINR_SPP2_RdyForSleep, init-value=SignalLINR_SPP2_RdyForSleepValue:0}, required-interface=SignalLINR_SPP2_RdyForSleep
      KeLINR_y_LIN1SwtSchdTbl: parameter-require-com-spec{init-value=Value:0, parameter=KeLINR_y_LIN1SwtSchdTbl}, required-interface=KeLINR_y_LIN1SwtSchdTbl
      KeCFGR_b_AAD_Equid: parameter-require-com-spec{init-value=Value:0, parameter=KeCFGR_b_AAD_Equid}, required-interface=KeCFGR_b_AAD_Equid
      KeCFGR_b_BCP_Equid: parameter-require-com-spec{init-value=Value:0, parameter=KeCFGR_b_BCP_Equid}, required-interface=KeCFGR_b_BCP_Equid
      KeCFGR_b_CPV_Equid: parameter-require-com-spec{init-value=Value:0, parameter=KeCFGR_b_CPV_Equid}, required-interface=KeCFGR_b_CPV_Equid
      KeCFGR_b_EAH_Equid: parameter-require-com-spec{init-value=Value:0, parameter=KeCFGR_b_EAH_Equid}, required-interface=KeCFGR_b_EAH_Equid
      KeCFGR_b_EEXV_Equid: parameter-require-com-spec{init-value=Value:0, parameter=KeCFGR_b_EEXV_Equid}, required-interface=KeCFGR_b_EEXV_Equid
      KeCFGR_b_EOPA_Equid: parameter-require-com-spec{init-value=Value:0, parameter=KeCFGR_b_EOPA_Equid}, required-interface=KeCFGR_b_EOPA_Equid
      KeCFGR_b_LTRBV_Equid: parameter-require-com-spec{init-value=Value:0, parameter=KeCFGR_b_LTRBV_Equid}, required-interface=KeCFGR_b_LTRBV_Equid
      KeLINR_y_LIN2SwtSchdTbl: parameter-require-com-spec{init-value=Value:0, parameter=KeLINR_y_LIN2SwtSchdTbl}, required-interface=KeLINR_y_LIN2SwtSchdTbl
      KeLINR_y_LIN3SwtSchdTbl: parameter-require-com-spec{init-value=Value:0, parameter=KeLINR_y_LIN3SwtSchdTbl}, required-interface=KeLINR_y_LIN3SwtSchdTbl
      KeCFGR_b_AGS_Equid: parameter-require-com-spec{init-value=Value:0, parameter=KeCFGR_b_AGS_Equid}, required-interface=KeCFGR_b_AGS_Equid
      KeCFGR_b_CEXV_Equid: parameter-require-com-spec{init-value=Value:0, parameter=KeCFGR_b_CEXV_Equid}, required-interface=KeCFGR_b_CEXV_Equid
      KeCFGR_b_CPIM_Equid: parameter-require-com-spec{init-value=Value:0, parameter=KeCFGR_b_CPIM_Equid}, required-interface=KeCFGR_b_CPIM_Equid
      KeCFGR_b_ECH_Equid: parameter-require-com-spec{init-value=Value:0, parameter=KeCFGR_b_ECH_Equid}, required-interface=KeCFGR_b_ECH_Equid
      KeCFGR_b_EOPB_Equid: parameter-require-com-spec{init-value=Value:0, parameter=KeCFGR_b_EOPB_Equid}, required-interface=KeCFGR_b_EOPB_Equid
      KeCFGR_b_HTLBV_Equid: parameter-require-com-spec{init-value=Value:0, parameter=KeCFGR_b_HTLBV_Equid}, required-interface=KeCFGR_b_HTLBV_Equid
      KeCFGR_b_PECP2_Equid: parameter-require-com-spec{init-value=Value:0, parameter=KeCFGR_b_PECP2_Equid}, required-interface=KeCFGR_b_PECP2_Equid
      KeCFGR_b_SPP2_Equid: parameter-require-com-spec{init-value=Value:0, parameter=KeCFGR_b_SPP2_Equid}, required-interface=KeCFGR_b_SPP2_Equid
      KeCFGR_b_AGS2_Equid: parameter-require-com-spec{init-value=Value:0, parameter=KeCFGR_b_AGS2_Equid}, required-interface=KeCFGR_b_AGS2_Equid
      KeCFGR_b_AHP_Equid: parameter-require-com-spec{init-value=Value:0, parameter=KeCFGR_b_AHP_Equid}, required-interface=KeCFGR_b_AHP_Equid
      KeCFGR_b_BHV_Equid: parameter-require-com-spec{init-value=Value:0, parameter=KeCFGR_b_BHV_Equid}, required-interface=KeCFGR_b_BHV_Equid
      KeCFGR_b_EAC2_Equid: required-interface=KeCFGR_b_EAC2_Equid
      KeCFGR_b_ESBM_Equid: parameter-require-com-spec{init-value=Value:0, parameter=KeCFGR_b_ESBM_Equid}, required-interface=KeCFGR_b_ESBM_Equid
      KeCFGR_b_OEXV_Equid: parameter-require-com-spec{init-value=Value:0, parameter=KeCFGR_b_OEXV_Equid}, required-interface=KeCFGR_b_OEXV_Equid
      KeCFGR_b_PECP_Equid: parameter-require-com-spec{init-value=Value:0, parameter=KeCFGR_b_PECP_Equid}, required-interface=KeCFGR_b_PECP_Equid
      KeCFGR_b_SPP_Equid: parameter-require-com-spec{init-value=Value:0, parameter=KeCFGR_b_SPP_Equid}, required-interface=KeCFGR_b_SPP_Equid
      PP_MS_LinSMComMod1: required-interface=MSI_LinSMComMod
      GetRteMode1: required-interface=IFRteMode
      PP_MS_LinSMComMod2: required-interface=MSI_LinSMComMod
      GetRteMode2: required-interface=IFRteMode
    provide port VeLINR_b_LIN1_RequestsPostRun: provided-interface=VeSPLR_b_PostRunRqrdSt
    require port PP_MS_LinSMComMod: required-interface=MSI_LinSMComMod
    require port KeCFGR_b_LIN1_Equid: required-interface=KeCFGR_b_LIN1_Equid
    require port GetRteMode: required-interface=IFRteMode
    provide port VeLINR_d_LIN_SlavePrsntSts_LIN1: provided-interface=VeLINR_d_LIN_SlavePrsntSts_LIN1
    provide port VeLINR_b_LIN2_RequestsPostRun: provided-interface=VeSPLR_b_PostRunRqrdSt
    require port KeCFGR_b_LIN2_Equid: required-interface=KeCFGR_b_LIN2_Equid
    provide port VeLINR_b_LIN3_RequestsPostRun: provided-interface=VeSPLR_b_PostRunRqrdSt
    require port KeCFGR_b_LIN3_Equid: required-interface=KeCFGR_b_LIN3_Equid
    151 x provide port:
      ApplLinComAbLin2EquidMN: mode-switch-sender-com-spec{mode-group=MDGP_MSI_Lin2Equid, queue-length=1}, provided-interface=MSI_Lin2Equid
      ApplLinComAbLin3EquidMN: mode-switch-sender-com-spec{mode-group=MDGP_MSI_Lin3Equid, queue-length=1}, provided-interface=MSI_Lin3Equid
      ApplLinComAbLin1EquidMN: mode-switch-sender-com-spec{mode-group=MDGP_MSI_Lin1Equid, queue-length=1}, provided-interface=MSI_Lin1Equid
      VeLINR_d_LIN_SlavePrsntSts_LIN2: provided-interface=VeLINR_d_LIN_SlavePrsntSts_LIN2
      VeLINR_d_LIN_SlavePrsntSts_LIN3: provided-interface=VeLINR_d_LIN_SlavePrsntSts_LIN3
      VeLINR_e_AAD_CurrPos: nonqueued-sender-com-spec{data-element=VeLINR_e_AAD_CurrPos, init-value=VeLINR_e_AAD_CurrPosValue:15}, provided-interface=VeLINR_e_AAD_CurrPos
      VeLINR_b_AAD_CurrPosTO: nonqueued-sender-com-spec{data-element=VeLINR_b_AAD_CurrPosTO, init-value=VeLINR_b_AAD_CurrPosTOValue:0}, provided-interface=VeLINR_b_AAD_CurrPosTO
      VeLINR_b_AAD_CalStat: nonqueued-sender-com-spec{data-element=VeLINR_b_AAD_CalStat, init-value=VeLINR_b_AAD_CalStatValue:0}, provided-interface=VeLINR_b_AAD_CalStat
      VeLINR_b_AAD_CalStatTO: nonqueued-sender-com-spec{data-element=VeLINR_b_AAD_CalStatTO, init-value=VeLINR_b_AAD_CalStatTOValue:0}, provided-interface=VeLINR_b_AAD_CalStatTO
      VeLINR_b_AAD_CalActv: nonqueued-sender-com-spec{data-element=VeLINR_b_AAD_CalActv, init-value=VeLINR_b_AAD_CalActvValue:0}, provided-interface=VeLINR_b_AAD_CalActv
      VeLINR_b_AAD_CalActvTO: nonqueued-sender-com-spec{data-element=VeLINR_b_AAD_CalActvTO, init-value=VeLINR_b_AAD_CalActvTOValue:0}, provided-interface=VeLINR_b_AAD_CalActvTO
      VeLINR_b_AAD_ErrUnVolt: nonqueued-sender-com-spec{data-element=VeLINR_b_AAD_ErrUnVolt, init-value=VeLINR_b_AAD_ErrUnVoltValue:0}, provided-interface=VeLINR_b_AAD_ErrUnVolt
      VeLINR_b_AAD_ErrUnVoltTO: nonqueued-sender-com-spec{data-element=VeLINR_b_AAD_ErrUnVoltTO, init-value=VeLINR_b_AAD_ErrUnVoltTOValue:0}, provided-interface=VeLINR_b_AAD_ErrUnVoltTO
      VeLINR_b_AAD_ErrOvrVolt: nonqueued-sender-com-spec{data-element=VeLINR_b_AAD_ErrOvrVolt, init-value=VeLINR_b_AAD_ErrOvrVoltValue:0}, provided-interface=VeLINR_b_AAD_ErrOvrVolt
      VeLINR_b_AAD_ErrOvrVoltTO: nonqueued-sender-com-spec{data-element=VeLINR_b_AAD_ErrOvrVoltTO, init-value=VeLINR_b_AAD_ErrOvrVoltTOValue:0}, provided-interface=VeLINR_b_AAD_ErrOvrVoltTO
      VeLINR_b_AAD_ErrOvrTemp: nonqueued-sender-com-spec{data-element=VeLINR_b_AAD_ErrOvrTemp, init-value=VeLINR_b_AAD_ErrOvrTempValue:0}, provided-interface=VeLINR_b_AAD_ErrOvrTemp
      VeLINR_b_AAD_ErrOvrTempTO: nonqueued-sender-com-spec{data-element=VeLINR_b_AAD_ErrOvrTempTO, init-value=VeLINR_b_AAD_ErrOvrTempTOValue:0}, provided-interface=VeLINR_b_AAD_ErrOvrTempTO
      VeLINR_b_AAD_ErrMechStuck: nonqueued-sender-com-spec{data-element=VeLINR_b_AAD_ErrMechStuck, init-value=VeLINR_b_AAD_ErrMechStuckValue:0}, provided-interface=VeLINR_b_AAD_ErrMechStuck
      VeLINR_b_AAD_ErrMechStuckTO: nonqueued-sender-com-spec{data-element=VeLINR_b_AAD_ErrMechStuckTO, init-value=VeLINR_b_AAD_ErrMechStuckTOValue:0}, provided-interface=VeLINR_b_AAD_ErrMechStuckTO
      VeLINR_b_AAD_ErrMechBreak: nonqueued-sender-com-spec{data-element=VeLINR_b_AAD_ErrMechBreak, init-value=VeLINR_b_AAD_ErrMechBreakValue:0}, provided-interface=VeLINR_b_AAD_ErrMechBreak
      VeLINR_b_AAD_ErrMechBreakTO: nonqueued-sender-com-spec{data-element=VeLINR_b_AAD_ErrMechBreakTO, init-value=VeLINR_b_AAD_ErrMechBreakTOValue:0}, provided-interface=VeLINR_b_AAD_ErrMechBreakTO
      VeLINR_b_RsErr_AAD: nonqueued-sender-com-spec{data-element=VeLINR_b_RsErr_AAD, init-value=VeLINR_b_RsErr_AADValue:0}, provided-interface=VeLINR_b_RsErr_AAD
      VeLINR_b_RsErr_AAD_TO: nonqueued-sender-com-spec{data-element=VeLINR_b_RsErr_AAD_TO, init-value=VeLINR_b_RsErr_AAD_TOValue:0}, provided-interface=VeLINR_b_RsErr_AAD_TO
      VeLINR_Pct_BCP_RPM_TARGET: nonqueued-sender-com-spec{data-element=VeLINR_Pct_BCP_RPM_TARGET, init-value=VeLINR_Pct_BCP_RPM_TARGETValue:100.3935}, provided-interface=VeLINR_Pct_BCP_RPM_TARGET
      VeLINR_b_BCP_RPM_TARGET_TO: nonqueued-sender-com-spec{data-element=VeLINR_b_BCP_RPM_TARGET_TO, init-value=VeLINR_b_BCP_RPM_TARGET_TOValue:0}, provided-interface=VeLINR_b_BCP_RPM_TARGET_TO
      VeLINR_Pct_BCP_RPM_ACTUAL: nonqueued-sender-com-spec{data-element=VeLINR_Pct_BCP_RPM_ACTUAL, init-value=VeLINR_Pct_BCP_RPM_ACTUALValue:100.3935}, provided-interface=VeLINR_Pct_BCP_RPM_ACTUAL
      VeLINR_b_BCP_RPM_ACTUAL_TO: nonqueued-sender-com-spec{data-element=VeLINR_b_BCP_RPM_ACTUAL_TO, init-value=VeLINR_b_BCP_RPM_ACTUAL_TOValue:0}, provided-interface=VeLINR_b_BCP_RPM_ACTUAL_TO
      VeLINR_U_BCP_VLTG: nonqueued-sender-com-spec{data-element=VeLINR_U_BCP_VLTG, init-value=VeLINR_U_BCP_VLTGValue:25.5}, provided-interface=VeLINR_U_BCP_VLTG
      VeLINR_b_BCP_VLTG_TO: nonqueued-sender-com-spec{data-element=VeLINR_b_BCP_VLTG_TO, init-value=VeLINR_b_BCP_VLTG_TOValue:0}, provided-interface=VeLINR_b_BCP_VLTG_TO
      VeLINR_T_BCP_TEMP: nonqueued-sender-com-spec{data-element=VeLINR_T_BCP_TEMP, init-value=VeLINR_T_BCP_TEMPValue:205}, provided-interface=VeLINR_T_BCP_TEMP
      VeLINR_b_BCP_TEMP_TO: nonqueued-sender-com-spec{data-element=VeLINR_b_BCP_TEMP_TO, init-value=VeLINR_b_BCP_TEMP_TOValue:0}, provided-interface=VeLINR_b_BCP_TEMP_TO
      VeLINR_I_BCP_CURR: nonqueued-sender-com-spec{data-element=VeLINR_I_BCP_CURR, init-value=VeLINR_I_BCP_CURRValue:51}, provided-interface=VeLINR_I_BCP_CURR
      VeLINR_b_BCP_CURR_TO: nonqueued-sender-com-spec{data-element=VeLINR_b_BCP_CURR_TO, init-value=VeLINR_b_BCP_CURR_TOValue:0}, provided-interface=VeLINR_b_BCP_CURR_TO
      VeLINR_e_BCP_FL_SAFE_ACTVTD: nonqueued-sender-com-spec{data-element=VeLINR_e_BCP_FL_SAFE_ACTVTD, init-value=VeLINR_e_BCP_FL_SAFE_ACTVTDValue:3}, provided-interface=VeLINR_e_BCP_FL_SAFE_ACTVTD
      VeLINR_b_BCP_FL_SAFE_ACTVTD_TO: nonqueued-sender-com-spec{data-element=VeLINR_b_BCP_FL_SAFE_ACTVTD_TO, init-value=VeLINR_b_BCP_FL_SAFE_ACTVTD_TOValue:0}, provided-interface=VeLINR_b_BCP_FL_SAFE_ACTVTD_TO
      VeLINR_e_BCP_LMP_HM_AN_ON: nonqueued-sender-com-spec{data-element=VeLINR_e_BCP_LMP_HM_AN_ON, init-value=VeLINR_e_BCP_LMP_HM_AN_ONValue:3}, provided-interface=VeLINR_e_BCP_LMP_HM_AN_ON
      VeLINR_b_BCP_LMP_HM_AN_ON_TO: nonqueued-sender-com-spec{data-element=VeLINR_b_BCP_LMP_HM_AN_ON_TO, init-value=VeLINR_b_BCP_LMP_HM_AN_ON_TOValue:0}, provided-interface=VeLINR_b_BCP_LMP_HM_AN_ON_TO
      VeLINR_e_BCP_AIR_PRE_ERR: nonqueued-sender-com-spec{data-element=VeLINR_e_BCP_AIR_PRE_ERR, init-value=VeLINR_e_BCP_AIR_PRE_ERRValue:3}, provided-interface=VeLINR_e_BCP_AIR_PRE_ERR
      VeLINR_b_BCP_AIR_PRE_ERR_TO: nonqueued-sender-com-spec{data-element=VeLINR_b_BCP_AIR_PRE_ERR_TO, init-value=VeLINR_b_BCP_AIR_PRE_ERR_TOValue:0}, provided-interface=VeLINR_b_BCP_AIR_PRE_ERR_TO
      VeLINR_e_BCP_OVR_TMP_ERR: nonqueued-sender-com-spec{data-element=VeLINR_e_BCP_OVR_TMP_ERR, init-value=VeLINR_e_BCP_OVR_TMP_ERRValue:3}, provided-interface=VeLINR_e_BCP_OVR_TMP_ERR
      VeLINR_b_BCP_OVR_TMP_ERR_TO: nonqueued-sender-com-spec{data-element=VeLINR_b_BCP_OVR_TMP_ERR_TO, init-value=VeLINR_b_BCP_OVR_TMP_ERR_TOValue:0}, provided-interface=VeLINR_b_BCP_OVR_TMP_ERR_TO
      VeLINR_e_BCP_OVR_CUR_ERR: nonqueued-sender-com-spec{data-element=VeLINR_e_BCP_OVR_CUR_ERR, init-value=VeLINR_e_BCP_OVR_CUR_ERRValue:3}, provided-interface=VeLINR_e_BCP_OVR_CUR_ERR
      VeLINR_b_BCP_OVR_CUR_ERR_TO: nonqueued-sender-com-spec{data-element=VeLINR_b_BCP_OVR_CUR_ERR_TO, init-value=VeLINR_b_BCP_OVR_CUR_ERR_TOValue:0}, provided-interface=VeLINR_b_BCP_OVR_CUR_ERR_TO
      VeLINR_e_BCP_DR_RN_ERR: nonqueued-sender-com-spec{data-element=VeLINR_e_BCP_DR_RN_ERR, init-value=VeLINR_e_BCP_DR_RN_ERRValue:3}, provided-interface=VeLINR_e_BCP_DR_RN_ERR
      VeLINR_b_BCP_DR_RN_ERR_TO: nonqueued-sender-com-spec{data-element=VeLINR_b_BCP_DR_RN_ERR_TO, init-value=VeLINR_b_BCP_DR_RN_ERR_TOValue:0}, provided-interface=VeLINR_b_BCP_DR_RN_ERR_TO
      VeLINR_e_BCP_VLTG_ERR: nonqueued-sender-com-spec{data-element=VeLINR_e_BCP_VLTG_ERR, init-value=VeLINR_e_BCP_VLTG_ERRValue:3}, provided-interface=VeLINR_e_BCP_VLTG_ERR
      VeLINR_b_BCP_VLTG_ERR_TO: nonqueued-sender-com-spec{data-element=VeLINR_b_BCP_VLTG_ERR_TO, init-value=VeLINR_b_BCP_VLTG_ERR_TOValue:0}, provided-interface=VeLINR_b_BCP_VLTG_ERR_TO
      VeLINR_e_BCP_DBLK_ACTV: nonqueued-sender-com-spec{data-element=VeLINR_e_BCP_DBLK_ACTV, init-value=VeLINR_e_BCP_DBLK_ACTVValue:3}, provided-interface=VeLINR_e_BCP_DBLK_ACTV
      VeLINR_b_BCP_DBLK_ACTV_TO: nonqueued-sender-com-spec{data-element=VeLINR_b_BCP_DBLK_ACTV_TO, init-value=VeLINR_b_BCP_DBLK_ACTV_TOValue:0}, provided-interface=VeLINR_b_BCP_DBLK_ACTV_TO
      VeLINR_e_BCP_MONTRNG_RPM: nonqueued-sender-com-spec{data-element=VeLINR_e_BCP_MONTRNG_RPM, init-value=VeLINR_e_BCP_MONTRNG_RPMValue:3}, provided-interface=VeLINR_e_BCP_MONTRNG_RPM
      VeLINR_b_BCP_MONTRNG_RPM_TO: nonqueued-sender-com-spec{data-element=VeLINR_b_BCP_MONTRNG_RPM_TO, init-value=VeLINR_b_BCP_MONTRNG_RPM_TOValue:0}, provided-interface=VeLINR_b_BCP_MONTRNG_RPM_TO
      VeLINR_e_BCP_NODE_ERR: nonqueued-sender-com-spec{data-element=VeLINR_e_BCP_NODE_ERR, init-value=VeLINR_e_BCP_NODE_ERRValue:3}, provided-interface=VeLINR_e_BCP_NODE_ERR
      VeLINR_b_BCP_NODE_ERR_TO: nonqueued-sender-com-spec{data-element=VeLINR_b_BCP_NODE_ERR_TO, init-value=VeLINR_b_BCP_NODE_ERR_TOValue:0}, provided-interface=VeLINR_b_BCP_NODE_ERR_TO
      VeLINR_e_BCP_POST_RUN_STAT: nonqueued-sender-com-spec{data-element=VeLINR_e_BCP_POST_RUN_STAT, init-value=VeLINR_e_BCP_POST_RUN_STATValue:7}, provided-interface=VeLINR_e_BCP_POST_RUN_STAT
      VeLINR_b_BCP_POST_RUN_STAT_TO: nonqueued-sender-com-spec{data-element=VeLINR_b_BCP_POST_RUN_STAT_TO, init-value=VeLINR_b_BCP_POST_RUN_STAT_TOValue:0}, provided-interface=VeLINR_b_BCP_POST_RUN_STAT_TO
      VeLINR_b_RsErr_BCP_PUMP: nonqueued-sender-com-spec{data-element=VeLINR_b_RsErr_BCP_PUMP, init-value=VeLINR_b_RsErr_BCP_PUMPValue:0}, provided-interface=VeLINR_b_RsErr_BCP_PUMP
      VeLINR_b_RsErr_BCP_PUMP_TO: nonqueued-sender-com-spec{data-element=VeLINR_b_RsErr_BCP_PUMP_TO, init-value=VeLINR_b_RsErr_BCP_PUMP_TOValue:0}, provided-interface=VeLINR_b_RsErr_BCP_PUMP_TO
      VeLINR_y_BCP_VERSION: nonqueued-sender-com-spec{data-element=VeLINR_y_BCP_VERSION, init-value=VeLINR_y_BCP_VERSIONValue:255}, provided-interface=VeLINR_y_BCP_VERSION
      VeLINR_b_BCP_VERSION_TO: nonqueued-sender-com-spec{data-element=VeLINR_b_BCP_VERSION_TO, init-value=VeLINR_b_BCP_VERSION_TOValue:0}, provided-interface=VeLINR_b_BCP_VERSION_TO
      VeLINR_e_BCP_SUPPLIER: nonqueued-sender-com-spec{data-element=VeLINR_e_BCP_SUPPLIER, init-value=VeLINR_e_BCP_SUPPLIERValue:0}, provided-interface=VeLINR_e_BCP_SUPPLIER
      VeLINR_b_BCP_SUPPLIER_TO: nonqueued-sender-com-spec{data-element=VeLINR_b_BCP_SUPPLIER_TO, init-value=VeLINR_b_BCP_SUPPLIER_TOValue:0}, provided-interface=VeLINR_b_BCP_SUPPLIER_TO
      VeLINR_Pct_CPV_PosAct: nonqueued-sender-com-spec{data-element=VeLINR_Pct_CPV_PosAct, init-value=VeLINR_Pct_CPV_PosActValue:0}, provided-interface=VeLINR_Pct_CPV_PosAct
      VeLINR_b_CPV_PosActTO: nonqueued-sender-com-spec{data-element=VeLINR_b_CPV_PosActTO, init-value=VeLINR_b_CPV_PosActTOValue:0}, provided-interface=VeLINR_b_CPV_PosActTO
      VeLINR_e_CPV_ERR: nonqueued-sender-com-spec{data-element=VeLINR_e_CPV_ERR, init-value=VeLINR_e_CPV_ERRValue:0}, provided-interface=VeLINR_e_CPV_ERR
      VeLINR_b_CPV_ERR_TO: nonqueued-sender-com-spec{data-element=VeLINR_b_CPV_ERR_TO, init-value=VeLINR_b_CPV_ERR_TOValue:0}, provided-interface=VeLINR_b_CPV_ERR_TO
      VeLINR_e_CPV_Sts: nonqueued-sender-com-spec{data-element=VeLINR_e_CPV_Sts, init-value=VeLINR_e_CPV_StsValue:0}, provided-interface=VeLINR_e_CPV_Sts
      VeLINR_b_CPV_StsTO: nonqueued-sender-com-spec{data-element=VeLINR_b_CPV_StsTO, init-value=VeLINR_b_CPV_StsTOValue:0}, provided-interface=VeLINR_b_CPV_StsTO
      VeLINR_b_RsErr_CPV: nonqueued-sender-com-spec{data-element=VeLINR_b_RsErr_CPV, init-value=VeLINR_b_RsErr_CPVValue:0}, provided-interface=VeLINR_b_RsErr_CPV
      VeLINR_b_RsErr_CPV_TO: nonqueued-sender-com-spec{data-element=VeLINR_b_RsErr_CPV_TO, init-value=VeLINR_b_RsErr_CPV_TOValue:0}, provided-interface=VeLINR_b_RsErr_CPV_TO
      VeLINR_I_AirHeatrICns: nonqueued-sender-com-spec{data-element=VeLINR_I_AirHeatrICns, init-value=VeLINR_I_AirHeatrICnsValue:63.75}, provided-interface=VeLINR_I_AirHeatrICns
      VeLINR_b_AirHeatrICnsTO: nonqueued-sender-com-spec{data-element=VeLINR_b_AirHeatrICnsTO, init-value=VeLINR_b_AirHeatrICnsTOValue:0}, provided-interface=VeLINR_b_AirHeatrICnsTO
      VeLINR_U_AirHeatrHVmeas: nonqueued-sender-com-spec{data-element=VeLINR_U_AirHeatrHVmeas, init-value=VeLINR_U_AirHeatrHVmeasValue:1023}, provided-interface=VeLINR_U_AirHeatrHVmeas
      VeLINR_b_AirHeatrHVmeasTO: nonqueued-sender-com-spec{data-element=VeLINR_b_AirHeatrHVmeasTO, init-value=VeLINR_b_AirHeatrHVmeasTOValue:0}, provided-interface=VeLINR_b_AirHeatrHVmeasTO
      VeLINR_T_AirHeatrPCBTemp: nonqueued-sender-com-spec{data-element=VeLINR_T_AirHeatrPCBTemp, init-value=VeLINR_T_AirHeatrPCBTempValue:215}, provided-interface=VeLINR_T_AirHeatrPCBTemp
      VeLINR_b_AirHeatrPCBTempTO: nonqueued-sender-com-spec{data-element=VeLINR_b_AirHeatrPCBTempTO, init-value=VeLINR_b_AirHeatrPCBTempTOValue:0}, provided-interface=VeLINR_b_AirHeatrPCBTempTO
      VeLINR_T_AirHeatrCoreTemp: nonqueued-sender-com-spec{data-element=VeLINR_T_AirHeatrCoreTemp, init-value=VeLINR_T_AirHeatrCoreTempValue:215}, provided-interface=VeLINR_T_AirHeatrCoreTemp
      VeLINR_b_AirHeatrCoreTempTO: nonqueued-sender-com-spec{data-element=VeLINR_b_AirHeatrCoreTempTO, init-value=VeLINR_b_AirHeatrCoreTempTOValue:0}, provided-interface=VeLINR_b_AirHeatrCoreTempTO
      VeLINR_b_RsErr_EAH: nonqueued-sender-com-spec{data-element=VeLINR_b_RsErr_EAH, init-value=VeLINR_b_RsErr_EAHValue:0}, provided-interface=VeLINR_b_RsErr_EAH
      VeLINR_b_RsErr_EAH_TO: nonqueued-sender-com-spec{data-element=VeLINR_b_RsErr_EAH_TO, init-value=VeLINR_b_RsErr_EAH_TOValue:0}, provided-interface=VeLINR_b_RsErr_EAH_TO
      VeLINR_e_AirHeatrWarnFltInCom: nonqueued-sender-com-spec{data-element=VeLINR_e_AirHeatrWarnFltInCom, init-value=VeLINR_e_AirHeatrWarnFltInComValue:3}, provided-interface=VeLINR_e_AirHeatrWarnFltInCom
      VeLINR_b_AirHeatrWarnFltInComTO: nonqueued-sender-com-spec{data-element=VeLINR_b_AirHeatrWarnFltInComTO, init-value=VeLINR_b_AirHeatrWarnFltInComTOValue:0}, provided-interface=VeLINR_b_AirHeatrWarnFltInComTO
      VeLINR_e_AirHeatrWarnHvOutOfRng: nonqueued-sender-com-spec{data-element=VeLINR_e_AirHeatrWarnHvOutOfRng, init-value=VeLINR_e_AirHeatrWarnHvOutOfRngValue:3}, provided-interface=VeLINR_e_AirHeatrWarnHvOutOfRng
      VeLINR_b_AirHeatrWarnHvOutOfRngTO: nonqueued-sender-com-spec{data-element=VeLINR_b_AirHeatrWarnHvOutOfRngTO, init-value=VeLINR_b_AirHeatrWarnHvOutOfRngTOValue:0}, provided-interface=VeLINR_b_AirHeatrWarnHvOutOfRngTO
      VeLINR_e_AirHtrWarnULoOutOfRng: nonqueued-sender-com-spec{data-element=VeLINR_e_AirHtrWarnULoOutOfRng, init-value=VeLINR_e_AirHtrWarnULoOutOfRngValue:3}, provided-interface=VeLINR_e_AirHtrWarnULoOutOfRng
      VeLINR_b_AirHtrWarnULoOutOfRngTO: nonqueued-sender-com-spec{data-element=VeLINR_b_AirHtrWarnULoOutOfRngTO, init-value=VeLINR_b_AirHtrWarnULoOutOfRngTOValue:0}, provided-interface=VeLINR_b_AirHtrWarnULoOutOfRngTO
      VeLINR_e_AirHtrWarnTmpOvrheatg: nonqueued-sender-com-spec{data-element=VeLINR_e_AirHtrWarnTmpOvrheatg, init-value=VeLINR_e_AirHtrWarnTmpOvrheatgValue:3}, provided-interface=VeLINR_e_AirHtrWarnTmpOvrheatg
      VeLINR_b_AirHtrWarnTmpOvrheatgTO: nonqueued-sender-com-spec{data-element=VeLINR_b_AirHtrWarnTmpOvrheatgTO, init-value=VeLINR_b_AirHtrWarnTmpOvrheatgTOValue:0}, provided-interface=VeLINR_b_AirHtrWarnTmpOvrheatgTO
      VeLINR_e_AirHtrWarnICnsOutOfRng: nonqueued-sender-com-spec{data-element=VeLINR_e_AirHtrWarnICnsOutOfRng, init-value=VeLINR_e_AirHtrWarnICnsOutOfRngValue:3}, provided-interface=VeLINR_e_AirHtrWarnICnsOutOfRng
      VeLINR_b_AirHtrWarnICnsOutOfRngTO: nonqueued-sender-com-spec{data-element=VeLINR_b_AirHtrWarnICnsOutOfRngTO, init-value=VeLINR_b_AirHtrWarnICnsOutOfRngTOValue:0}, provided-interface=VeLINR_b_AirHtrWarnICnsOutOfRngTO
      VeLINR_e_AirHeatrDmgIntHwProtn: nonqueued-sender-com-spec{data-element=VeLINR_e_AirHeatrDmgIntHwProtn, init-value=VeLINR_e_AirHeatrDmgIntHwProtnValue:3}, provided-interface=VeLINR_e_AirHeatrDmgIntHwProtn
      VeLINR_b_AirHeatrDmgIntHwProtnTO: nonqueued-sender-com-spec{data-element=VeLINR_b_AirHeatrDmgIntHwProtnTO, init-value=VeLINR_b_AirHeatrDmgIntHwProtnTOValue:0}, provided-interface=VeLINR_b_AirHeatrDmgIntHwProtnTO
      VeLINR_e_AirHtrDmgPCBTmpSnsrFlt: nonqueued-sender-com-spec{data-element=VeLINR_e_AirHtrDmgPCBTmpSnsrFlt, init-value=VeLINR_e_AirHtrDmgPCBTmpSnsrFltValue:3}, provided-interface=VeLINR_e_AirHtrDmgPCBTmpSnsrFlt
      VeLINR_b_AirHtrDmgPCBTmpSnsrFltTO: nonqueued-sender-com-spec{data-element=VeLINR_b_AirHtrDmgPCBTmpSnsrFltTO, init-value=VeLINR_b_AirHtrDmgPCBTmpSnsrFltTOValue:0}, provided-interface=VeLINR_b_AirHtrDmgPCBTmpSnsrFltTO
      VeLINR_e_AirHtrDmgCirDrvrShoOpn: nonqueued-sender-com-spec{data-element=VeLINR_e_AirHtrDmgCirDrvrShoOpn, init-value=VeLINR_e_AirHtrDmgCirDrvrShoOpnValue:3}, provided-interface=VeLINR_e_AirHtrDmgCirDrvrShoOpn
      VeLINR_b_AirHtrDmgCirDrvrShoOpnTO: nonqueued-sender-com-spec{data-element=VeLINR_b_AirHtrDmgCirDrvrShoOpnTO, init-value=VeLINR_b_AirHtrDmgCirDrvrShoOpnTOValue:0}, provided-interface=VeLINR_b_AirHtrDmgCirDrvrShoOpnTO
      VeLINR_e_AirHeatrDmgHVISnsrFlt: nonqueued-sender-com-spec{data-element=VeLINR_e_AirHeatrDmgHVISnsrFlt, init-value=VeLINR_e_AirHeatrDmgHVISnsrFltValue:3}, provided-interface=VeLINR_e_AirHeatrDmgHVISnsrFlt
      VeLINR_b_AirHeatrDmgHVISnsrFltTO: nonqueued-sender-com-spec{data-element=VeLINR_b_AirHeatrDmgHVISnsrFltTO, init-value=VeLINR_b_AirHeatrDmgHVISnsrFltTOValue:0}, provided-interface=VeLINR_b_AirHeatrDmgHVISnsrFltTO
      VeLINR_e_AirHeatrDmgMemErr: nonqueued-sender-com-spec{data-element=VeLINR_e_AirHeatrDmgMemErr, init-value=VeLINR_e_AirHeatrDmgMemErrValue:3}, provided-interface=VeLINR_e_AirHeatrDmgMemErr
      VeLINR_b_AirHeatrDmgMemErrTO: nonqueued-sender-com-spec{data-element=VeLINR_b_AirHeatrDmgMemErrTO, init-value=VeLINR_b_AirHeatrDmgMemErrTOValue:0}, provided-interface=VeLINR_b_AirHeatrDmgMemErrTO
      VeLINR_e_AirHtrDmgHtrCorTS_Flt: nonqueued-sender-com-spec{data-element=VeLINR_e_AirHtrDmgHtrCorTS_Flt, init-value=VeLINR_e_AirHtrDmgHtrCorTS_FltValue:3}, provided-interface=VeLINR_e_AirHtrDmgHtrCorTS_Flt
      VeLINR_b_AirHtrDmgHtrCorTS_FltTO: nonqueued-sender-com-spec{data-element=VeLINR_b_AirHtrDmgHtrCorTS_FltTO, init-value=VeLINR_b_AirHtrDmgHtrCorTS_FltTOValue:0}, provided-interface=VeLINR_b_AirHtrDmgHtrCorTS_FltTO
      VeLINR_e_AirHeatrWarnPCBOvrTmp: nonqueued-sender-com-spec{data-element=VeLINR_e_AirHeatrWarnPCBOvrTmp, init-value=VeLINR_e_AirHeatrWarnPCBOvrTmpValue:3}, provided-interface=VeLINR_e_AirHeatrWarnPCBOvrTmp
      VeLINR_b_AirHeatrWarnPCBOvrTmpTO: nonqueued-sender-com-spec{data-element=VeLINR_b_AirHeatrWarnPCBOvrTmpTO, init-value=VeLINR_b_AirHeatrWarnPCBOvrTmpTOValue:0}, provided-interface=VeLINR_b_AirHeatrWarnPCBOvrTmpTO
      VeLINR_e_AirHtrWrnHtrCorOvrTmp: nonqueued-sender-com-spec{data-element=VeLINR_e_AirHtrWrnHtrCorOvrTmp, init-value=VeLINR_e_AirHtrWrnHtrCorOvrTmpValue:3}, provided-interface=VeLINR_e_AirHtrWrnHtrCorOvrTmp
      VeLINR_b_AirHtrWrnHtrCorOvrTmpTO: nonqueued-sender-com-spec{data-element=VeLINR_b_AirHtrWrnHtrCorOvrTmpTO, init-value=VeLINR_b_AirHtrWrnHtrCorOvrTmpTOValue:0}, provided-interface=VeLINR_b_AirHtrWrnHtrCorOvrTmpTO
      VeLINR_e_EOPA_RPM_TGT: nonqueued-sender-com-spec{data-element=VeLINR_e_EOPA_RPM_TGT, init-value=VeLINR_e_EOPA_RPM_TGTValue:6120}, provided-interface=VeLINR_e_EOPA_RPM_TGT
      VeLINR_b_EOPA_RPM_TGT_TO: nonqueued-sender-com-spec{data-element=VeLINR_b_EOPA_RPM_TGT_TO, init-value=VeLINR_b_EOPA_RPM_TGT_TOValue:0}, provided-interface=VeLINR_b_EOPA_RPM_TGT_TO
      VeLINR_e_EOPA_RPM_ACTL: nonqueued-sender-com-spec{data-element=VeLINR_e_EOPA_RPM_ACTL, init-value=VeLINR_e_EOPA_RPM_ACTLValue:6120}, provided-interface=VeLINR_e_EOPA_RPM_ACTL
      VeLINR_b_EOPA_RPM_ACTL_TO: nonqueued-sender-com-spec{data-element=VeLINR_b_EOPA_RPM_ACTL_TO, init-value=VeLINR_b_EOPA_RPM_ACTL_TOValue:0}, provided-interface=VeLINR_b_EOPA_RPM_ACTL_TO
      VeLINR_U_EOPA_VLTG: nonqueued-sender-com-spec{data-element=VeLINR_U_EOPA_VLTG, init-value=VeLINR_U_EOPA_VLTGValue:25.5}, provided-interface=VeLINR_U_EOPA_VLTG
      VeLINR_b_EOPA_VLTG_TO: nonqueued-sender-com-spec{data-element=VeLINR_b_EOPA_VLTG_TO, init-value=VeLINR_b_EOPA_VLTG_TOValue:0}, provided-interface=VeLINR_b_EOPA_VLTG_TO
      VeLINR_T_EOPA_TEMP: nonqueued-sender-com-spec{data-element=VeLINR_T_EOPA_TEMP, init-value=VeLINR_T_EOPA_TEMPValue:205}, provided-interface=VeLINR_T_EOPA_TEMP
      VeLINR_b_EOPA_TEMP_TO: nonqueued-sender-com-spec{data-element=VeLINR_b_EOPA_TEMP_TO, init-value=VeLINR_b_EOPA_TEMP_TOValue:0}, provided-interface=VeLINR_b_EOPA_TEMP_TO
      VeLINR_I_EOPA_CURR: nonqueued-sender-com-spec{data-element=VeLINR_I_EOPA_CURR, init-value=VeLINR_I_EOPA_CURRValue:51}, provided-interface=VeLINR_I_EOPA_CURR
      VeLINR_b_EOPA_CURR_TO: nonqueued-sender-com-spec{data-element=VeLINR_b_EOPA_CURR_TO, init-value=VeLINR_b_EOPA_CURR_TOValue:0}, provided-interface=VeLINR_b_EOPA_CURR_TO
      VeLINR_e_EOPA_LOW_TMP_STAT: nonqueued-sender-com-spec{data-element=VeLINR_e_EOPA_LOW_TMP_STAT, init-value=VeLINR_e_EOPA_LOW_TMP_STATValue:3}, provided-interface=VeLINR_e_EOPA_LOW_TMP_STAT
      VeLINR_b_EOPA_LOW_TMP_STAT_TO: nonqueued-sender-com-spec{data-element=VeLINR_b_EOPA_LOW_TMP_STAT_TO, init-value=VeLINR_b_EOPA_LOW_TMP_STAT_TOValue:0}, provided-interface=VeLINR_b_EOPA_LOW_TMP_STAT_TO
      VeLINR_e_EOPA_MONTRNG_RPM: nonqueued-sender-com-spec{data-element=VeLINR_e_EOPA_MONTRNG_RPM, init-value=VeLINR_e_EOPA_MONTRNG_RPMValue:3}, provided-interface=VeLINR_e_EOPA_MONTRNG_RPM
      VeLINR_b_EOPA_MONTRNG_RPM_TO: nonqueued-sender-com-spec{data-element=VeLINR_b_EOPA_MONTRNG_RPM_TO, init-value=VeLINR_b_EOPA_MONTRNG_RPM_TOValue:0}, provided-interface=VeLINR_b_EOPA_MONTRNG_RPM_TO
      VeLINR_e_EOPA_LMP_HM_AN_ON: nonqueued-sender-com-spec{data-element=VeLINR_e_EOPA_LMP_HM_AN_ON, init-value=VeLINR_e_EOPA_LMP_HM_AN_ONValue:3}, provided-interface=VeLINR_e_EOPA_LMP_HM_AN_ON
      VeLINR_b_EOPA_LMP_HM_AN_ON_TO: nonqueued-sender-com-spec{data-element=VeLINR_b_EOPA_LMP_HM_AN_ON_TO, init-value=VeLINR_b_EOPA_LMP_HM_AN_ON_TOValue:0}, provided-interface=VeLINR_b_EOPA_LMP_HM_AN_ON_TO
      VeLINR_e_EOPA_OV_TMP_ER: nonqueued-sender-com-spec{data-element=VeLINR_e_EOPA_OV_TMP_ER, init-value=VeLINR_e_EOPA_OV_TMP_ERValue:3}, provided-interface=VeLINR_e_EOPA_OV_TMP_ER
      VeLINR_b_EOPA_OV_TMP_ER_TO: nonqueued-sender-com-spec{data-element=VeLINR_b_EOPA_OV_TMP_ER_TO, init-value=VeLINR_b_EOPA_OV_TMP_ER_TOValue:0}, provided-interface=VeLINR_b_EOPA_OV_TMP_ER_TO
      VeLINR_e_EOPA_OV_CUR_ER: nonqueued-sender-com-spec{data-element=VeLINR_e_EOPA_OV_CUR_ER, init-value=VeLINR_e_EOPA_OV_CUR_ERValue:3}, provided-interface=VeLINR_e_EOPA_OV_CUR_ER
      VeLINR_b_EOPA_OV_CUR_ER_TO: nonqueued-sender-com-spec{data-element=VeLINR_b_EOPA_OV_CUR_ER_TO, init-value=VeLINR_b_EOPA_OV_CUR_ER_TOValue:0}, provided-interface=VeLINR_b_EOPA_OV_CUR_ER_TO
      VeLINR_e_EOPA_DR_RN_ER: nonqueued-sender-com-spec{data-element=VeLINR_e_EOPA_DR_RN_ER, init-value=VeLINR_e_EOPA_DR_RN_ERValue:3}, provided-interface=VeLINR_e_EOPA_DR_RN_ER
      VeLINR_b_EOPA_DR_RN_ER_TO: nonqueued-sender-com-spec{data-element=VeLINR_b_EOPA_DR_RN_ER_TO, init-value=VeLINR_b_EOPA_DR_RN_ER_TOValue:0}, provided-interface=VeLINR_b_EOPA_DR_RN_ER_TO
      VeLINR_e_EOPA_VLTG_ER: nonqueued-sender-com-spec{data-element=VeLINR_e_EOPA_VLTG_ER, init-value=VeLINR_e_EOPA_VLTG_ERValue:3}, provided-interface=VeLINR_e_EOPA_VLTG_ER
      VeLINR_b_EOPA_VLTG_ER_TO: nonqueued-sender-com-spec{data-element=VeLINR_b_EOPA_VLTG_ER_TO, init-value=VeLINR_b_EOPA_VLTG_ER_TOValue:0}, provided-interface=VeLINR_b_EOPA_VLTG_ER_TO
      VeLINR_e_EOPA_Stall_Event: nonqueued-sender-com-spec{data-element=VeLINR_e_EOPA_Stall_Event, init-value=VeLINR_e_EOPA_Stall_EventValue:3}, provided-interface=VeLINR_e_EOPA_Stall_Event
      VeLINR_b_EOPA_Stall_EventTO: nonqueued-sender-com-spec{data-element=VeLINR_b_EOPA_Stall_EventTO, init-value=VeLINR_b_EOPA_Stall_EventTOValue:0}, provided-interface=VeLINR_b_EOPA_Stall_EventTO
      VeLINR_e_EOPA_POST_RUN_STAT: nonqueued-sender-com-spec{data-element=VeLINR_e_EOPA_POST_RUN_STAT, init-value=VeLINR_e_EOPA_POST_RUN_STATValue:7}, provided-interface=VeLINR_e_EOPA_POST_RUN_STAT
      VeLINR_b_EOPA_POST_RUN_STAT_TO: nonqueued-sender-com-spec{data-element=VeLINR_b_EOPA_POST_RUN_STAT_TO, init-value=VeLINR_b_EOPA_POST_RUN_STAT_TOValue:0}, provided-interface=VeLINR_b_EOPA_POST_RUN_STAT_TO
      VeLINR_b_RsErr_EOPA: nonqueued-sender-com-spec{data-element=VeLINR_b_RsErr_EOPA, init-value=VeLINR_b_RsErr_EOPAValue:0}, provided-interface=VeLINR_b_RsErr_EOPA
      VeLINR_b_RsErr_EOPA_TO: nonqueued-sender-com-spec{data-element=VeLINR_b_RsErr_EOPA_TO, init-value=VeLINR_b_RsErr_EOPA_TOValue:0}, provided-interface=VeLINR_b_RsErr_EOPA_TO
      VeLINR_T_EOPA_OIL_TEMP: nonqueued-sender-com-spec{data-element=VeLINR_T_EOPA_OIL_TEMP, init-value=VeLINR_T_EOPA_OIL_TEMPValue:205}, provided-interface=VeLINR_T_EOPA_OIL_TEMP
      VeLINR_b_EOPA_OIL_TEMP_TO: nonqueued-sender-com-spec{data-element=VeLINR_b_EOPA_OIL_TEMP_TO, init-value=VeLINR_b_EOPA_OIL_TEMP_TOValue:0}, provided-interface=VeLINR_b_EOPA_OIL_TEMP_TO
      VeLINR_y_EOPA_HW_VER: nonqueued-sender-com-spec{data-element=VeLINR_y_EOPA_HW_VER, init-value=VeLINR_y_EOPA_HW_VERValue:255}, provided-interface=VeLINR_y_EOPA_HW_VER
      VeLINR_b_EOPA_HW_VER_TO: nonqueued-sender-com-spec{data-element=VeLINR_b_EOPA_HW_VER_TO, init-value=VeLINR_b_EOPA_HW_VER_TOValue:0}, provided-interface=VeLINR_b_EOPA_HW_VER_TO
      VeLINR_y_EOPA_SW_VER: nonqueued-sender-com-spec{data-element=VeLINR_y_EOPA_SW_VER, init-value=VeLINR_y_EOPA_SW_VERValue:255}, provided-interface=VeLINR_y_EOPA_SW_VER
      VeLINR_b_EOPA_SW_VER_TO: nonqueued-sender-com-spec{data-element=VeLINR_b_EOPA_SW_VER_TO, init-value=VeLINR_b_EOPA_SW_VER_TOValue:0}, provided-interface=VeLINR_b_EOPA_SW_VER_TO
      VeLINR_Pct_LTRBV_PosAct: nonqueued-sender-com-spec{data-element=VeLINR_Pct_LTRBV_PosAct, init-value=VeLINR_Pct_LTRBV_PosActValue:0}, provided-interface=VeLINR_Pct_LTRBV_PosAct
      VeLINR_b_LTRBV_PosActTO: nonqueued-sender-com-spec{data-element=VeLINR_b_LTRBV_PosActTO, init-value=VeLINR_b_LTRBV_PosActTOValue:0}, provided-interface=VeLINR_b_LTRBV_PosActTO
      VeLINR_e_LTRBV_ERR: nonqueued-sender-com-spec{data-element=VeLINR_e_LTRBV_ERR, init-value=VeLINR_e_LTRBV_ERRValue:0}, provided-interface=VeLINR_e_LTRBV_ERR
      VeLINR_b_LTRBV_ERR_TO: nonqueued-sender-com-spec{data-element=VeLINR_b_LTRBV_ERR_TO, init-value=VeLINR_b_LTRBV_ERR_TOValue:0}, provided-interface=VeLINR_b_LTRBV_ERR_TO
      VeLINR_U_LTRBV_MotorVolt: nonqueued-sender-com-spec{data-element=VeLINR_U_LTRBV_MotorVolt, init-value=VeLINR_U_LTRBV_MotorVoltValue:0}, provided-interface=VeLINR_U_LTRBV_MotorVolt
      VeLINR_b_LTRBV_MotorVoltTO: nonqueued-sender-com-spec{data-element=VeLINR_b_LTRBV_MotorVoltTO, init-value=VeLINR_b_LTRBV_MotorVoltTOValue:0}, provided-interface=VeLINR_b_LTRBV_MotorVoltTO
      VeLINR_e_LTRBV_Sts: nonqueued-sender-com-spec{data-element=VeLINR_e_LTRBV_Sts, init-value=VeLINR_e_LTRBV_StsValue:0}, provided-interface=VeLINR_e_LTRBV_Sts
      VeLINR_b_LTRBV_StsTO: nonqueued-sender-com-spec{data-element=VeLINR_b_LTRBV_StsTO, init-value=VeLINR_b_LTRBV_StsTOValue:0}, provided-interface=VeLINR_b_LTRBV_StsTO
      VeLINR_b_RsErr_LTRBV: nonqueued-sender-com-spec{data-element=VeLINR_b_RsErr_LTRBV, init-value=VeLINR_b_RsErr_LTRBVValue:0}, provided-interface=VeLINR_b_RsErr_LTRBV
      VeLINR_b_RsErr_LTRBV_TO: nonqueued-sender-com-spec{data-element=VeLINR_b_RsErr_LTRBV_TO, init-value=VeLINR_b_RsErr_LTRBV_TOValue:0}, provided-interface=VeLINR_b_RsErr_LTRBV_TO
    16 x require port:
      SendLINR_AAD_PosRqVld: nonqueued-receiver-com-spec{data-element=SendLINR_AAD_PosRqVld, init-value=SendLINR_AAD_PosRqVldValue:1}, required-interface=SendLINR_AAD_PosRqVld
      SendLINR_AAD_CalRqVld: nonqueued-receiver-com-spec{data-element=SendLINR_AAD_CalRqVld, init-value=SendLINR_AAD_CalRqVldValue:1}, required-interface=SendLINR_AAD_CalRqVld
      SendLINR_AAD_InitialIP_CalRqVld: nonqueued-receiver-com-spec{data-element=SendLINR_AAD_InitialIP_CalRqVld, init-value=1}, required-interface=SendLINR_AAD_InitialIP_CalRqVld
      SendLINR_BCP_RPM_REQ_Vld: nonqueued-receiver-com-spec{data-element=SendLINR_BCP_RPM_REQ_Vld, init-value=SendLINR_BCP_RPM_REQ_VldValue:1}, required-interface=SendLINR_BCP_RPM_REQ_Vld
      SendLINR_BCP_POST_RUN_REQ_Vld: nonqueued-receiver-com-spec{data-element=SendLINR_BCP_POST_RUN_REQ_Vld, init-value=SendLINR_BCP_POST_RUN_REQ_VldValue:1}, required-interface=SendLINR_BCP_POST_RUN_REQ_Vld
      SendLINR_BCP_FL_SAFE_ACTVT_Vld: nonqueued-receiver-com-spec{data-element=SendLINR_BCP_FL_SAFE_ACTVT_Vld, init-value=SendLINR_BCP_FL_SAFE_ACTVT_VldValue:1}, required-interface=SendLINR_BCP_FL_SAFE_ACTVT_Vld
      SendLINR_CPV_PosRqVld: nonqueued-receiver-com-spec{data-element=SendLINR_CPV_PosRqVld, init-value=SendLINR_CPV_PosRqVldValue:1}, required-interface=SendLINR_CPV_PosRqVld
      SendLINR_CPV_PosSvVld: nonqueued-receiver-com-spec{data-element=SendLINR_CPV_PosSvVld, init-value=SendLINR_CPV_PosSvVldValue:1}, required-interface=SendLINR_CPV_PosSvVld
      SendLINR_CPV_CalRqVld: nonqueued-receiver-com-spec{data-element=SendLINR_CPV_CalRqVld, init-value=SendLINR_CPV_CalRqVldValue:1}, required-interface=SendLINR_CPV_CalRqVld
      SendLINR_AirHeatrPwrTgtVld: nonqueued-receiver-com-spec{data-element=SendLINR_AirHeatrPwrTgtVld, init-value=SendLINR_AirHeatrPwrTgtVldValue:1}, required-interface=SendLINR_AirHeatrPwrTgtVld
      SendLINR_AirHeatrEnadVld: nonqueued-receiver-com-spec{data-element=SendLINR_AirHeatrEnadVld, init-value=SendLINR_AirHeatrEnadVldValue:1}, required-interface=SendLINR_AirHeatrEnadVld
      SendLINR_EOPA_RPM_COM_Vld: nonqueued-receiver-com-spec{data-element=SendLINR_EOPA_RPM_COM_Vld, init-value=SendLINR_EOPA_RPM_COM_VldValue:1}, required-interface=SendLINR_EOPA_RPM_COM_Vld
      SendLINR_EOPA_POST_RUN_COM_Vld: nonqueued-receiver-com-spec{data-element=SendLINR_EOPA_POST_RUN_COM_Vld, init-value=SendLINR_EOPA_POST_RUN_COM_VldValue:1}, required-interface=SendLINR_EOPA_POST_RUN_COM_Vld
      SendLINR_LTRBV_PosRqVld: nonqueued-receiver-com-spec{data-element=SendLINR_LTRBV_PosRqVld, init-value=SendLINR_LTRBV_PosRqVldValue:1}, required-interface=SendLINR_LTRBV_PosRqVld
      SendLINR_LTRBV_PosSvVld: nonqueued-receiver-com-spec{data-element=SendLINR_LTRBV_PosSvVld, init-value=SendLINR_LTRBV_PosSvVldValue:1}, required-interface=SendLINR_LTRBV_PosSvVld
      SendLINR_LTRBV_CalRqVld: nonqueued-receiver-com-spec{data-element=SendLINR_LTRBV_CalRqVld, init-value=SendLINR_LTRBV_CalRqVldValue:1}, required-interface=SendLINR_LTRBV_CalRqVld
    54 x provide port:
      VeLINR_y_AHP_VERSION: nonqueued-sender-com-spec{data-element=VeLINR_y_AHP_VERSION, init-value=VeLINR_y_AHP_VERSIONValue:255}, provided-interface=VeLINR_y_AHP_VERSION
      VeLINR_b_AHP_VERSION_TO: nonqueued-sender-com-spec{data-element=VeLINR_b_AHP_VERSION_TO, init-value=VeLINR_b_AHP_VERSION_TOValue:0}, provided-interface=VeLINR_b_AHP_VERSION_TO
      VeLINR_y_PECP_VERSION: nonqueued-sender-com-spec{data-element=VeLINR_y_PECP_VERSION, init-value=VeLINR_y_PECP_VERSIONValue:255}, provided-interface=VeLINR_y_PECP_VERSION
      VeLINR_b_PECP_VERSION_TO: nonqueued-sender-com-spec{data-element=VeLINR_b_PECP_VERSION_TO, init-value=VeLINR_b_PECP_VERSION_TOValue:0}, provided-interface=VeLINR_b_PECP_VERSION_TO
      VeLINR_U_CPV_MotorVolt: nonqueued-sender-com-spec{data-element=VeLINR_U_CPV_MotorVolt, init-value=VeLINR_U_CPV_MotorVoltValue:0}, provided-interface=VeLINR_U_CPV_MotorVolt
      VeLINR_b_CPV_MotorVoltTO: nonqueued-sender-com-spec{data-element=VeLINR_b_CPV_MotorVoltTO, init-value=VeLINR_b_CPV_MotorVoltTOValue:0}, provided-interface=VeLINR_b_CPV_MotorVoltTO
      VeLINR_e_CPV_CalStat: nonqueued-sender-com-spec{data-element=VeLINR_e_CPV_CalStat, init-value=VeLINR_e_CPV_CalStatValue:0}, provided-interface=VeLINR_e_CPV_CalStat
      VeLINR_b_CPV_CalStatTO: nonqueued-sender-com-spec{data-element=VeLINR_b_CPV_CalStatTO, init-value=VeLINR_b_CPV_CalStatTOValue:0}, provided-interface=VeLINR_b_CPV_CalStatTO
      VeLINR_e_AirHeatrSts: nonqueued-sender-com-spec{data-element=VeLINR_e_AirHeatrSts, init-value=VeLINR_e_AirHeatrStsValue:0}, provided-interface=VeLINR_e_AirHeatrSts
      VeLINR_b_AirHeatrStsTO: nonqueued-sender-com-spec{data-element=VeLINR_b_AirHeatrStsTO, init-value=VeLINR_b_AirHeatrStsTOValue:0}, provided-interface=VeLINR_b_AirHeatrStsTO
      VeLINR_Pct_AirHeatrPwrCns: nonqueued-sender-com-spec{data-element=VeLINR_Pct_AirHeatrPwrCns, init-value=VeLINR_Pct_AirHeatrPwrCnsValue:255}, provided-interface=VeLINR_Pct_AirHeatrPwrCns
      VeLINR_b_AirHeatrPwrCnsTO: nonqueued-sender-com-spec{data-element=VeLINR_b_AirHeatrPwrCnsTO, init-value=VeLINR_b_AirHeatrPwrCnsTOValue:0}, provided-interface=VeLINR_b_AirHeatrPwrCnsTO
      VeLINR_Pct_EEXV_PosAct: nonqueued-sender-com-spec{data-element=VeLINR_Pct_EEXV_PosAct, init-value=VeLINR_Pct_EEXV_PosActValue:0}, provided-interface=VeLINR_Pct_EEXV_PosAct
      VeLINR_b_EEXV_PosActTO: nonqueued-sender-com-spec{data-element=VeLINR_b_EEXV_PosActTO, init-value=VeLINR_b_EEXV_PosActTOValue:0}, provided-interface=VeLINR_b_EEXV_PosActTO
      VeLINR_e_EEXV_CalStat: nonqueued-sender-com-spec{data-element=VeLINR_e_EEXV_CalStat, init-value=VeLINR_e_EEXV_CalStatValue:0}, provided-interface=VeLINR_e_EEXV_CalStat
      VeLINR_b_EEXV_CalStatTO: nonqueued-sender-com-spec{data-element=VeLINR_b_EEXV_CalStatTO, init-value=VeLINR_b_EEXV_CalStatTOValue:0}, provided-interface=VeLINR_b_EEXV_CalStatTO
      VeLINR_b_EEXV_CalRq: nonqueued-sender-com-spec{data-element=VeLINR_b_EEXV_CalRq, init-value=VeLINR_b_EEXV_CalRqValue:0}, provided-interface=VeLINR_b_EEXV_CalRq
      VeLINR_b_EEXV_CalRqTO: nonqueued-sender-com-spec{data-element=VeLINR_b_EEXV_CalRqTO, init-value=VeLINR_b_EEXV_CalRqTOValue:0}, provided-interface=VeLINR_b_EEXV_CalRqTO
      VeLINR_b_RsErr_EEXV: nonqueued-sender-com-spec{data-element=VeLINR_b_RsErr_EEXV, init-value=VeLINR_b_RsErr_EEXVValue:0}, provided-interface=VeLINR_b_RsErr_EEXV
      VeLINR_b_RsErr_EEXV_TO: nonqueued-sender-com-spec{data-element=VeLINR_b_RsErr_EEXV_TO, init-value=VeLINR_b_RsErr_EEXV_TOValue:0}, provided-interface=VeLINR_b_RsErr_EEXV_TO
      VeLINR_e_EEXV_Sts: nonqueued-sender-com-spec{data-element=VeLINR_e_EEXV_Sts, init-value=VeLINR_e_EEXV_StsValue:0}, provided-interface=VeLINR_e_EEXV_Sts
      VeLINR_b_EEXV_StsTO: nonqueued-sender-com-spec{data-element=VeLINR_b_EEXV_StsTO, init-value=VeLINR_b_EEXV_StsTOValue:0}, provided-interface=VeLINR_b_EEXV_StsTO
      VeLINR_e_EEXV_ERR: nonqueued-sender-com-spec{data-element=VeLINR_e_EEXV_ERR, init-value=VeLINR_e_EEXV_ERRValue:0}, provided-interface=VeLINR_e_EEXV_ERR
      VeLINR_b_EEXV_ERR_TO: nonqueued-sender-com-spec{data-element=VeLINR_b_EEXV_ERR_TO, init-value=VeLINR_b_EEXV_ERR_TOValue:0}, provided-interface=VeLINR_b_EEXV_ERR_TO
      VeLINR_U_EEXV_SupplyVolt: nonqueued-sender-com-spec{data-element=VeLINR_U_EEXV_SupplyVolt, init-value=VeLINR_U_EEXV_SupplyVoltValue:0}, provided-interface=VeLINR_U_EEXV_SupplyVolt
      VeLINR_b_EEXV_SupplyVoltTO: nonqueued-sender-com-spec{data-element=VeLINR_b_EEXV_SupplyVoltTO, init-value=VeLINR_b_EEXV_SupplyVoltTOValue:0}, provided-interface=VeLINR_b_EEXV_SupplyVoltTO
      VeLINR_e_EEXV_Refrig_Pressure: nonqueued-sender-com-spec{data-element=VeLINR_e_EEXV_Refrig_Pressure, init-value=VeLINR_e_EEXV_Refrig_PressureValue:1638.3}, provided-interface=VeLINR_e_EEXV_Refrig_Pressure
      VeLINR_b_EEXV_Refrig_PressureTO: nonqueued-sender-com-spec{data-element=VeLINR_b_EEXV_Refrig_PressureTO, init-value=VeLINR_b_EEXV_Refrig_PressureTOValue:0}, provided-interface=VeLINR_b_EEXV_Refrig_PressureTO
      VeLINR_T_EEXV_Board_Temp: nonqueued-sender-com-spec{data-element=VeLINR_T_EEXV_Board_Temp, init-value=VeLINR_T_EEXV_Board_TempValue:-40}, provided-interface=VeLINR_T_EEXV_Board_Temp
      VeLINR_b_EEXV_Board_TempTO: nonqueued-sender-com-spec{data-element=VeLINR_b_EEXV_Board_TempTO, init-value=VeLINR_b_EEXV_Board_TempTOValue:0}, provided-interface=VeLINR_b_EEXV_Board_TempTO
      VeLINR_e_EEXV_Refrigerant_Temp: nonqueued-sender-com-spec{data-element=VeLINR_e_EEXV_Refrigerant_Temp, init-value=VeLINR_e_EEXV_Refrigerant_TempValue:-40}, provided-interface=VeLINR_e_EEXV_Refrigerant_Temp
      VeLINR_b_EEXV_Refrigerant_TempTO: nonqueued-sender-com-spec{data-element=VeLINR_b_EEXV_Refrigerant_TempTO, init-value=VeLINR_b_EEXV_Refrigerant_TempTOValue:0}, provided-interface=VeLINR_b_EEXV_Refrigerant_TempTO
      VeLINR_Pct_EXVM_PosAct: nonqueued-sender-com-spec{data-element=VeLINR_Pct_EXVM_PosAct, init-value=VeLINR_Pct_EXVM_PosActValue:0}, provided-interface=VeLINR_Pct_EXVM_PosAct
      VeLINR_b_EXVM_PosActTO: nonqueued-sender-com-spec{data-element=VeLINR_b_EXVM_PosActTO, init-value=VeLINR_b_EXVM_PosActTOValue:0}, provided-interface=VeLINR_b_EXVM_PosActTO
      VeLINR_e_EXVM_CalStat: nonqueued-sender-com-spec{data-element=VeLINR_e_EXVM_CalStat, init-value=VeLINR_e_EXVM_CalStatValue:0}, provided-interface=VeLINR_e_EXVM_CalStat
      VeLINR_b_EXVM_CalStatTO: nonqueued-sender-com-spec{data-element=VeLINR_b_EXVM_CalStatTO, init-value=VeLINR_b_EXVM_CalStatTOValue:0}, provided-interface=VeLINR_b_EXVM_CalStatTO
      VeLINR_b_EXVM_CalRq: nonqueued-sender-com-spec{data-element=VeLINR_b_EXVM_CalRq, init-value=VeLINR_b_EXVM_CalRqValue:0}, provided-interface=VeLINR_b_EXVM_CalRq
      VeLINR_b_EXVM_CalRqTO: nonqueued-sender-com-spec{data-element=VeLINR_b_EXVM_CalRqTO, init-value=VeLINR_b_EXVM_CalRqTOValue:0}, provided-interface=VeLINR_b_EXVM_CalRqTO
      VeLINR_b_RsErr_EXVM: nonqueued-sender-com-spec{data-element=VeLINR_b_RsErr_EXVM, init-value=VeLINR_b_RsErr_EXVMValue:0}, provided-interface=VeLINR_b_RsErr_EXVM
      VeLINR_b_RsErr_EXVM_TO: nonqueued-sender-com-spec{data-element=VeLINR_b_RsErr_EXVM_TO, init-value=VeLINR_b_RsErr_EXVM_TOValue:0}, provided-interface=VeLINR_b_RsErr_EXVM_TO
      VeLINR_e_EXVM_Sts: nonqueued-sender-com-spec{data-element=VeLINR_e_EXVM_Sts, init-value=VeLINR_e_EXVM_StsValue:0}, provided-interface=VeLINR_e_EXVM_Sts
      VeLINR_b_EXVM_StsTO: nonqueued-sender-com-spec{data-element=VeLINR_b_EXVM_StsTO, init-value=VeLINR_b_EXVM_StsTOValue:0}, provided-interface=VeLINR_b_EXVM_StsTO
      VeLINR_e_EXVM_ERR: nonqueued-sender-com-spec{data-element=VeLINR_e_EXVM_ERR, init-value=VeLINR_e_EXVM_ERRValue:0}, provided-interface=VeLINR_e_EXVM_ERR
      VeLINR_b_EXVM_ERR_TO: nonqueued-sender-com-spec{data-element=VeLINR_b_EXVM_ERR_TO, init-value=VeLINR_b_EXVM_ERR_TOValue:0}, provided-interface=VeLINR_b_EXVM_ERR_TO
      VeLINR_U_EXVM_SupplyVolt: nonqueued-sender-com-spec{data-element=VeLINR_U_EXVM_SupplyVolt, init-value=VeLINR_U_EXVM_SupplyVoltValue:0}, provided-interface=VeLINR_U_EXVM_SupplyVolt
      VeLINR_b_EXVM_SupplyVoltTO: nonqueued-sender-com-spec{data-element=VeLINR_b_EXVM_SupplyVoltTO, init-value=VeLINR_b_EXVM_SupplyVoltTOValue:0}, provided-interface=VeLINR_b_EXVM_SupplyVoltTO
      VeLINR_e_EXVM_Refrig_Pressure: nonqueued-sender-com-spec{data-element=VeLINR_e_EXVM_Refrig_Pressure, init-value=VeLINR_e_EXVM_Refrig_PressureValue:1638.3}, provided-interface=VeLINR_e_EXVM_Refrig_Pressure
      VeLINR_b_EXVM_Refrig_PressureTO: nonqueued-sender-com-spec{data-element=VeLINR_b_EXVM_Refrig_PressureTO, init-value=VeLINR_b_EXVM_Refrig_PressureTOValue:0}, provided-interface=VeLINR_b_EXVM_Refrig_PressureTO
      VeLINR_T_EXVM_Board_Temp: nonqueued-sender-com-spec{data-element=VeLINR_T_EXVM_Board_Temp, init-value=VeLINR_T_EXVM_Board_TempValue:-40}, provided-interface=VeLINR_T_EXVM_Board_Temp
      VeLINR_b_EXVM_Board_TempTO: nonqueued-sender-com-spec{data-element=VeLINR_b_EXVM_Board_TempTO, init-value=VeLINR_b_EXVM_Board_TempTOValue:0}, provided-interface=VeLINR_b_EXVM_Board_TempTO
      VeLINR_e_EXVM_Refrigerant_Temp: nonqueued-sender-com-spec{data-element=VeLINR_e_EXVM_Refrigerant_Temp, init-value=VeLINR_e_EXVM_Refrigerant_TempValue:-40}, provided-interface=VeLINR_e_EXVM_Refrigerant_Temp
      VeLINR_b_EXVM_Refrigerant_TempTO: nonqueued-sender-com-spec{data-element=VeLINR_b_EXVM_Refrigerant_TempTO, init-value=VeLINR_b_EXVM_Refrigerant_TempTOValue:0}, provided-interface=VeLINR_b_EXVM_Refrigerant_TempTO
      VeLINR_e_LTRBV_CalStat: nonqueued-sender-com-spec{data-element=VeLINR_e_LTRBV_CalStat, init-value=VeLINR_e_LTRBV_CalStatValue:0}, provided-interface=VeLINR_e_LTRBV_CalStat
      VeLINR_b_LTRBV_CalStatTO: nonqueued-sender-com-spec{data-element=VeLINR_b_LTRBV_CalStatTO, init-value=VeLINR_b_LTRBV_CalStatTOValue:0}, provided-interface=VeLINR_b_LTRBV_CalStatTO
    8 x require port:
      SendLINR_EEXV_PosRq: nonqueued-receiver-com-spec{data-element=SendLINR_EEXV_PosRq, init-value=SendLINR_EEXV_PosRqValue:0}, required-interface=SendLINR_EEXV_PosRq
      SendLINR_EEXV_PosRqVld: nonqueued-receiver-com-spec{data-element=SendLINR_EEXV_PosRqVld, init-value=SendLINR_EEXV_PosRqVldValue:1}, required-interface=SendLINR_EEXV_PosRqVld
      SendLINR_EEXV_CalCmd: nonqueued-receiver-com-spec{data-element=SendLINR_EEXV_CalCmd, init-value=SendLINR_EEXV_CalCmdValue:0}, required-interface=SendLINR_EEXV_CalCmd
      SendLINR_EEXV_CalCmdVld: nonqueued-receiver-com-spec{data-element=SendLINR_EEXV_CalCmdVld, init-value=SendLINR_EEXV_CalCmdVldValue:1}, required-interface=SendLINR_EEXV_CalCmdVld
      SendLINR_EXVM_PosRq: nonqueued-receiver-com-spec{data-element=SendLINR_EXVM_PosRq, init-value=SendLINR_EXVM_PosRqValue:0}, required-interface=SendLINR_EXVM_PosRq
      SendLINR_EXVM_PosRqVld: nonqueued-receiver-com-spec{data-element=SendLINR_EXVM_PosRqVld, init-value=SendLINR_EXVM_PosRqVldValue:1}, required-interface=SendLINR_EXVM_PosRqVld
      SendLINR_EXVM_CalCmd: nonqueued-receiver-com-spec{data-element=SendLINR_EXVM_CalCmd, init-value=SendLINR_EXVM_CalCmdValue:0}, required-interface=SendLINR_EXVM_CalCmd
      SendLINR_EXVM_CalCmdVld: nonqueued-receiver-com-spec{data-element=SendLINR_EXVM_CalCmdVld, init-value=SendLINR_EXVM_CalCmdVldValue:1}, required-interface=SendLINR_EXVM_CalCmdVld
    28 x provide port:
      VeLINR_e_S2MResByte1_AGS2: nonqueued-sender-com-spec{data-element=VeLINR_e_S2MResByte1_AGS2, init-value=VeLINR_e_S2MResByte1_AGS2Value:0}, provided-interface=VeLINR_e_S2MResByte1_AGS2
      VeLINR_b_S2MResByte1_AGS2TO: nonqueued-sender-com-spec{data-element=VeLINR_b_S2MResByte1_AGS2TO, init-value=VeLINR_b_S2MResByte1_AGS2TOValue:0}, provided-interface=VeLINR_b_S2MResByte1_AGS2TO
      VeLINR_e_S2MResByte2_AGS2: nonqueued-sender-com-spec{data-element=VeLINR_e_S2MResByte2_AGS2, init-value=VeLINR_e_S2MResByte2_AGS2Value:0}, provided-interface=VeLINR_e_S2MResByte2_AGS2
      VeLINR_b_S2MResByte2_AGS2TO: nonqueued-sender-com-spec{data-element=VeLINR_b_S2MResByte2_AGS2TO, init-value=VeLINR_b_S2MResByte2_AGS2TOValue:0}, provided-interface=VeLINR_b_S2MResByte2_AGS2TO
      VeLINR_U_BHV_MotorVolt: nonqueued-sender-com-spec{data-element=VeLINR_U_BHV_MotorVolt, init-value=VeLINR_U_BHV_MotorVoltValue:0}, provided-interface=VeLINR_U_BHV_MotorVolt
      VeLINR_b_BHV_MotorVoltTO: nonqueued-sender-com-spec{data-element=VeLINR_b_BHV_MotorVoltTO, init-value=VeLINR_b_BHV_MotorVoltTOValue:0}, provided-interface=VeLINR_b_BHV_MotorVoltTO
      VeLINR_e_BHV_CalStat: nonqueued-sender-com-spec{data-element=VeLINR_e_BHV_CalStat, init-value=VeLINR_e_BHV_CalStatValue:0}, provided-interface=VeLINR_e_BHV_CalStat
      VeLINR_b_BHV_CalStatTO: nonqueued-sender-com-spec{data-element=VeLINR_b_BHV_CalStatTO, init-value=VeLINR_b_BHV_CalStatTOValue:0}, provided-interface=VeLINR_b_BHV_CalStatTO
      VeLINR_Pct_OEXV_PosAct: nonqueued-sender-com-spec{data-element=VeLINR_Pct_OEXV_PosAct, init-value=VeLINR_Pct_OEXV_PosActValue:0}, provided-interface=VeLINR_Pct_OEXV_PosAct
      VeLINR_b_OEXV_PosActTO: nonqueued-sender-com-spec{data-element=VeLINR_b_OEXV_PosActTO, init-value=VeLINR_b_OEXV_PosActTOValue:0}, provided-interface=VeLINR_b_OEXV_PosActTO
      VeLINR_e_OEXV_CalStat: nonqueued-sender-com-spec{data-element=VeLINR_e_OEXV_CalStat, init-value=VeLINR_e_OEXV_CalStatValue:0}, provided-interface=VeLINR_e_OEXV_CalStat
      VeLINR_b_OEXV_CalStatTO: nonqueued-sender-com-spec{data-element=VeLINR_b_OEXV_CalStatTO, init-value=VeLINR_b_OEXV_CalStatTOValue:0}, provided-interface=VeLINR_b_OEXV_CalStatTO
      VeLINR_b_OEXV_CalRq: nonqueued-sender-com-spec{data-element=VeLINR_b_OEXV_CalRq, init-value=VeLINR_b_OEXV_CalRqValue:0}, provided-interface=VeLINR_b_OEXV_CalRq
      VeLINR_b_OEXV_CalRqTO: nonqueued-sender-com-spec{data-element=VeLINR_b_OEXV_CalRqTO, init-value=VeLINR_b_OEXV_CalRqTOValue:0}, provided-interface=VeLINR_b_OEXV_CalRqTO
      VeLINR_b_RsErr_OEXV: nonqueued-sender-com-spec{data-element=VeLINR_b_RsErr_OEXV, init-value=VeLINR_b_RsErr_OEXVValue:0}, provided-interface=VeLINR_b_RsErr_OEXV
      VeLINR_b_RsErr_OEXV_TO: nonqueued-sender-com-spec{data-element=VeLINR_b_RsErr_OEXV_TO, init-value=VeLINR_b_RsErr_OEXV_TOValue:0}, provided-interface=VeLINR_b_RsErr_OEXV_TO
      VeLINR_e_OEXV_Sts: nonqueued-sender-com-spec{data-element=VeLINR_e_OEXV_Sts, init-value=VeLINR_e_OEXV_StsValue:0}, provided-interface=VeLINR_e_OEXV_Sts
      VeLINR_b_OEXV_StsTO: nonqueued-sender-com-spec{data-element=VeLINR_b_OEXV_StsTO, init-value=VeLINR_b_OEXV_StsTOValue:0}, provided-interface=VeLINR_b_OEXV_StsTO
      VeLINR_e_OEXV_ERR: nonqueued-sender-com-spec{data-element=VeLINR_e_OEXV_ERR, init-value=VeLINR_e_OEXV_ERRValue:0}, provided-interface=VeLINR_e_OEXV_ERR
      VeLINR_b_OEXV_ERR_TO: nonqueued-sender-com-spec{data-element=VeLINR_b_OEXV_ERR_TO, init-value=VeLINR_b_OEXV_ERR_TOValue:0}, provided-interface=VeLINR_b_OEXV_ERR_TO
      VeLINR_U_OEXV_SupplyVolt: nonqueued-sender-com-spec{data-element=VeLINR_U_OEXV_SupplyVolt, init-value=VeLINR_U_OEXV_SupplyVoltValue:0}, provided-interface=VeLINR_U_OEXV_SupplyVolt
      VeLINR_b_OEXV_SupplyVoltTO: nonqueued-sender-com-spec{data-element=VeLINR_b_OEXV_SupplyVoltTO, init-value=VeLINR_b_OEXV_SupplyVoltTOValue:0}, provided-interface=VeLINR_b_OEXV_SupplyVoltTO
      VeLINR_e_OEXV_Refrig_Pres: nonqueued-sender-com-spec{data-element=VeLINR_e_OEXV_Refrig_Pres, init-value=VeLINR_e_OEXV_Refrig_PresValue:8191.5}, provided-interface=VeLINR_e_OEXV_Refrig_Pres
      VeLINR_b_OEXV_Refrig_PresTO: nonqueued-sender-com-spec{data-element=VeLINR_b_OEXV_Refrig_PresTO, init-value=VeLINR_b_OEXV_Refrig_PresTOValue:0}, provided-interface=VeLINR_b_OEXV_Refrig_PresTO
      VeLINR_T_OEXV_Board_Temp: nonqueued-sender-com-spec{data-element=VeLINR_T_OEXV_Board_Temp, init-value=VeLINR_T_OEXV_Board_TempValue:-40}, provided-interface=VeLINR_T_OEXV_Board_Temp
      VeLINR_b_OEXV_Board_TempTO: nonqueued-sender-com-spec{data-element=VeLINR_b_OEXV_Board_TempTO, init-value=VeLINR_b_OEXV_Board_TempTOValue:0}, provided-interface=VeLINR_b_OEXV_Board_TempTO
      VeLINR_e_OEXV_Refrigerant_Temp: nonqueued-sender-com-spec{data-element=VeLINR_e_OEXV_Refrigerant_Temp, init-value=VeLINR_e_OEXV_Refrigerant_TempValue:-40}, provided-interface=VeLINR_e_OEXV_Refrigerant_Temp
      VeLINR_b_OEXV_Refrigerant_TempTO: nonqueued-sender-com-spec{data-element=VeLINR_b_OEXV_Refrigerant_TempTO, init-value=VeLINR_b_OEXV_Refrigerant_TempTOValue:0}, provided-interface=VeLINR_b_OEXV_Refrigerant_TempTO
    4 x require port:
      SendLINR_OEXV_PosRq: nonqueued-receiver-com-spec{data-element=SendLINR_OEXV_PosRq, init-value=SendLINR_OEXV_PosRqValue:0}, required-interface=SendLINR_OEXV_PosRq
      SendLINR_OEXV_PosRqVld: nonqueued-receiver-com-spec{data-element=SendLINR_OEXV_PosRqVld, init-value=SendLINR_OEXV_PosRqVldValue:1}, required-interface=SendLINR_OEXV_PosRqVld
      SendLINR_OEXV_CalCmd: nonqueued-receiver-com-spec{data-element=SendLINR_OEXV_CalCmd, init-value=SendLINR_OEXV_CalCmdValue:0}, required-interface=SendLINR_OEXV_CalCmd
      SendLINR_OEXV_CalCmdVld: nonqueued-receiver-com-spec{data-element=SendLINR_OEXV_CalCmdVld, init-value=SendLINR_OEXV_CalCmdVldValue:1}, required-interface=SendLINR_OEXV_CalCmdVld
